VERSION "BO_HSCAN"

NS_ :

BS_:

BU_: BCM_Gp CCF_Server DDM DRDM DSM FTCM FTCMB GWM LPDM PDM PRDM PSM RFA RGTM RGTMB RLSM RPDM RRSM TBM TSTR VIM Virtual_Node WDCM Vector_XXX

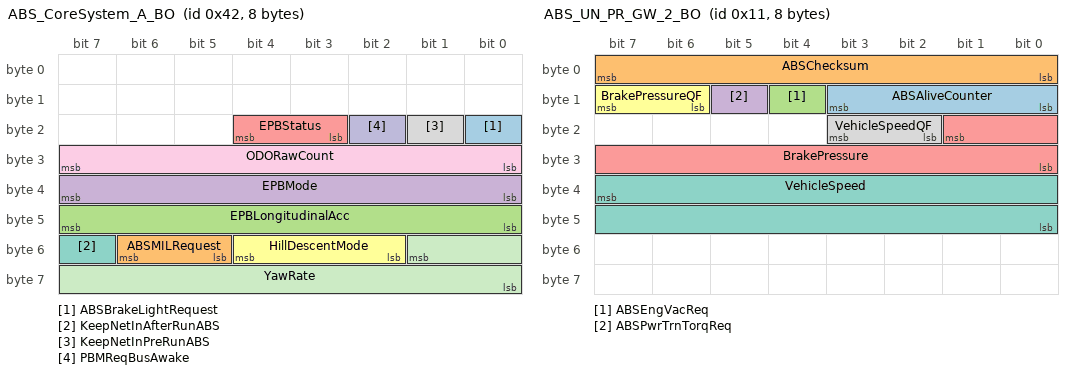
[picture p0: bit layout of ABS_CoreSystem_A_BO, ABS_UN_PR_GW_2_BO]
BO_ 66 ABS_CoreSystem_A_BO: 8 GWM
 SG_ ABSBrakeLightRequest : 16|1@0+ (1,0) [0|1] ""  BCM_Gp
 SG_ ABSMILRequest : 54|2@0+ (1,0) [0|3] ""  Vector_XXX
 SG_ EPBLongitudinalAcc : 47|8@0+ (0.1,-11) [-11|11] "m/s/s"  Vector_XXX
 SG_ EPBMode : 39|8@0+ (1,0) [0|255] ""  Vector_XXX
 SG_ EPBStatus : 20|2@0+ (1,0) [0|3] ""  BCM_Gp,DSM,LPDM,PSM,RLSM,RPDM,RRSM,TBM
 SG_ HillDescentMode : 52|3@0+ (1,0) [0|7] ""  Vector_XXX
 SG_ KeepNetInAfterRunABS : 55|1@0+ (1,0) [0|1] ""  BCM_Gp
 SG_ KeepNetInPreRunABS : 17|1@0+ (1,0) [0|1] ""  Vector_XXX
 SG_ ODORawCount : 31|8@0+ (1,0) [0|255] "Counter value"  Vector_XXX
 SG_ PBMReqBusAwake : 18|1@0+ (1,0) [0|1] ""  BCM_Gp
 SG_ YawRate : 49|10@0+ (0.2,-100) [-100|100] "Degrees/second"  BCM_Gp

BO_ 17 ABS_UN_PR_GW_2_BO: 8 GWM
 SG_ ABSAliveCounter : 11|4@0+ (1,0) [0|15] "Counter"  BCM_Gp,DSM,PSM,RGTM,VIM
 SG_ ABSChecksum : 7|8@0+ (1,0) [0|255] "CRC8 Checksum"  BCM_Gp,DSM,PSM,RGTM,VIM
 SG_ ABSEngVacReq : 12|1@0+ (1,0) [0|1] ""  BCM_Gp,DSM,PSM,RGTM,VIM
 SG_ ABSPwrTrnTorqReq : 13|1@0+ (1,0) [0|1] ""  BCM_Gp,DSM,FTCM,PSM,RGTM,VIM
 SG_ BrakePressure : 17|10@0+ (0.2,0) [0|204.6] "Bar"  BCM_Gp,DSM,LPDM,PSM,RGTM,RPDM,VIM
 SG_ BrakePressureQF : 15|2@0+ (1,0) [0|3] ""  BCM_Gp,DSM,PSM,RGTM,VIM
 SG_ VehicleSpeed : 39|16@0+ (0.01,0) [0|320] "kph"  BCM_Gp,DDM,DRDM,DSM,FTCM,LPDM,PDM,PRDM,PSM,RFA,RGTM,RGTMB,RLSM,RPDM,RRSM,TBM,VIM
 SG_ VehicleSpeedQF : 19|2@0+ (1,0) [0|3] ""  BCM_Gp,DDM,DRDM,DSM,FTCM,PDM,PRDM,PSM,RFA,RGTM,RGTMB,RLSM,RRSM,VIM

BO_ 1281 BCM_NM501LS: 8 BCM_Gp
 SG_ NMmessageBCMLS : 7|64@0+ (1,0) [0|1.84467440737096E+019] ""  Virtual_Node

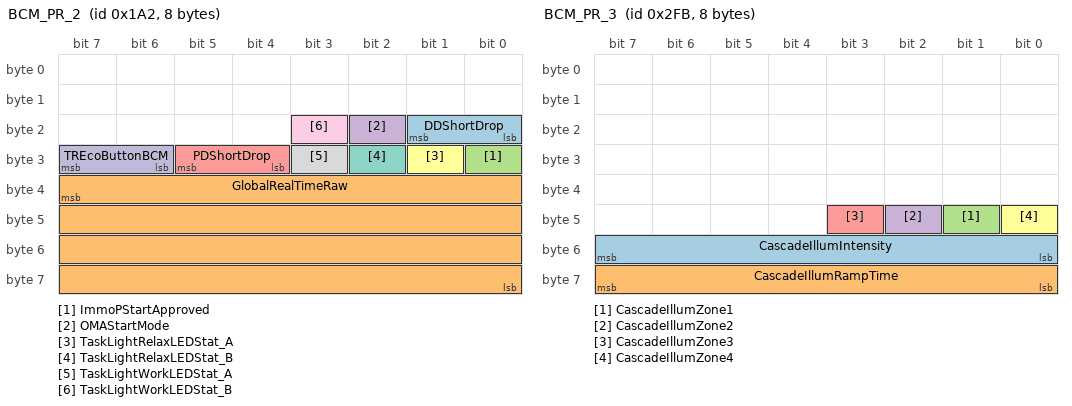
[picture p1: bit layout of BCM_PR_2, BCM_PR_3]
BO_ 418 BCM_PR_2: 8 BCM_Gp
 SG_ DDShortDrop : 17|2@0+ (1,0) [0|3] ""  DDM
 SG_ GlobalRealTimeRaw : 39|32@0+ (1,0) [0|4294967295] ""  GWM
 SG_ ImmoPStartApproved : 24|1@0+ (1,0) [0|1] ""  RFA
 SG_ OMAStartMode : 18|1@0+ (1,0) [0|1] ""  RFA
 SG_ PDShortDrop : 29|2@0+ (1,0) [0|3] ""  PDM
 SG_ TaskLightRelaxLEDStat_A : 25|1@0+ (1,0) [0|1] ""  DRDM,PRDM
 SG_ TaskLightRelaxLEDStat_B : 26|1@0+ (1,0) [0|1] ""  DRDM,PRDM
 SG_ TaskLightWorkLEDStat_A : 27|1@0+ (1,0) [0|1] ""  DRDM,PRDM
 SG_ TaskLightWorkLEDStat_B : 19|1@0+ (1,0) [0|1] ""  DRDM,PRDM
 SG_ TREcoButtonBCM : 31|2@0+ (1,0) [0|3] ""  GWM

BO_ 763 BCM_PR_3: 8 BCM_Gp
 SG_ CascadeIllumIntensity : 55|8@0+ (0.3937,0) [0|99.9998] "Backlight Intensity %"  Virtual_Node
 SG_ CascadeIllumRampTime : 63|8@0+ (10,0) [0|2540] "mSec"  Virtual_Node
 SG_ CascadeIllumZone1 : 41|1@0+ (1,0) [0|1] ""  Virtual_Node
 SG_ CascadeIllumZone2 : 42|1@0+ (1,0) [0|1] ""  Virtual_Node
 SG_ CascadeIllumZone3 : 43|1@0+ (1,0) [0|1] ""  Virtual_Node
 SG_ CascadeIllumZone4 : 40|1@0+ (1,0) [0|1] ""  Virtual_Node

BO_ 255 BCM_PR_GW_1: 8 BCM_Gp
 SG_ CarMode : 27|4@0+ (1,0) [0|15] ""  DDM,DRDM,DSM,GWM,PDM,PRDM,PSM,RFA,RGTM,RGTMB,RLSM,RRSM
 SG_ CentralLockLastCmdOrig : 55|4@0+ (1,0) [0|15] ""  DDM,DRDM,GWM,PDM,PRDM,RFA
 SG_ DIFunctionStatus : 44|5@0+ (1,0) [0|31] ""  GWM
 SG_ DirectionIndicationSwitch : 47|3@0+ (1,0) [0|7] ""  GWM
 SG_ ExtLgtAutoTellTaleRq : 33|2@0+ (1,0) [0|3] ""  GWM
 SG_ HeadlampSequenceReq : 50|3@0+ (1,0) [0|7] ""  GWM
 SG_ MainBeamIndication : 51|1@0+ (1,0) [0|1] ""  GWM
 SG_ MHSwitchStatusBCM : 59|2@0+ (1,0) [0|3] ""  GWM
 SG_ PowerMode : 20|5@0+ (1,0) [0|31] ""  DDM,DRDM,DSM,FTCM,FTCMB,GWM,LPDM,PDM,PRDM,PSM,RFA,RGTM,RGTMB,RLSM,RPDM,RRSM,TBM,VIM,WDCM
 SG_ PowerModeAliveCounter : 11|4@0+ (1,0) [0|15] "Counter"  GWM
 SG_ PowerModeChecksum : 7|8@0+ (1,0) [0|255] "Counter"  GWM
 SG_ PowerModeQF : 22|2@0+ (1,0) [0|3] ""  DDM,DRDM,GWM,PDM,PRDM
 SG_ RemoteEngStartDrivPres : 31|1@0+ (1,0) [0|1] ""  GWM
 SG_ RemoteFunctionStatus : 15|4@0+ (1,0) [3|14] "Reserved"  GWM
 SG_ RemoteStartStatusMS : 23|1@0+ (1,0) [0|1] ""  DDM,GWM,PDM
 SG_ ReversedGear : 60|1@0+ (1,0) [0|1] ""  DDM,DRDM,GWM,PDM,PRDM
 SG_ RunningStandby : 56|1@0+ (1,0) [0|1] ""  DSM,FTCM,FTCMB,GWM,PSM,RGTM,RGTMB,RRSM
 SG_ StartModeReq : 63|3@0+ (1,0) [0|7] ""  GWM
 SG_ StartSwitchPressed : 57|1@0+ (1,0) [0|1] ""  GWM
 SG_ TransitState : 28|1@0+ (1,0) [0|1] ""  DDM,DRDM,FTCM,FTCMB,GWM,PDM,PRDM,RGTM,RGTMB

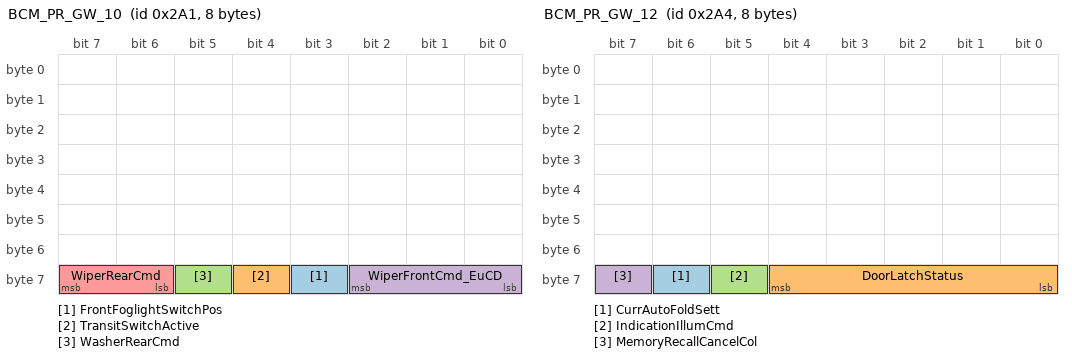
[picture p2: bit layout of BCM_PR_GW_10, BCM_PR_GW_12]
BO_ 673 BCM_PR_GW_10: 8 BCM_Gp
 SG_ FrontFoglightSwitchPos : 59|1@0+ (1,0) [0|1] ""  GWM
 SG_ TransitSwitchActive : 60|1@0+ (1,0) [0|1] ""  RRSM
 SG_ WasherRearCmd : 61|1@0+ (1,0) [0|1] ""  GWM
 SG_ WiperFrontCmd_EuCD : 58|3@0+ (1,0) [0|7] ""  GWM
 SG_ WiperRearCmd : 63|2@0+ (1,0) [0|3] ""  GWM

BO_ 675 BCM_PR_GW_11: 8 BCM_Gp
 SG_ AFSWarningLamp : 37|2@0+ (1,0) [0|3] ""  GWM
 SG_ EngineStartSeqMsgReq : 35|3@0+ (1,0) [0|7] ""  GWM
 SG_ EngineStartWarningReq : 38|1@0+ (1,0) [0|1] ""  GWM
 SG_ EngineStopReqWarning : 39|1@0+ (1,0) [0|1] ""  GWM
 SG_ EngineStopWarningMsg : 41|2@0+ (1,0) [0|3] ""  GWM
 SG_ GestureBlindStatus : 42|1@0+ (1,0) [0|1] ""  GWM
 SG_ HeadLampStatus : 43|1@0+ (1,0) [0|1] ""  GWM
 SG_ IgnitionOnWarning : 44|1@0+ (1,0) [0|1] ""  GWM
 SG_ PKeyDockedWarning : 32|1@0+ (1,0) [0|1] ""  GWM
 SG_ RearFoglightIndication : 18|2@0+ (1,0) [0|3] ""  GWM
 SG_ RheostatPositionCmd : 23|4@0+ (1,0) [0|15] "Illumination level"  DDM,GWM
 SG_ SelectParkWarning : 19|1@0+ (1,0) [0|1] ""  GWM
 SG_ SensorOverrideStatus : 24|1@0+ (1,0) [0|1] ""  GWM
 SG_ SmartKeyDeactivatedReq : 25|1@0+ (1,0) [0|1] ""  GWM
 SG_ StartAndBrakeWarning : 12|1@0+ (1,0) [0|1] ""  GWM
 SG_ StartAndClutchWarning : 13|1@0+ (1,0) [0|1] ""  GWM
 SG_ StartStop1Warning : 14|1@0+ (1,0) [0|1] ""  GWM
 SG_ StartStop2Warning : 15|1@0+ (1,0) [0|1] ""  GWM
 SG_ TgateOrGlassStatus : 26|1@0+ (1,0) [0|1] ""  GWM
 SG_ TripButtonStatus : 31|4@0+ (1,0) [0|15] ""  GWM
 SG_ ValetModeChimeAndMsgReq : 27|1@0+ (1,0) [0|1] ""  GWM
 SG_ WasherFluidLevelWarning : 16|1@0+ (1,0) [0|1] ""  GWM

BO_ 676 BCM_PR_GW_12: 8 BCM_Gp
 SG_ CurrAutoFoldSett : 62|1@0+ (1,0) [0|1] ""  DDM
 SG_ DoorLatchStatus : 60|5@0+ (1,0) [0|31] "See description"  DDM,DRDM,GWM,PDM,PRDM,RFA,RGTM,RGTMB
 SG_ IndicationIllumCmd : 61|1@0+ (1,0) [0|1] ""  DDM,PDM
 SG_ MemoryRecallCancelCol : 63|1@0+ (1,0) [0|1] ""  DDM,DSM,PDM

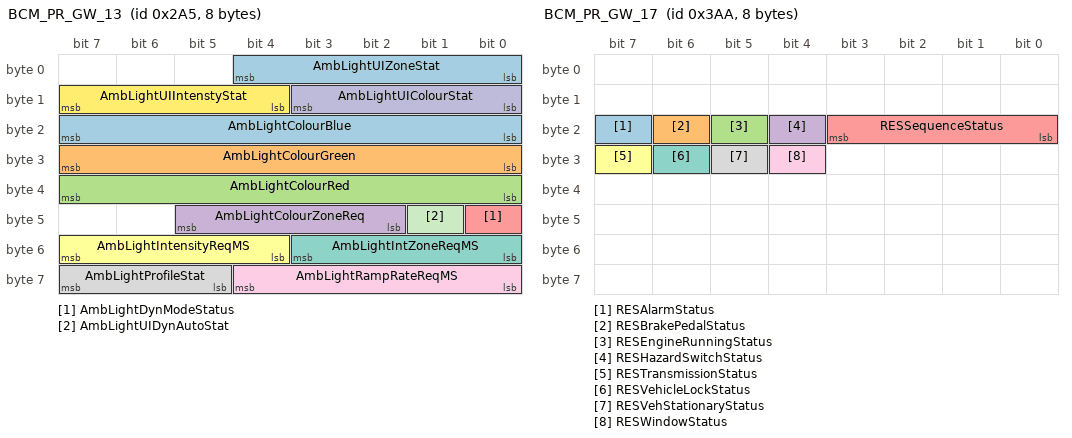
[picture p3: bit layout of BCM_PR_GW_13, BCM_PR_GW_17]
BO_ 677 BCM_PR_GW_13: 8 BCM_Gp
 SG_ AmbLightColourBlue : 23|8@0+ (1,0) [0|255] "Colour intensity"  DDM,DRDM,GWM,PDM,PRDM
 SG_ AmbLightColourGreen : 31|8@0+ (1,0) [0|255] "Colour intensity"  DDM,DRDM,GWM,PDM,PRDM
 SG_ AmbLightColourRed : 39|8@0+ (1,0) [0|255] "Colour intensity"  DDM,DRDM,GWM,PDM,PRDM
 SG_ AmbLightColourZoneReq : 45|4@0+ (1,0) [0|15] ""  DDM,DRDM,GWM,PDM,PRDM
 SG_ AmbLightDynModeStatus : 40|1@0+ (1,0) [0|1] ""  GWM
 SG_ AmbLightIntensityReqMS : 55|4@0+ (1,0) [0|15] "Light intensity"  DDM,DRDM,GWM,PDM,PRDM
 SG_ AmbLightIntZoneReqMS : 51|4@0+ (1,0) [0|15] ""  DDM,DRDM,GWM,PDM,PRDM
 SG_ AmbLightProfileStat : 63|3@0+ (1,0) [0|7] ""  DDM,DRDM,GWM,PDM,PRDM
 SG_ AmbLightRampRateReqMS : 60|5@0+ (0.2,0) [0|6.2] "Seconds"  DDM,DRDM,GWM,PDM,PRDM
 SG_ AmbLightUIColourStat : 11|4@0+ (1,0) [0|15] ""  GWM
 SG_ AmbLightUIDynAutoStat : 41|1@0+ (1,0) [0|1] ""  GWM
 SG_ AmbLightUIIntenstyStat : 15|4@0+ (1,0) [0|15] "Brightness level"  GWM
 SG_ AmbLightUIZoneStat : 4|5@0+ (1,0) [0|31] ""  GWM

BO_ 678 BCM_PR_GW_14: 8 BCM_Gp
 SG_ ComfortRlyOffImminent : 33|1@0+ (1,0) [0|1] ""  DSM,LPDM,PSM,RLSM,RPDM,RRSM
 SG_ DipBeamStatus : 34|1@0+ (1,0) [0|1] ""  GWM
 SG_ DipMirrSetngApp : 35|1@0+ (1,0) [0|1] ""  Virtual_Node
 SG_ ExtLightSetngAppl : 44|1@0+ (1,0) [0|1] ""  Virtual_Node
 SG_ GotoEntryExitPos : 37|2@0+ (1,0) [0|3] ""  DSM
 SG_ HFSStatus : 39|2@0+ (1,0) [0|3] ""  GWM
 SG_ HRWStatus : 47|2@0+ (1,0) [0|3] ""  GWM
 SG_ IgnoreLatchOnUnlock : 45|1@0+ (1,0) [0|1] ""  RFA
 SG_ IntLightSetngAppl : 43|1@0+ (1,0) [0|1] ""  Virtual_Node
 SG_ POTailgateLatchStatus : 12|1@0+ (1,0) [0|1] ""  RFA,RGTM,RGTMB
 SG_ POTLatchStatLwrLHS : 13|1@0+ (1,0) [0|1] ""  RGTM,RGTMB
 SG_ POTLatchStatLwrRHS : 14|1@0+ (1,0) [0|1] ""  RGTM,RGTMB
 SG_ PrivateLockStatus : 15|1@0+ (1,0) [0|1] ""  RFA,RGTM,RGTMB
 SG_ PwrTGOpenCloseReq : 19|4@0+ (1,0) [0|15] ""  RGTM,RGTMB
 SG_ PwrTGOpenCloseReqLwr : 23|4@0+ (1,0) [0|15] ""  RGTM,RGTMB
 SG_ PwrTGUpperAndLwrReq : 27|4@0+ (1,0) [0|15] ""  RGTM,RGTMB
 SG_ TrailerFogLights : 28|1@0+ (1,0) [0|1] ""  TBM
 SG_ TrailerReverseLights : 29|1@0+ (1,0) [0|1] ""  TBM
 SG_ TrailerTailLightsL : 30|1@0+ (1,0) [0|1] ""  TBM
 SG_ TrailerTailLightsR : 31|1@0+ (1,0) [0|1] ""  TBM
 SG_ UserStartReq : 32|1@0+ (1,0) [0|1] ""  GWM

BO_ 679 BCM_PR_GW_15: 8 BCM_Gp
 SG_ MinuteCounter : 39|32@0+ (1,0) [0|4294967295] ""  GWM

BO_ 681 BCM_PR_GW_16: 8 BCM_Gp
 SG_ UserSetTimeDate : 23|48@0+ (1,0) [0|281474976710655] ""  GWM

BO_ 938 BCM_PR_GW_17: 8 BCM_Gp
 SG_ RESAlarmStatus : 23|1@0+ (1,0) [0|1] ""  GWM
 SG_ RESBrakePedalStatus : 22|1@0+ (1,0) [0|1] ""  GWM
 SG_ RESEngineRunningStatus : 21|1@0+ (1,0) [0|1] ""  GWM
 SG_ RESHazardSwitchStatus : 20|1@0+ (1,0) [0|1] ""  GWM
 SG_ RESSequenceStatus : 19|4@0+ (1,0) [1|14] "reserved"  GWM
 SG_ RESTransmissionStatus : 31|1@0+ (1,0) [0|1] ""  GWM
 SG_ RESVehicleLockStatus : 30|1@0+ (1,0) [0|1] ""  GWM
 SG_ RESVehStationaryStatus : 29|1@0+ (1,0) [0|1] ""  GWM
 SG_ RESWindowStatus : 28|1@0+ (1,0) [0|1] ""  GWM

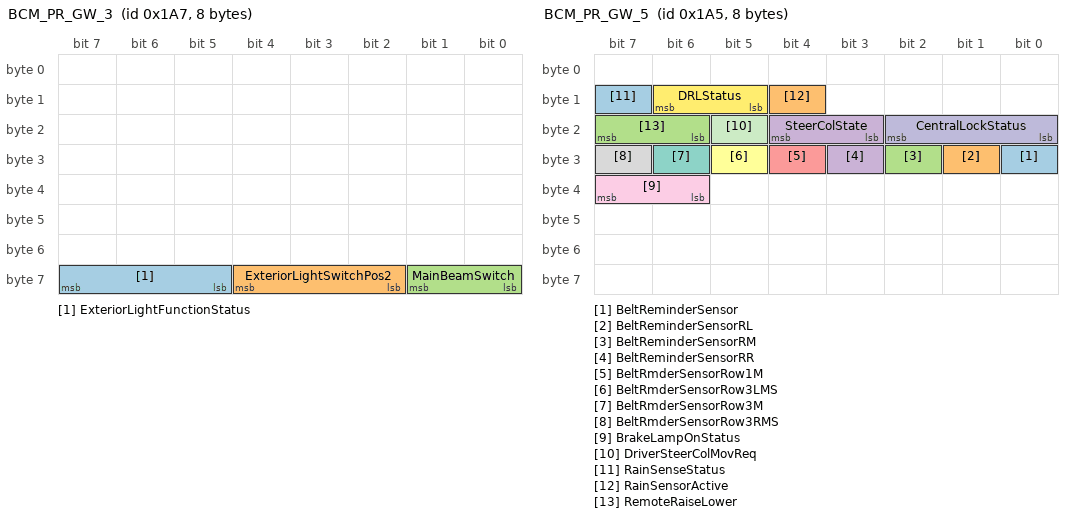
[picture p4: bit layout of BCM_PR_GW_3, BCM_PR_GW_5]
BO_ 423 BCM_PR_GW_3: 8 BCM_Gp
 SG_ ExteriorLightFunctionStatus : 63|3@0+ (1,0) [0|7] ""  GWM
 SG_ ExteriorLightSwitchPos2 : 60|3@0+ (1,0) [5|7] "Unsed"  GWM
 SG_ MainBeamSwitch : 57|2@0+ (1,0) [0|3] ""  GWM

BO_ 420 BCM_PR_GW_4: 8 BCM_Gp
 SG_ DiagHeadLightFault : 29|1@0+ (1,0) [0|1] ""  GWM
 SG_ DirectionIndSwitchPos : 33|2@0+ (1,0) [0|3] ""  GWM
 SG_ FLDirectionIndicatorBulbFail : 1|2@0+ (1,0) [0|3] ""  GWM
 SG_ FRDirectionIndicatorBulbFail : 3|2@0+ (1,0) [0|3] ""  GWM
 SG_ LeftStopLampBulbFailure : 5|2@0+ (1,0) [0|3] ""  GWM
 SG_ LowBeamFailureLH : 16|1@0+ (1,0) [0|1] ""  GWM
 SG_ LowBeamFailureRH : 17|1@0+ (1,0) [0|1] ""  GWM
 SG_ LSMAlsDippedBeamReqB : 18|1@0+ (1,0) [0|1] ""  GWM
 SG_ MainBeamStatus : 20|2@0+ (1,0) [0|3] ""  GWM
 SG_ NaturalLight : 21|1@0+ (1,0) [0|1] ""  GWM
 SG_ RightStopLampBulbFailure : 7|2@0+ (1,0) [0|3] ""  GWM
 SG_ RLDirectionIndicatorBulbFail : 9|2@0+ (1,0) [0|3] ""  GWM
 SG_ RLPositionLampBulbFailure : 11|2@0+ (1,0) [0|3] ""  GWM
 SG_ RRDirectionIndicatorBulbFail : 13|2@0+ (1,0) [0|3] ""  GWM
 SG_ RRPositionLampBulbFailure : 15|2@0+ (1,0) [0|3] ""  GWM
 SG_ SCLWarningReq : 23|2@0+ (1,0) [0|3] ""  GWM
 SG_ SidelightStatus : 25|2@0+ (1,0) [0|3] ""  GWM
 SG_ SupMainBeamRoutineReq : 31|2@0+ (1,0) [0|3] ""  GWM
 SG_ WipeSpeedRainSensor : 28|3@0+ (1,0) [0|7] ""  GWM

BO_ 421 BCM_PR_GW_5: 8 BCM_Gp
 SG_ BeltReminderSensor : 24|1@0+ (1,0) [0|1] ""  GWM,LPDM,PSM,RPDM
 SG_ BeltReminderSensorRL : 25|1@0+ (1,0) [0|1] ""  DSM,GWM,LPDM,PSM,RLSM,RPDM
 SG_ BeltReminderSensorRM : 26|1@0+ (1,0) [0|1] ""  DSM,GWM,LPDM,PSM,RLSM,RPDM,RRSM
 SG_ BeltReminderSensorRR : 27|1@0+ (1,0) [0|1] ""  DSM,GWM,LPDM,PSM,RPDM,RRSM
 SG_ BeltRmderSensorRow1M : 28|1@0+ (1,0) [0|1] ""  GWM
 SG_ BeltRmderSensorRow3LMS : 29|1@0+ (1,0) [0|1] ""  DSM,GWM,PSM
 SG_ BeltRmderSensorRow3M : 30|1@0+ (1,0) [0|1] ""  GWM
 SG_ BeltRmderSensorRow3RMS : 31|1@0+ (1,0) [0|1] ""  DSM,GWM,PSM
 SG_ BrakeLampOnStatus : 39|2@0+ (1,0) [0|3] ""  GWM
 SG_ CentralLockStatus : 18|3@0+ (1,0) [5|7] "Unused (Undefined)"  GWM,RFA,RGTM,RGTMB
 SG_ DriverSteerColMovReq : 21|1@0+ (1,0) [0|1] ""  GWM
 SG_ DRLStatus : 14|2@0+ (1,0) [0|3] ""  GWM
 SG_ RainSenseStatus : 15|1@0+ (1,0) [0|1] ""  GWM
 SG_ RainSensorActive : 12|1@0+ (1,0) [0|1] ""  GWM
 SG_ RemoteRaiseLower : 23|2@0+ (1,0) [0|3] ""  GWM
 SG_ SteerColState : 20|2@0+ (1,0) [0|3] ""  GWM

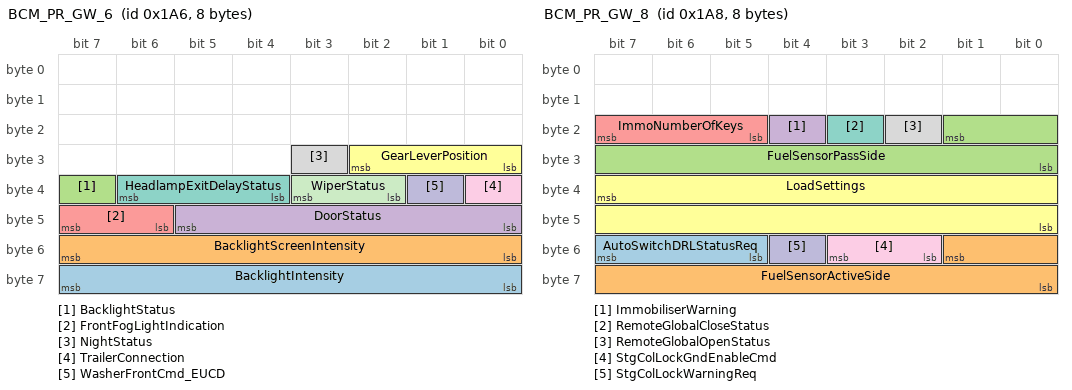
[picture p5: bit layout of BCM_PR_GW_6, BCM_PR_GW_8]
BO_ 422 BCM_PR_GW_6: 8 BCM_Gp
 SG_ BacklightIntensity : 63|8@0+ (0.3937,0) [0|99.9998] "Backlight Intensity %"  DDM,DRDM,DSM,GWM,PDM,PRDM,PSM,RLSM,RRSM
 SG_ BacklightScreenIntensity : 55|8@0+ (0.3937,0) [0|99.9998] "Backlight Intensity %"  GWM
 SG_ BacklightStatus : 39|1@0+ (1,0) [0|1] ""  DDM,DRDM,DSM,GWM,PDM,PRDM,PSM,RLSM,RRSM
 SG_ DoorStatus : 45|6@0+ (1,0) [0|63] "See Description"  DDM,DRDM,DSM,FTCM,GWM,LPDM,PDM,PRDM,PSM,RFA,RGTM,RGTMB,RLSM,RPDM,RRSM,TBM,WDCM
 SG_ FrontFogLightIndication : 47|2@0+ (1,0) [0|3] ""  GWM
 SG_ GearLeverPosition : 26|3@0+ (1,0) [0|7] ""  DDM,DRDM,GWM,PDM,PRDM
 SG_ HeadlampExitDelayStatus : 38|3@0+ (1,0) [6|7] "Unused (Undefined)"  GWM
 SG_ NightStatus : 27|1@0+ (1,0) [0|1] ""  GWM
 SG_ TrailerConnection : 32|1@0+ (1,0) [0|1] ""  GWM,TBM
 SG_ WasherFrontCmd_EUCD : 33|1@0+ (1,0) [0|1] ""  GWM
 SG_ WiperStatus : 35|2@0+ (1,0) [0|3] ""  GWM

BO_ 935 BCM_PR_GW_7: 8 BCM_Gp
 SG_ AmbientLightValueRLS : 39|8@0+ (1,0) [0|253] "Counts"  GWM
 SG_ AutoBlindEnableStatus : 7|1@0+ (1,0) [0|1] ""  GWM
 SG_ BatteryStateText : 31|3@0+ (1,0) [0|7] ""  GWM
 SG_ BCM_EPBWarningLamp : 12|1@0+ (1,0) [0|1] ""  GWM
 SG_ BrakeFluidLevelWarning : 13|1@0+ (1,0) [0|1] ""  GWM
 SG_ BrakePadWearLampReq : 14|1@0+ (1,0) [0|1] ""  GWM
 SG_ CarModeText : 18|3@0+ (1,0) [0|7] ""  GWM
 SG_ CoolantLevel : 15|1@0+ (1,0) [0|1] ""  GWM
 SG_ HomeSafeLightInd : 19|1@0+ (1,0) [0|1] ""  GWM
 SG_ OdometerBackUp_BCM : 47|24@0+ (1,0) [0|16777215] ""  GWM
 SG_ ParkClimateReq : 20|1@0+ (1,0) [0|1] ""  GWM
 SG_ PosLightInd : 21|1@0+ (1,0) [0|1] ""  GWM
 SG_ SunroofOpen : 28|1@0+ (1,0) [0|1] ""  GWM
 SG_ TrailerLightTestActive : 22|1@0+ (1,0) [0|1] ""  GWM
 SG_ TRStatus : 27|2@0+ (1,0) [0|3] ""  DSM,GWM,PSM,RLSM
 SG_ ValetStatus : 23|1@0+ (1,0) [0|1] ""  GWM
 SG_ WasherFluidLevelLow : 24|1@0+ (1,0) [0|1] ""  GWM
 SG_ WashingCycleActive_s : 25|1@0+ (1,0) [0|1] ""  GWM

BO_ 424 BCM_PR_GW_8: 8 BCM_Gp
 SG_ AutoSwitchDRLStatusReq : 55|3@0+ (1,0) [0|7] ""  GWM
 SG_ FuelSensorActiveSide : 49|10@0+ (1,0) [0|1023] "Raw ADC reading"  GWM
 SG_ FuelSensorPassSide : 17|10@0+ (1,0) [0|1023] "Raw ADC reading"  GWM
 SG_ ImmobiliserWarning : 20|1@0+ (1,0) [0|1] ""  GWM
 SG_ ImmoNumberOfKeys : 23|3@0+ (1,0) [0|7] ""  GWM
 SG_ LoadSettings : 39|16@0+ (1,0) [0|65535] ""  DDM,DRDM,GWM,PDM,PRDM,RRSM
 SG_ RemoteGlobalCloseStatus : 19|1@0+ (1,0) [0|1] ""  GWM
 SG_ RemoteGlobalOpenStatus : 18|1@0+ (1,0) [0|1] ""  GWM
 SG_ StgColLockGndEnableCmd : 51|2@0+ (1,0) [0|3] ""  GWM
 SG_ StgColLockWarningReq : 52|1@0+ (1,0) [0|1] ""  GWM

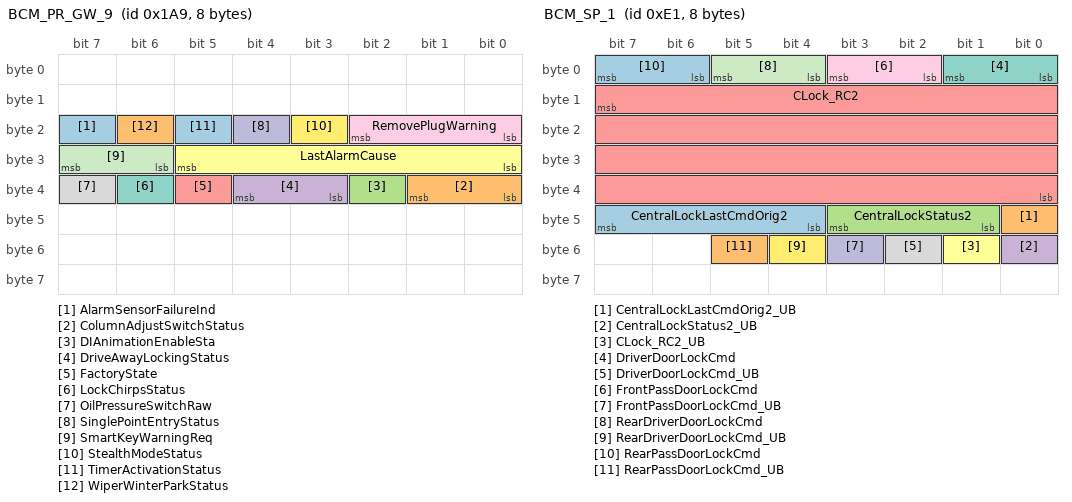
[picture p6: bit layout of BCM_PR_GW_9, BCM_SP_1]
BO_ 425 BCM_PR_GW_9: 8 BCM_Gp
 SG_ AlarmSensorFailureInd : 23|1@0+ (1,0) [0|1] ""  GWM
 SG_ ColumnAdjustSwitchStatus : 33|2@0+ (1,0) [0|3] ""  GWM
 SG_ DIAnimationEnableSta : 34|1@0+ (1,0) [0|1] ""  GWM
 SG_ DriveAwayLockingStatus : 36|2@0+ (1,0) [0|3] ""  GWM
 SG_ FactoryState : 37|1@0+ (1,0) [0|1] ""  GWM
 SG_ LastAlarmCause : 29|6@0+ (1,0) [23|63] "Unused"  GWM
 SG_ LockChirpsStatus : 38|1@0+ (1,0) [0|1] ""  GWM
 SG_ OilPressureSwitchRaw : 39|1@0+ (1,0) [0|1] ""  GWM
 SG_ RemovePlugWarning : 18|3@0+ (1,0) [0|7] ""  GWM
 SG_ SinglePointEntryStatus : 20|1@0+ (1,0) [0|1] ""  GWM
 SG_ SmartKeyWarningReq : 31|2@0+ (1,0) [0|3] ""  GWM
 SG_ StealthModeStatus : 19|1@0+ (1,0) [0|1] ""  GWM
 SG_ TimerActivationStatus : 21|1@0+ (1,0) [0|1] ""  GWM
 SG_ WiperWinterParkStatus : 22|1@0+ (1,0) [0|1] ""  GWM

BO_ 225 BCM_SP_1: 8 BCM_Gp
 SG_ CentralLockLastCmdOrig2 : 47|4@0+ (1,0) [0|15] ""  DDM,DRDM,PDM,PRDM,RGTM,RGTMB
 SG_ CentralLockLastCmdOrig2_UB : 40|1@0+ (1,0) [0|1] ""  DDM,DRDM,PDM,PRDM,RGTM,RGTMB
 SG_ CentralLockStatus2 : 43|3@0+ (1,0) [5|7] "Unused (Undefined)"  DDM,DRDM,PDM,PRDM,RGTM,RGTMB
 SG_ CentralLockStatus2_UB : 48|1@0+ (1,0) [0|1] ""  DDM,DRDM,PDM,PRDM,RGTM,RGTMB
 SG_ CLock_RC2 : 15|32@0+ (1,0) [0|4294967295] ""  DDM,DRDM,PDM,PRDM,RGTM,RGTMB
 SG_ CLock_RC2_UB : 49|1@0+ (1,0) [0|1] ""  DDM,DRDM,PDM,PRDM,RGTM,RGTMB
 SG_ DriverDoorLockCmd : 1|2@0+ (1,0) [0|3] ""  DDM,DRDM,PDM,PRDM,RGTM,RGTMB
 SG_ DriverDoorLockCmd_UB : 50|1@0+ (1,0) [0|1] ""  DDM,DRDM,PDM,PRDM,RGTM,RGTMB
 SG_ FrontPassDoorLockCmd : 3|2@0+ (1,0) [0|3] ""  DDM,DRDM,PDM,PRDM,RGTM,RGTMB
 SG_ FrontPassDoorLockCmd_UB : 51|1@0+ (1,0) [0|1] ""  DDM,DRDM,PDM,PRDM,RGTM,RGTMB
 SG_ RearDriverDoorLockCmd : 5|2@0+ (1,0) [0|3] ""  DDM,DRDM,PDM,PRDM,RGTM,RGTMB
 SG_ RearDriverDoorLockCmd_UB : 52|1@0+ (1,0) [0|1] ""  DDM,DRDM,PDM,PRDM,RGTM,RGTMB
 SG_ RearPassDoorLockCmd : 7|2@0+ (1,0) [0|3] ""  DDM,DRDM,PDM,PRDM,RGTM,RGTMB
 SG_ RearPassDoorLockCmd_UB : 53|1@0+ (1,0) [0|1] ""  DDM,DRDM,PDM,PRDM,RGTM,RGTMB

BO_ 226 BCM_SP_2: 8 BCM_Gp
 SG_ ImmoAuthPKeyMainReq : 7|48@0+ (1,0) [0|281474976710655] ""  RFA
 SG_ ImmoAuthPKeyMainReq_UB : 48|1@0+ (1,0) [0|1] ""  RFA

BO_ 227 BCM_SP_3: 8 BCM_Gp
 SG_ CLockCmd_2 : 39|8@0+ (1,0) [0|255] "See Description for encoding"  DDM,DRDM,PDM,PRDM
 SG_ CLockCmd_2_UB : 25|1@0+ (1,0) [0|1] ""  DDM,DRDM,PDM,PRDM
 SG_ ePEPSLockResult : 1|2@0+ (1,0) [0|3] ""  Vector_XXX
 SG_ ePEPSLockResult_UB : 26|1@0+ (1,0) [0|1] ""  Vector_XXX
 SG_ GlobalWindowReq : 3|2@0+ (1,0) [0|3] ""  DDM,DRDM,PDM,PRDM
 SG_ GlobalWindowReq_UB : 4|1@0+ (1,0) [0|1] ""  DDM,DRDM,PDM,PRDM
 SG_ LocationOfKeysRequest : 30|1@0+ (1,0) [0|1] ""  Virtual_Node
 SG_ LocationOfKeysRequest_UB : 31|1@0+ (1,0) [0|1] ""  Virtual_Node
 SG_ PKExteriorScanReq : 9|2@0+ (1,0) [0|3] ""  RFA
 SG_ PKExteriorScanReq_UB : 28|1@0+ (1,0) [0|1] ""  RFA
 SG_ PKInteriorScanReq : 10|1@0+ (1,0) [0|1] ""  RFA
 SG_ PKInteriorScanReq_UB : 29|1@0+ (1,0) [0|1] ""  RFA
 SG_ POTUpperAndLowerReq : 13|3@0+ (1,0) [0|7] ""  RGTM,RGTMB
 SG_ POTUpperAndLowerReq_UB : 45|1@0+ (1,0) [0|1] ""  RGTM,RGTMB
 SG_ PowerTailgateReq : 7|3@0+ (1,0) [0|7] ""  RGTM,RGTMB
 SG_ PowerTailgateReq_UB : 46|1@0+ (1,0) [0|1] ""  RGTM,RGTMB
 SG_ PowerTailgateReqLwr : 22|3@0+ (1,0) [0|7] ""  RGTM,RGTMB
 SG_ PowerTailgateReqLwr_UB : 47|1@0+ (1,0) [0|1] ""  RGTM,RGTMB
 SG_ PuddleLightActivation : 23|1@0+ (1,0) [0|1] ""  DDM,DRDM,PDM,PRDM
 SG_ PuddleLightActivation_UB : 24|1@0+ (1,0) [0|1] ""  DDM,DRDM,PDM,PRDM
 SG_ RFARequestAck : 19|4@0+ (1,0) [0|15] ""  Virtual_Node
 SG_ RFARequestAck_UB : 27|1@0+ (1,0) [0|1] ""  Virtual_Node
 SG_ RKELockResult : 15|2@0+ (1,0) [0|3] ""  Virtual_Node
 SG_ RKELockResult_UB : 44|1@0+ (1,0) [0|1] ""  Virtual_Node

BO_ 502 BCM_SP_5: 8 BCM_Gp
 SG_ CLock_RC : 39|32@0+ (1,0) [0|4294967295] ""  DDM,DRDM,PDM,PRDM
 SG_ CLock_RC_UB : 24|1@0+ (1,0) [0|1] ""  DDM,DRDM,PDM,PRDM

BO_ 230 BCM_SP_GW_2: 8 BCM_Gp
 SG_ AlarmModeMS : 44|2@0+ (1,0) [0|3] ""  DDM,DRDM,FTCM,FTCMB,GWM,PDM,PRDM,RFA,RGTM,RGTMB
 SG_ AlarmModeMS_UB : 42|1@0+ (1,0) [0|1] ""  DDM,DRDM,FTCM,FTCMB,GWM,PDM,PRDM,RFA,RGTM,RGTMB
 SG_ DirectionIndication : 60|2@0+ (1,0) [0|3] ""  DDM,GWM,PDM
 SG_ DirectionIndication_UB : 48|1@0+ (1,0) [0|1] ""  DDM,GWM,PDM
 SG_ DirectionIndicationINST : 63|2@0+ (1,0) [0|3] ""  GWM
 SG_ DirectionIndicationINST_UB : 49|1@0+ (1,0) [0|1] ""  GWM
 SG_ ImmoFailureInd : 38|3@0+ (1,0) [0|7] ""  GWM
 SG_ ImmoFailureInd_UB : 39|1@0+ (1,0) [0|1] ""  GWM
 SG_ InteriorLightMode : 51|1@0+ (1,0) [0|1] ""  GWM
 SG_ InteriorLightMode_UB : 46|1@0+ (1,0) [0|1] ""  GWM
 SG_ KeyWarningInd : 55|2@0+ (1,0) [0|3] ""  GWM
 SG_ KeyWarningInd_UB : 45|1@0+ (1,0) [0|1] ""  GWM
 SG_ LDWSwitchReq : 34|1@0+ (1,0) [0|1] ""  GWM
 SG_ LDWSwitchReq_UB : 35|1@0+ (1,0) [0|1] ""  GWM
 SG_ LowBeamIndication : 53|1@0+ (1,0) [0|1] ""  GWM
 SG_ LowBeamIndication_UB : 52|1@0+ (1,0) [0|1] ""  GWM
 SG_ TrailerDILeft : 58|1@0+ (1,0) [0|1] ""  GWM,TBM
 SG_ TrailerDILeft_UB : 47|1@0+ (1,0) [0|1] ""  GWM,TBM
 SG_ TrailerDirectionInd : 61|1@0+ (1,0) [0|1] ""  GWM
 SG_ TrailerDirectionInd_UB : 50|1@0+ (1,0) [0|1] ""  GWM
 SG_ TrailerDIRight : 57|1@0+ (1,0) [0|1] ""  GWM,TBM
 SG_ TrailerDIRight_UB : 32|1@0+ (1,0) [0|1] ""  GWM,TBM
 SG_ TrailerStopLamp : 56|1@0+ (1,0) [0|1] ""  GWM,TBM
 SG_ TrailerStopLamp_UB : 33|1@0+ (1,0) [0|1] ""  GWM,TBM
 SG_ WakeShutDownEnableSta : 40|1@0+ (1,0) [0|1] ""  GWM
 SG_ WakeShutDownEnableSta_UB : 41|1@0+ (1,0) [0|1] ""  GWM

BO_ 794 BMS_PR_GW_1_BO: 8 GWM
 SG_ BSBattSOC : 54|7@0+ (1,0) [0|100] "%"  BCM_Gp
 SG_ BSBattVoltage : 63|8@0+ (0.0625,0) [0|15.9375] "V"  BCM_Gp

BO_ 1412 BO_CAN_NodeDDM_NM: 8 DDM

BO_ 1414 BO_CAN_NodeDRDM_NM: 8 DRDM

BO_ 1438 BO_CAN_NodeGWM_NM: 8 GWM

BO_ 1310 BO_CAN_NodeGWM_OSEK_NM: 8 GWM

BO_ 1413 BO_CAN_NodePDM_NM: 8 PDM

BO_ 1407 BO_CAN_NodeVirtual_OSEK_NM: 8 Virtual_Node

BO_ 1415 BO_CAN_PRDM_NM: 8 PRDM

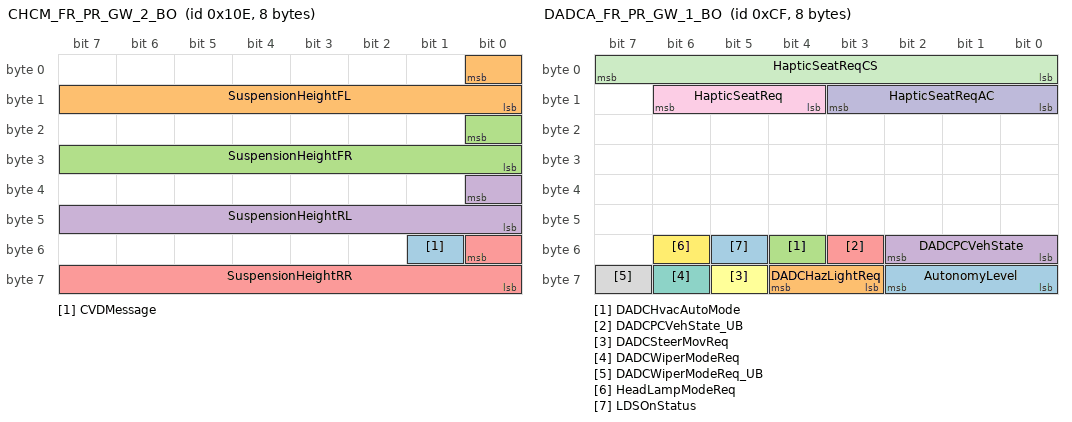
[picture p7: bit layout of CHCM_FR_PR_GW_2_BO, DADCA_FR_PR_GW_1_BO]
BO_ 270 CHCM_FR_PR_GW_2_BO: 8 GWM
 SG_ CVDMessage : 49|1@0+ (1,0) [0|1] ""  Vector_XXX
 SG_ SuspensionHeightFL : 0|9@0+ (1,-200) [-200|300] "mm"  BCM_Gp
 SG_ SuspensionHeightFR : 16|9@0+ (1,-200) [-200|300] "mm"  BCM_Gp
 SG_ SuspensionHeightRL : 32|9@0+ (1,-200) [-200|300] "mm"  BCM_Gp
 SG_ SuspensionHeightRR : 48|9@0+ (1,-200) [-200|300] "mm"  BCM_Gp

BO_ 207 DADCA_FR_PR_GW_1_BO: 8 GWM
 SG_ AutonomyLevel : 58|3@0+ (1,0) [0|7] ""  Vector_XXX
 SG_ DADCHazLightReq : 60|2@0+ (1,0) [0|3] ""  BCM_Gp
 SG_ DADCHvacAutoMode : 52|1@0+ (1,0) [0|1] ""  Vector_XXX
 SG_ DADCPCVehState : 50|3@0+ (1,0) [0|7] ""  BCM_Gp,DDM,DRDM,DSM,PDM,PRDM,RLSM,RRSM
 SG_ DADCPCVehState_UB : 51|1@0+ (1,0) [0|1] ""  BCM_Gp,DDM,DRDM,DSM,PDM,PRDM,RLSM,RRSM
 SG_ DADCSteerMovReq : 61|1@0+ (1,0) [0|1] ""  BCM_Gp
 SG_ DADCWiperModeReq : 62|1@0+ (1,0) [0|1] ""  BCM_Gp
 SG_ DADCWiperModeReq_UB : 63|1@0+ (1,0) [0|1] ""  BCM_Gp
 SG_ HapticSeatReq : 14|3@0+ (1,0) [0|7] ""  DSM
 SG_ HapticSeatReqAC : 11|4@0+ (1,0) [0|15] "Counter value"  DSM
 SG_ HapticSeatReqCS : 7|8@0+ (1,0) [0|255] "checksum"  DSM
 SG_ HeadLampModeReq : 54|1@0+ (1,0) [0|1] ""  BCM_Gp
 SG_ LDSOnStatus : 53|1@0+ (1,0) [0|1] ""  Vector_XXX

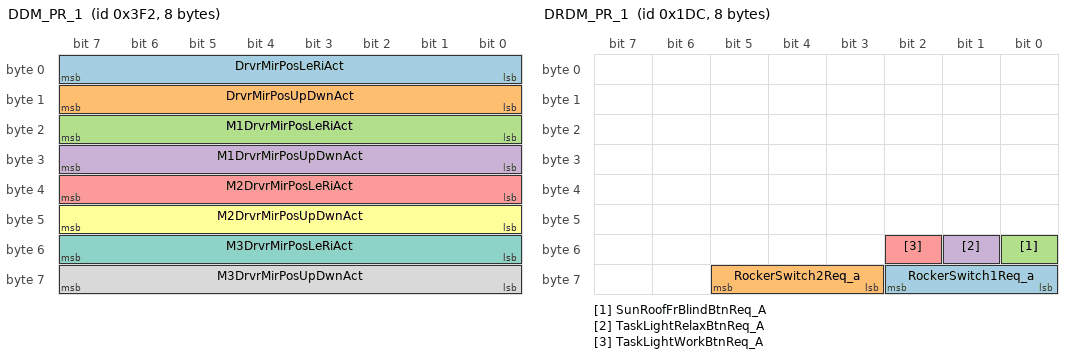
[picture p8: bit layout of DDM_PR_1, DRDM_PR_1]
BO_ 1010 DDM_PR_1: 8 DDM
 SG_ DrvrMirPosLeRiAct : 7|8@0+ (1,0) [0|255] "Mirror Position"  Virtual_Node
 SG_ DrvrMirPosUpDwnAct : 15|8@0+ (1,0) [0|255] "Mirror Position"  Virtual_Node
 SG_ M1DrvrMirPosLeRiAct : 23|8@0+ (1,0) [0|255] "Mirror Position"  Virtual_Node
 SG_ M1DrvrMirPosUpDwnAct : 31|8@0+ (1,0) [0|255] "Mirror Position"  Virtual_Node
 SG_ M2DrvrMirPosLeRiAct : 39|8@0+ (1,0) [0|255] "Mirror Position"  Virtual_Node
 SG_ M2DrvrMirPosUpDwnAct : 47|8@0+ (1,0) [0|255] "Mirror Position"  Virtual_Node
 SG_ M3DrvrMirPosLeRiAct : 55|8@0+ (1,0) [0|255] "Mirror Position"  Virtual_Node
 SG_ M3DrvrMirPosUpDwnAct : 63|8@0+ (1,0) [0|255] "Mirror Position"  Virtual_Node

BO_ 498 DDM_PR_GW_1: 8 DDM
 SG_ AccessMode : 38|1@0+ (1,0) [0|1] ""  GWM
 SG_ ChildLockCmd : 43|1@0+ (1,0) [0|1] ""  DRDM,PRDM
 SG_ DDClawSwitchStatus : 44|1@0+ (1,0) [0|1] ""  PDM
 SG_ DDMReqBusAwake : 45|1@0+ (1,0) [0|1] ""  GWM
 SG_ DDMSetngAppl : 46|1@0+ (1,0) [0|1] ""  Virtual_Node
 SG_ DDoorLatchStatus : 57|2@0+ (1,0) [0|3] "See Description"  BCM_Gp,LPDM,RPDM,TBM
 SG_ DDPawlSwitchStatus : 47|1@0+ (1,0) [0|1] ""  PDM
 SG_ DriverDoorSCAStatus : 55|2@0+ (1,0) [0|3] ""  PDM
 SG_ DrvMirrorStatus : 60|3@0+ (1,0) [0|7] ""  GWM
 SG_ DZMDrivLeftHmiOp : 63|3@0+ (1,0) [5|7] "Not Used"  GWM
 SG_ DZMDrivRightHmiOp : 50|3@0+ (1,0) [5|7] "Not Used"  GWM
 SG_ MemRecallCancelMirror : 32|1@0+ (1,0) [0|1] ""  BCM_Gp,DSM,PDM
 SG_ MirrorFoldStatus : 53|3@0+ (1,0) [0|7] ""  GWM
 SG_ PCLMessageReq : 42|3@0+ (1,0) [0|7] ""  GWM
 SG_ SeatMem1ButtonStatD : 33|1@0+ (1,0) [0|1] ""  DSM
 SG_ SeatMem2ButtonStatD : 34|1@0+ (1,0) [0|1] ""  DSM
 SG_ SeatMem3ButtonStatD : 35|1@0+ (1,0) [0|1] ""  DSM
 SG_ SeatMemLEDStatD : 36|1@0+ (1,0) [0|1] ""  DSM
 SG_ SeatMemSetBtnStatD : 37|1@0+ (1,0) [0|1] ""  DSM

BO_ 242 DDM_SP_GW_1: 8 DDM
 SG_ DDHandleStatus : 5|3@0+ (1,0) [0|7] ""  GWM,RFA
 SG_ DDHandleStatus_UB : 63|1@0+ (1,0) [0|1] ""  GWM,RFA
 SG_ DDLockSwitchPress : 6|1@0+ (1,0) [0|1] ""  BCM_Gp,GWM
 SG_ DDLockSwitchPress_UB : 57|1@0+ (1,0) [0|1] ""  BCM_Gp,GWM
 SG_ DDUnLockSwitchPress : 7|1@0+ (1,0) [0|1] ""  BCM_Gp,GWM
 SG_ DDUnLockSwitchPress_UB : 58|1@0+ (1,0) [0|1] ""  BCM_Gp,GWM
 SG_ DipMirrorPosPassenger : 11|1@0+ (1,0) [0|1] ""  GWM,PDM
 SG_ DipMirrorPosPassenger_UB : 59|1@0+ (1,0) [0|1] ""  GWM,PDM
 SG_ DriverWindowPosition : 14|3@0+ (1,0) [6|7] "Undefined (Unused)"  BCM_Gp,FTCM,GWM,LPDM,RPDM
 SG_ DriverWindowPosition_UB : 60|1@0+ (1,0) [0|1] ""  BCM_Gp,FTCM,GWM,LPDM,RPDM
 SG_ PassMirrorCmd : 18|3@0+ (1,0) [0|7] ""  GWM,PDM
 SG_ PassMirrorCmd_UB : 61|1@0+ (1,0) [0|1] ""  GWM,PDM
 SG_ PassWindowCmd : 21|3@0+ (1,0) [5|7] "Undefined (Unused)"  GWM,PDM
 SG_ PassWindowCmd_UB : 56|1@0+ (1,0) [0|1] ""  GWM,PDM
 SG_ RearDriverWindowCmd : 2|3@0+ (1,0) [5|7] "Undefined (Unused)"  DRDM,GWM
 SG_ RearDriverWindowCmd_UB : 62|1@0+ (1,0) [0|1] ""  DRDM,GWM
 SG_ RearPassWindowCmd : 10|3@0+ (1,0) [5|7] "Undefined (Unused)"  GWM,PRDM
 SG_ RearPassWindowCmd_UB : 48|1@0+ (1,0) [0|1] ""  GWM,PRDM
 SG_ RearWindowDisableCmd : 15|1@0+ (1,0) [0|1] ""  BCM_Gp,DRDM,DSM,GWM,PDM,PRDM,PSM,RLSM,RRSM
 SG_ RearWindowDisableCmd_UB : 49|1@0+ (1,0) [0|1] ""  BCM_Gp,DRDM,DSM,GWM,PDM,PRDM,PSM,RLSM,RRSM

BO_ 1615 DevelopID_RGTM_Rx1_BOCAN: 8 GWM
 SG_ DevID_RGTM_Rx1 : 7|64@0+ (1,0) [0|1.84467440737096E+019] ""  RGTM

BO_ 1614 DevelopID_RGTM_Tx1_BOCAN: 8 RGTM
 SG_ DevID_RGTM_Tx1 : 7|64@0+ (1,0) [0|1.84467440737096E+019] ""  GWM

BO_ 1643 DevelopID_RGTMB_Rx1_BOCAN: 8 GWM
 SG_ DevID_RGTMB_Rx1 : 7|64@0+ (1,0) [0|1.84467440737096E+019] ""  RGTMB

BO_ 1642 DevelopID_RGTMB_Tx1_BOCAN: 8 RGTMB
 SG_ DevID_RGTMB_Tx1 : 7|64@0+ (1,0) [0|1.84467440737096E+019] ""  GWM

BO_ 476 DRDM_PR_1: 8 DRDM
 SG_ RockerSwitch1Req_a : 58|3@0+ (1,0) [5|7] "Not used"  PRDM
 SG_ RockerSwitch2Req_a : 61|3@0+ (1,0) [5|7] "Not used"  PRDM
 SG_ SunRoofFrBlindBtnReq_A : 48|1@0+ (1,0) [0|1] ""  BCM_Gp
 SG_ TaskLightRelaxBtnReq_A : 49|1@0+ (1,0) [0|1] ""  BCM_Gp
 SG_ TaskLightWorkBtnReq_A : 50|1@0+ (1,0) [0|1] ""  BCM_Gp

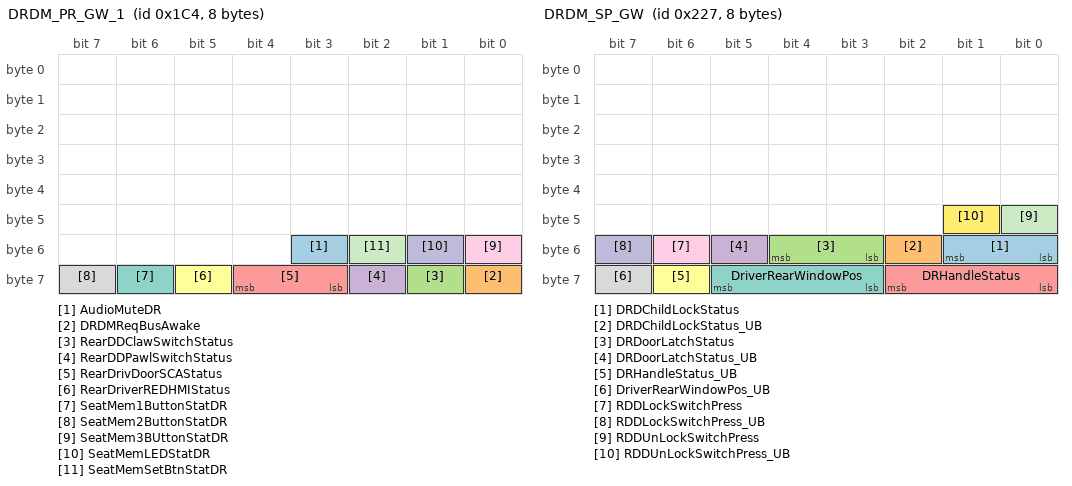
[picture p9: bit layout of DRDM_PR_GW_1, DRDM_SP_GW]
BO_ 452 DRDM_PR_GW_1: 8 DRDM
 SG_ AudioMuteDR : 51|1@0+ (1,0) [0|1] ""  GWM
 SG_ DRDMReqBusAwake : 56|1@0+ (1,0) [0|1] ""  GWM
 SG_ RearDDClawSwitchStatus : 57|1@0+ (1,0) [0|1] ""  PRDM
 SG_ RearDDPawlSwitchStatus : 58|1@0+ (1,0) [0|1] ""  PRDM
 SG_ RearDrivDoorSCAStatus : 60|2@0+ (1,0) [0|3] ""  PRDM
 SG_ RearDriverREDHMIStatus : 61|1@0+ (1,0) [0|1] ""  GWM
 SG_ SeatMem1ButtonStatDR : 62|1@0+ (1,0) [0|1] ""  DSM
 SG_ SeatMem2ButtonStatDR : 63|1@0+ (1,0) [0|1] ""  DSM
 SG_ SeatMem3BUttonStatDR : 48|1@0+ (1,0) [0|1] ""  DSM
 SG_ SeatMemLEDStatDR : 49|1@0+ (1,0) [0|1] ""  DSM
 SG_ SeatMemSetBtnStatDR : 50|1@0+ (1,0) [0|1] ""  DSM

BO_ 551 DRDM_SP_GW: 8 DRDM
 SG_ DRDChildLockStatus : 49|2@0+ (1,0) [0|3] ""  DDM,GWM
 SG_ DRDChildLockStatus_UB : 50|1@0+ (1,0) [0|1] ""  DDM,GWM
 SG_ DRDoorLatchStatus : 52|2@0+ (1,0) [0|3] "See Description"  BCM_Gp,GWM
 SG_ DRDoorLatchStatus_UB : 53|1@0+ (1,0) [0|1] ""  BCM_Gp,GWM
 SG_ DRHandleStatus : 58|3@0+ (1,0) [0|7] ""  GWM,RFA
 SG_ DRHandleStatus_UB : 62|1@0+ (1,0) [0|1] ""  GWM,RFA
 SG_ DriverRearWindowPos : 61|3@0+ (1,0) [6|7] "Undefined (Unused)"  BCM_Gp,FTCM,GWM
 SG_ DriverRearWindowPos_UB : 63|1@0+ (1,0) [0|1] ""  BCM_Gp,FTCM,GWM
 SG_ RDDLockSwitchPress : 54|1@0+ (1,0) [0|1] ""  BCM_Gp,GWM
 SG_ RDDLockSwitchPress_UB : 55|1@0+ (1,0) [0|1] ""  BCM_Gp,GWM
 SG_ RDDUnLockSwitchPress : 40|1@0+ (1,0) [0|1] ""  BCM_Gp,GWM
 SG_ RDDUnLockSwitchPress_UB : 41|1@0+ (1,0) [0|1] ""  BCM_Gp,GWM

BO_ 1291 DSM_NM50B: 8 DSM
 SG_ NMmessageDSM : 7|64@0+ (1,0) [0|1.84467440737096E+019] ""  Virtual_Node

BO_ 400 DSM_PR_1: 8 DSM
 SG_ DriverCancelSeat : 40|1@0+ (1,0) [0|1] ""  RLSM,RRSM
 SG_ DriverSeatMovementStat : 55|4@0+ (1,0) [5|14] "Reserved"  RLSM,RRSM
 SG_ DrvSeatOccupantStatus : 46|1@0+ (1,0) [0|1] ""  RLSM,RRSM
 SG_ FoldAllSeatsReqDSM : 41|1@0+ (1,0) [0|1] ""  PSM
 SG_ MemRecallCancelSeat : 42|1@0+ (1,0) [0|1] ""  BCM_Gp,DDM,PDM
 SG_ R2ISCM60SeatCancelDSM : 43|1@0+ (1,0) [0|1] ""  PSM
 SG_ R2ISCM60SeatInSP1DSM : 44|1@0+ (1,0) [0|1] ""  PSM
 SG_ R3RightSeatISCMCancDSM : 45|1@0+ (1,0) [0|1] ""  PSM
 SG_ R3RightSeatISCMReqDSM : 51|3@0+ (1,0) [0|7] ""  PSM
 SG_ RLSeatMsgAvailFrInt : 48|1@0+ (1,0) [0|1] ""  PSM
 SG_ RLSeatMsgModStatFrInt : 61|3@0+ (1,0) [5|7] "Unused"  PSM
 SG_ RLSeatMsgModStatInt : 58|3@0+ (1,0) [5|7] "Unused"  PSM
 SG_ RLSeatMsgStatFrInt : 62|1@0+ (1,0) [0|1] ""  PSM
 SG_ RockerSwitch1ReqDSM_a : 34|3@0+ (1,0) [5|7] "Not used"  PSM
 SG_ RockerSwitch1ReqDSM_b : 37|3@0+ (1,0) [5|7] "Not used"  PSM
 SG_ RockerSwitch2ReqDSM_a : 26|3@0+ (1,0) [5|7] "Not used"  PSM
 SG_ RockerSwitch2ReqDSM_b : 29|3@0+ (1,0) [5|7] "Not used"  PSM
 SG_ UnFoldAllSeatsReqDSM : 63|1@0+ (1,0) [0|1] ""  PSM

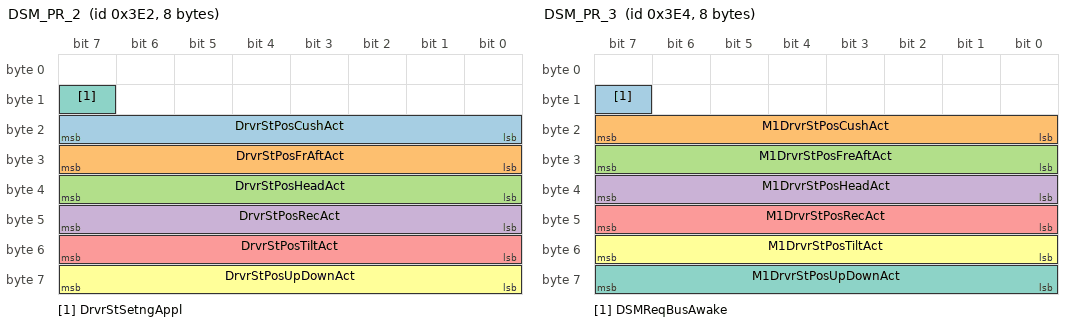
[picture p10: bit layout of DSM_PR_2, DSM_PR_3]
BO_ 994 DSM_PR_2: 8 DSM
 SG_ DrvrStPosCushAct : 23|8@0+ (0.5,0) [0|100] "%"  Virtual_Node
 SG_ DrvrStPosFrAftAct : 31|8@0+ (0.5,0) [0|100] "%"  Virtual_Node
 SG_ DrvrStPosHeadAct : 39|8@0+ (0.5,0) [0|100] "%"  Virtual_Node
 SG_ DrvrStPosRecAct : 47|8@0+ (0.5,0) [0|100] "%"  Virtual_Node
 SG_ DrvrStPosTiltAct : 55|8@0+ (0.5,0) [0|100] "%"  Virtual_Node
 SG_ DrvrStPosUpDownAct : 63|8@0+ (0.5,0) [0|100] "%"  Virtual_Node
 SG_ DrvrStSetngAppl : 15|1@0+ (1,0) [0|1] ""  Virtual_Node

BO_ 996 DSM_PR_3: 8 DSM
 SG_ DSMReqBusAwake : 15|1@0+ (1,0) [0|1] ""  GWM
 SG_ M1DrvrStPosCushAct : 23|8@0+ (0.5,0) [0|100] "%"  Virtual_Node
 SG_ M1DrvrStPosFreAftAct : 31|8@0+ (0.5,0) [0|100] "%"  Virtual_Node
 SG_ M1DrvrStPosHeadAct : 39|8@0+ (0.5,0) [0|100] "%"  Virtual_Node
 SG_ M1DrvrStPosRecAct : 47|8@0+ (0.5,0) [0|100] "%"  Virtual_Node
 SG_ M1DrvrStPosTiltAct : 55|8@0+ (0.5,0) [0|100] "%"  Virtual_Node
 SG_ M1DrvrStPosUpDownAct : 63|8@0+ (0.5,0) [0|100] "%"  Virtual_Node

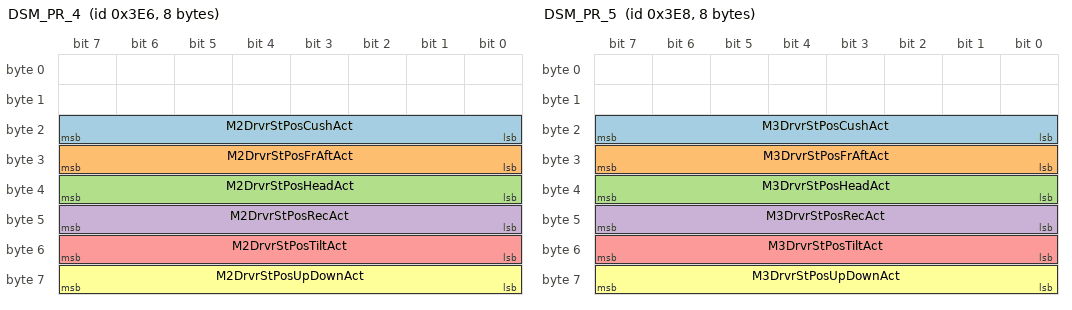
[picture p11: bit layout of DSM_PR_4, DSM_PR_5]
BO_ 998 DSM_PR_4: 8 DSM
 SG_ M2DrvrStPosCushAct : 23|8@0+ (0.5,0) [0|100] "%"  Virtual_Node
 SG_ M2DrvrStPosFrAftAct : 31|8@0+ (0.5,0) [0|100] "%"  Virtual_Node
 SG_ M2DrvrStPosHeadAct : 39|8@0+ (0.5,0) [0|100] "%"  Virtual_Node
 SG_ M2DrvrStPosRecAct : 47|8@0+ (0.5,0) [0|100] "%"  Virtual_Node
 SG_ M2DrvrStPosTiltAct : 55|8@0+ (0.5,0) [0|100] "%"  Virtual_Node
 SG_ M2DrvrStPosUpDownAct : 63|8@0+ (0.5,0) [0|100] "%"  Virtual_Node

BO_ 1000 DSM_PR_5: 8 DSM
 SG_ M3DrvrStPosCushAct : 23|8@0+ (0.5,0) [0|100] "%"  Virtual_Node
 SG_ M3DrvrStPosFrAftAct : 31|8@0+ (0.5,0) [0|100] "%"  Virtual_Node
 SG_ M3DrvrStPosHeadAct : 39|8@0+ (0.5,0) [0|100] "%"  Virtual_Node
 SG_ M3DrvrStPosRecAct : 47|8@0+ (0.5,0) [0|100] "%"  Virtual_Node
 SG_ M3DrvrStPosTiltAct : 55|8@0+ (0.5,0) [0|100] "%"  Virtual_Node
 SG_ M3DrvrStPosUpDownAct : 63|8@0+ (0.5,0) [0|100] "%"  Virtual_Node

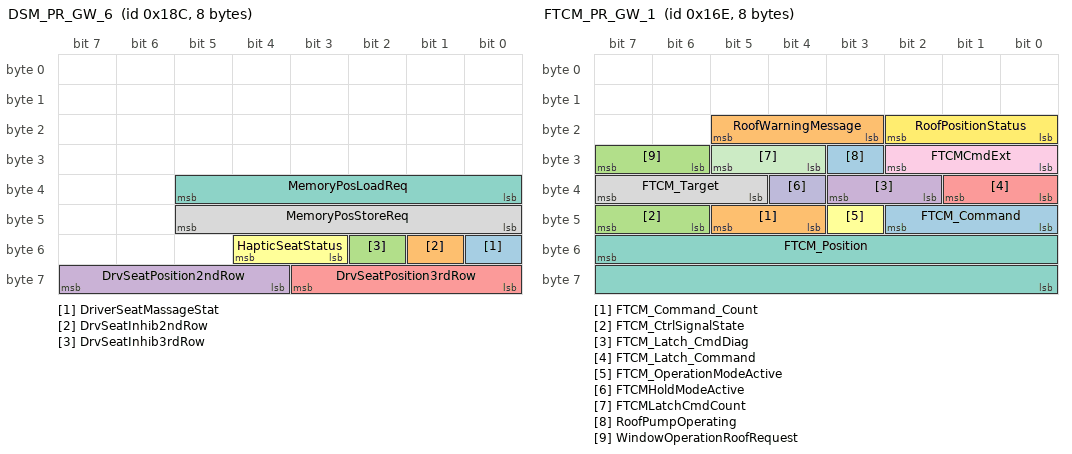
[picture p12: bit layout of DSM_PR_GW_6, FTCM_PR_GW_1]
BO_ 396 DSM_PR_GW_6: 8 DSM
 SG_ DriverSeatMassageStat : 48|1@0+ (1,0) [0|1] ""  GWM
 SG_ DrvSeatInhib2ndRow : 49|1@0+ (1,0) [0|1] ""  GWM
 SG_ DrvSeatInhib3rdRow : 50|1@0+ (1,0) [0|1] ""  GWM
 SG_ DrvSeatPosition2ndRow : 63|4@0+ (1,0) [5|15] "Reserved"  GWM
 SG_ DrvSeatPosition3rdRow : 59|4@0+ (1,0) [5|15] "Reserved"  GWM
 SG_ HapticSeatStatus : 52|2@0+ (1,0) [0|3] ""  GWM
 SG_ MemoryPosLoadReq : 37|6@0+ (1,0) [0|63] "See description"  BCM_Gp,DDM,GWM,PDM
 SG_ MemoryPosStoreReq : 45|6@0+ (1,0) [0|63] "See description for encoding"  BCM_Gp,DDM,GWM,PDM

BO_ 394 DSM_PR_GW_7: 8 DSM
 SG_ DriverSeatMovement : 57|1@0+ (1,0) [0|1] ""  GWM,RLSM,RRSM
 SG_ DriverSeatMsgAvail : 56|1@0+ (1,0) [0|1] ""  GWM
 SG_ DrvSeatMasgIntStat : 63|3@0+ (1,0) [0|7] ""  GWM
 SG_ DrvSeatMasgLocStat : 60|3@0+ (1,0) [0|7] ""  GWM
 SG_ DrvSeatMasgProgStat : 43|3@0+ (1,0) [0|7] ""  GWM
 SG_ DrvSeatMassageModeStat : 39|3@0+ (1,0) [0|7] ""  GWM
 SG_ DrvSeatMovement2ndRow : 36|2@0+ (1,0) [0|3] ""  GWM
 SG_ DrvSeatMovement3rdRow : 34|2@0+ (1,0) [0|3] ""  GWM
 SG_ DrvSeatMovmnt2ndRow : 27|4@0+ (1,0) [5|15] "Reserved"  GWM,PSM
 SG_ DrvSeatMovmnt3rdRow : 51|4@0+ (1,0) [5|15] "Reserved"  GWM,PSM
 SG_ EasyEntryEnDisStatRear : 45|2@0+ (1,0) [0|3] ""  GWM
 SG_ ISCMFrontSeatMovntStat : 40|1@0+ (1,0) [0|1] ""  GWM,PSM,RLSM,RRSM
 SG_ RDSeatMovement : 32|1@0+ (1,0) [0|1] ""  GWM
 SG_ Row1DriverMovementINH : 52|1@0+ (1,0) [0|1] ""  GWM
 SG_ Row2DriverMovementINH : 47|1@0+ (1,0) [0|1] ""  GWM
 SG_ Row3DriverMovementINH : 46|1@0+ (1,0) [0|1] ""  GWM
 SG_ SeatMoveSelectFrStat : 55|3@0+ (1,0) [0|7] ""  GWM

BO_ 1539 EOL_DCU_xRx1_BOCAN: 8 GWM
 SG_ EOL_DCU_Rx1 : 7|64@0+ (1,0) [0|1.84467440737096E+019] ""  DDM

BO_ 1541 EOL_DCU_xRx2_BOCAN: 8 GWM
 SG_ EOL_DCU_Rx2 : 7|64@0+ (1,0) [0|1.84467440737096E+019] ""  DDM

BO_ 1543 EOL_DCU_xRx3_BOCAN: 8 GWM
 SG_ EOL_DCU_Rx3 : 7|64@0+ (1,0) [0|1.84467440737096E+019] ""  PDM

BO_ 1545 EOL_DCU_xRx4_BOCAN: 8 GWM
 SG_ EOL_DCU_Rx4 : 7|64@0+ (1,0) [0|1.84467440737096E+019] ""  PDM

BO_ 1572 EOL_DCU_xRx5_BOCAN: 8 GWM
 SG_ EOL_DCU_Rx5 : 7|64@0+ (1,0) [0|1.84467440737096E+019] ""  DRDM

BO_ 1574 EOL_DCU_xRx6_BOCAN: 8 GWM
 SG_ EOL_DCU_Rx6 : 7|64@0+ (1,0) [0|1.84467440737096E+019] ""  DRDM

BO_ 1601 EOL_DCU_xRx7_BOCAN: 8 GWM
 SG_ EOL_DCU_Rx7 : 7|64@0+ (1,0) [0|1.84467440737096E+019] ""  PRDM

BO_ 1603 EOL_DCU_xRx8_BOCAN: 8 GWM
 SG_ EOL_DCU_Rx8 : 7|64@0+ (1,0) [0|1.84467440737096E+019] ""  PRDM

BO_ 1538 EOL_DCU_xTx1_BOCAN: 8 DDM
 SG_ EOL_DCU_Tx1 : 7|64@0+ (1,0) [0|1.84467440737096E+019] ""  GWM

BO_ 1540 EOL_DCU_xTx2_BOCAN: 8 DDM
 SG_ EOL_DCU_Tx2 : 7|64@0+ (1,0) [0|1.84467440737096E+019] ""  GWM

BO_ 1542 EOL_DCU_xTx3_BOCAN: 8 PDM
 SG_ EOL_DCU_Tx3 : 7|64@0+ (1,0) [0|1.84467440737096E+019] ""  GWM

BO_ 1544 EOL_DCU_xTx4_BOCAN: 8 PDM
 SG_ EOL_DCU_Tx4 : 7|64@0+ (1,0) [0|1.84467440737096E+019] ""  GWM

BO_ 1571 EOL_DCU_xTx5_BOCAN: 8 DRDM
 SG_ EOL_DCU_Tx5 : 7|64@0+ (1,0) [0|1.84467440737096E+019] ""  GWM

BO_ 1573 EOL_DCU_xTx6_BOCAN: 8 DRDM
 SG_ EOL_DCU_Tx6 : 7|64@0+ (1,0) [0|1.84467440737096E+019] ""  GWM

BO_ 1600 EOL_DCU_xTx7_BOCAN: 8 PRDM
 SG_ EOL_DCU_Tx7 : 7|64@0+ (1,0) [0|1.84467440737096E+019] ""  GWM

BO_ 1602 EOL_DCU_xTx8_BOCAN: 8 PRDM
 SG_ EOL_DCU_Tx8 : 7|64@0+ (1,0) [0|1.84467440737096E+019] ""  GWM

BO_ 128 ESCLDataControl_BO: 8 BCM_Gp
 SG_ ESCLDataControl : 7|64@0+ (1,0) [0|1.84467440737096E+019] ""  VIM

BO_ 130 ESCLDataTarget_BO: 8 VIM
 SG_ ESCLDataTargetV2 : 7|64@0+ (1,0) [0|1.84467440737096E+019] ""  BCM_Gp

BO_ 1360 FTCM_NM550BO: 8 FTCM
 SG_ NMmessageFTCM : 7|64@0+ (1,0) [0|1.84467440737096E+019] ""  Virtual_Node

BO_ 366 FTCM_PR_GW_1: 8 FTCM
 SG_ FTCM_Command : 42|3@0+ (1,0) [0|7] ""  FTCMB
 SG_ FTCM_Command_Count : 45|2@0+ (1,0) [0|3] "counter (inc counter- Trigger ac"  FTCMB
 SG_ FTCM_CtrlSignalState : 47|2@0+ (1,0) [0|3] ""  FTCMB
 SG_ FTCM_Latch_CmdDiag : 35|2@0+ (1,0) [0|3] ""  FTCMB
 SG_ FTCM_Latch_Command : 33|2@0+ (1,0) [0|3] ""  FTCMB
 SG_ FTCM_OperationModeActive : 43|1@0+ (1,0) [0|1] ""  FTCMB
 SG_ FTCM_Position : 55|16@0+ (1,0) [1|65535] "Actual Position of FTCM"  FTCMB
 SG_ FTCM_Target : 39|3@0+ (1,0) [0|7] ""  FTCMB
 SG_ FTCMCmdExt : 26|3@0+ (1,0) [0|7] ""  FTCMB
 SG_ FTCMHoldModeActive : 36|1@0+ (1,0) [0|1] ""  FTCMB
 SG_ FTCMLatchCmdCount : 29|2@0+ (1,0) [0|3] "counter (inc counter- Trigger ac"  FTCMB
 SG_ RoofPositionStatus : 18|3@0+ (1,0) [5|7] "Undefined (Unused)"  BCM_Gp,GWM
 SG_ RoofPumpOperating : 27|1@0+ (1,0) [0|1] ""  GWM
 SG_ RoofWarningMessage : 21|3@0+ (1,0) [0|7] ""  GWM
 SG_ WindowOperationRoofRequest : 31|2@0+ (1,0) [0|3] ""  BCM_Gp

BO_ 1363 FTCMB_NM553HS: 8 FTCMB
 SG_ NMmessageFTCMB : 7|64@0+ (1,0) [0|1.84467440737096E+019] ""  Virtual_Node

BO_ 367 FTCMB_PR_2: 8 FTCMB
 SG_ FTCMB_ClosedRange_Active : 39|1@0+ (1,0) [0|1] ""  FTCM
 SG_ FTCMB_CtrlSignal_State : 12|2@0+ (1,0) [0|3] ""  FTCM
 SG_ FTCMB_Error_Flags : 32|9@0+ (1,0) [0|511] ""  FTCM
 SG_ FTCMB_Finished : 10|3@0+ (1,0) [0|7] ""  FTCM
 SG_ FTCMB_Finished_Counter : 21|2@0+ (1,0) [0|3] "counter (inc counter- Trigger ac"  FTCM
 SG_ FTCMB_Latch_Error_Flags : 38|3@0+ (1,0) [0|7] ""  FTCM
 SG_ FTCMB_Latch_State : 35|3@0+ (1,0) [0|7] ""  FTCM
 SG_ FTCMB_Latch_State_Count : 14|2@0+ (1,0) [0|3] "counter (inc counter- Trigger ac"  FTCM
 SG_ FTCMB_OpenRange_Active : 15|1@0+ (1,0) [0|1] ""  FTCM
 SG_ FTCMB_Position : 55|16@0+ (1,0) [1|65535] "Actual Position of FTCM"  FTCM
 SG_ FTCMB_SD_DL_C_State : 31|2@0+ (1,0) [0|3] ""  FTCM
 SG_ FTCMB_SD_DL_O_State : 23|2@0+ (1,0) [0|3] ""  FTCM
 SG_ FTCMB_SL_DL_E_State : 3|2@0+ (1,0) [0|3] ""  FTCM
 SG_ FTCMB_SlaveState : 1|2@0+ (1,0) [0|3] ""  FTCM
 SG_ FTCMB_SP_FT_C_State : 5|2@0+ (1,0) [0|3] ""  FTCM
 SG_ FTCMB_State : 19|4@0+ (1,0) [0|15] ""  FTCM
 SG_ FTCMB_State_Flags : 29|6@0+ (1,0) [0|63] ""  FTCM

BO_ 583 FuelPumpEnableDataControl_BO: 8 GWM
 SG_ FuelPumpEnableDataControl : 7|64@0+ (1,0) [0|1.84467440737096E+019] ""  BCM_Gp

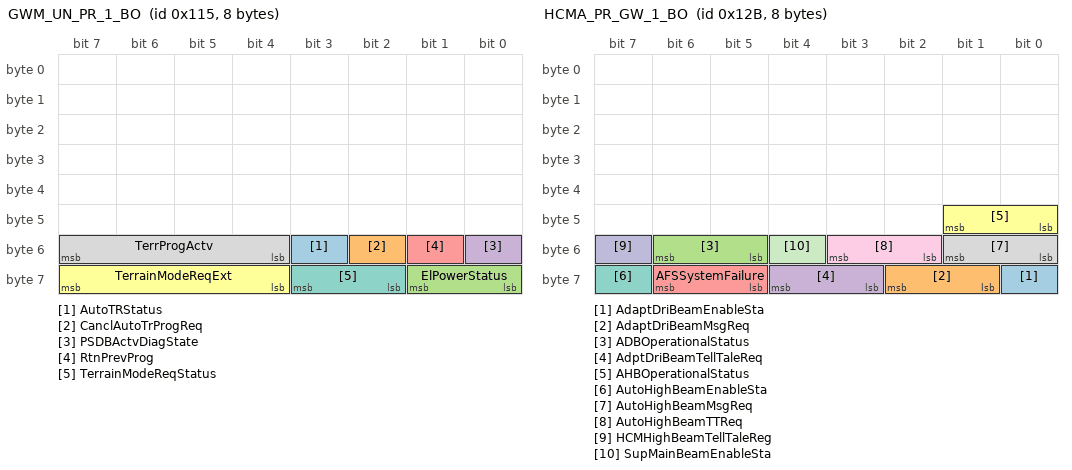
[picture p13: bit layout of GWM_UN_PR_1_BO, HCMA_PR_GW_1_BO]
BO_ 277 GWM_UN_PR_1_BO: 8 GWM
 SG_ AutoTRStatus : 51|1@0+ (1,0) [0|1] ""  TBM
 SG_ CanclAutoTrProgReq : 50|1@0+ (1,0) [0|1] ""  Vector_XXX
 SG_ ElPowerStatus : 57|2@0+ (1,0) [0|3] ""  BCM_Gp,DDM,DRDM,FTCM,FTCMB,LPDM,PDM,PRDM,RGTM,RGTMB,RPDM,TBM
 SG_ PSDBActvDiagState : 48|1@0+ (1,0) [0|1] ""  BCM_Gp
 SG_ RtnPrevProg : 49|1@0+ (1,0) [0|1] ""  Vector_XXX
 SG_ TerrainModeReqExt : 63|4@0+ (1,0) [0|15] ""  BCM_Gp,TBM,WDCM
 SG_ TerrainModeReqStatus : 59|2@0+ (1,0) [0|3] ""  BCM_Gp
 SG_ TerrProgActv : 55|4@0+ (1,0) [0|15] ""  Vector_XXX

BO_ 299 HCMA_PR_GW_1_BO: 8 GWM
 SG_ AdaptDriBeamEnableSta : 56|1@0+ (1,0) [0|1] ""  BCM_Gp
 SG_ AdaptDriBeamMsgReq : 58|2@0+ (1,0) [0|3] ""  Vector_XXX
 SG_ ADBOperationalStatus : 54|2@0+ (1,0) [0|3] ""  BCM_Gp
 SG_ AdptDriBeamTellTaleReq : 60|2@0+ (1,0) [0|3] ""  Vector_XXX
 SG_ AFSSystemFailure : 62|2@0+ (1,0) [0|3] ""  Vector_XXX
 SG_ AHBOperationalStatus : 41|2@0+ (1,0) [0|3] ""  BCM_Gp
 SG_ AutoHighBeamEnableSta : 63|1@0+ (1,0) [0|1] ""  BCM_Gp
 SG_ AutoHighBeamMsgReq : 49|2@0+ (1,0) [0|3] ""  Vector_XXX
 SG_ AutoHighBeamTTReq : 51|2@0+ (1,0) [0|3] ""  Vector_XXX
 SG_ HCMHighBeamTellTaleReg : 55|1@0+ (1,0) [0|1] ""  Vector_XXX
 SG_ SupMainBeamEnableSta : 52|1@0+ (1,0) [0|1] ""  Vector_XXX

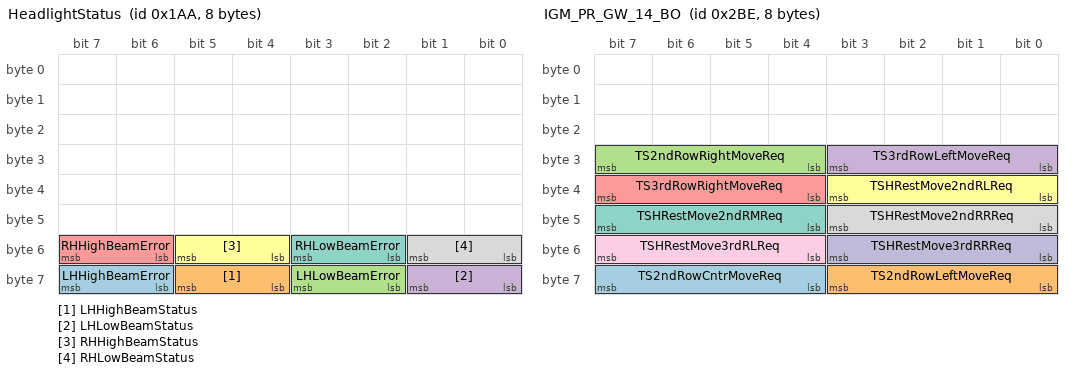
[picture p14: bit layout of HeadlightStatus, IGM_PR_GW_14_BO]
BO_ 426 HeadlightStatus: 8 BCM_Gp
 SG_ LHHighBeamError : 63|2@0+ (1,0) [0|3] ""  GWM
 SG_ LHHighBeamStatus : 61|2@0+ (1,0) [0|3] ""  GWM
 SG_ LHLowBeamError : 59|2@0+ (1,0) [0|3] ""  GWM
 SG_ LHLowBeamStatus : 57|2@0+ (1,0) [0|3] ""  GWM
 SG_ RHHighBeamError : 55|2@0+ (1,0) [0|3] ""  GWM
 SG_ RHHighBeamStatus : 53|2@0+ (1,0) [0|3] ""  GWM
 SG_ RHLowBeamError : 51|2@0+ (1,0) [0|3] ""  GWM
 SG_ RHLowBeamStatus : 49|2@0+ (1,0) [0|3] ""  GWM

BO_ 701 IGM_PR_GW_13_BO: 8 GWM
 SG_ AmbientLightValueHLDF : 31|8@0+ (1,0) [0|254] "Counts"  BCM_Gp
 SG_ DriveAwayLockingSw : 63|2@0+ (1,0) [0|3] ""  BCM_Gp
 SG_ EasyEntryEnDisReqRear : 34|2@0+ (1,0) [0|3] ""  DSM,PSM,RLSM,RRSM
 SG_ HeadlampExitDelayReq : 61|3@0+ (1,0) [5|7] "Reserved (Not Used)"  BCM_Gp
 SG_ ISCMFrontSeatMovement : 32|1@0+ (1,0) [0|1] ""  DSM,PSM,RLSM,RRSM
 SG_ LockChirpsReq : 45|1@0+ (1,0) [0|1] ""  BCM_Gp
 SG_ RainSenseReq : 46|1@0+ (1,0) [0|1] ""  BCM_Gp
 SG_ SeatMoveSelectFrReq : 44|3@0+ (1,0) [0|7] ""  DSM,PSM,RLSM,RRSM
 SG_ SensorOverrideSwitch : 35|1@0+ (1,0) [0|1] ""  BCM_Gp
 SG_ SkiHatchReq : 58|1@0+ (1,0) [0|1] ""  RRSM
 SG_ TSPassSeatMemLoadReq : 41|2@0+ (1,0) [0|3] ""  PSM
 SG_ TSPassSeatMemStorReq : 55|2@0+ (1,0) [0|3] ""  PSM
 SG_ TSPassSeatMoveReq : 39|4@0+ (1,0) [8|15] "Reserved"  PSM
 SG_ TSRLSeatMemLoadReq : 53|2@0+ (1,0) [0|3] ""  RLSM
 SG_ TSRLSeatMemStorReq : 51|2@0+ (1,0) [0|3] ""  RLSM
 SG_ TSRRSeatMemLoadReq : 49|2@0+ (1,0) [0|3] ""  RRSM
 SG_ TSRRSeatMemStorReq : 57|2@0+ (1,0) [0|3] ""  RRSM

BO_ 702 IGM_PR_GW_14_BO: 8 GWM
 SG_ TS2ndRowCntrMoveReq : 63|4@0+ (1,0) [7|15] "Reserved"  RLSM
 SG_ TS2ndRowLeftMoveReq : 59|4@0+ (1,0) [8|15] "Reserved"  DSM,PSM,RLSM
 SG_ TS2ndRowRightMoveReq : 31|4@0+ (1,0) [8|15] "Reserved"  DSM,PSM,RRSM
 SG_ TS3rdRowLeftMoveReq : 27|4@0+ (1,0) [4|15] "Reserved"  DSM,PSM
 SG_ TS3rdRowRightMoveReq : 39|4@0+ (1,0) [4|15] "Reserved"  DSM,PSM
 SG_ TSHRestMove2ndRLReq : 35|4@0+ (1,0) [4|15] "Reserved"  DSM,PSM,RLSM
 SG_ TSHRestMove2ndRMReq : 47|4@0+ (1,0) [4|15] "Reserved"  DSM,PSM,RLSM
 SG_ TSHRestMove2ndRRReq : 43|4@0+ (1,0) [4|15] "Reserved"  DSM,PSM,RRSM
 SG_ TSHRestMove3rdRLReq : 55|4@0+ (1,0) [4|15] "Reserved"  DSM,PSM
 SG_ TSHRestMove3rdRRReq : 51|4@0+ (1,0) [4|15] "Reserved"  DSM,PSM

BO_ 693 IGM_PR_Massage_BO: 8 GWM
 SG_ DriverSeatMassageReq : 55|1@0+ (1,0) [0|1] ""  Vector_XXX
 SG_ DrvSeatMasgIntReq : 58|3@0+ (1,0) [0|7] ""  DSM
 SG_ DrvSeatMasgLocReq : 61|3@0+ (1,0) [0|7] ""  DSM
 SG_ DrvSeatMasgProgReq : 50|3@0+ (1,0) [0|7] ""  DSM
 SG_ DrvSeatMassageModeReq : 53|3@0+ (1,0) [0|7] ""  DSM
 SG_ PassSeatMasgIntReq : 42|3@0+ (1,0) [0|7] ""  PSM
 SG_ PassSeatMasgLocReq : 45|3@0+ (1,0) [0|7] ""  PSM
 SG_ PassSeatMasgProgReq : 34|3@0+ (1,0) [0|7] ""  PSM
 SG_ PassSeatMassageModeReq : 37|3@0+ (1,0) [0|7] ""  PSM
 SG_ PassSeatMassageReq : 54|1@0+ (1,0) [0|1] ""  PSM
 SG_ RLSeatMasgIntReqFr : 26|3@0+ (1,0) [0|7] ""  RLSM
 SG_ RLSeatMasgLocReqFr : 29|3@0+ (1,0) [0|7] ""  RLSM
 SG_ RLSeatMasgModeReqFr : 18|3@0+ (1,0) [5|7] "Unused"  RLSM
 SG_ RLSeatMasgProgReqFr : 21|3@0+ (1,0) [0|7] ""  RLSM
 SG_ RLSeatMasgReqFr : 63|1@0+ (1,0) [0|1] ""  PSM,RLSM
 SG_ RRSeatMasgIntReqFr : 10|3@0+ (1,0) [0|7] ""  RRSM
 SG_ RRSeatMasgLocReqFr : 13|3@0+ (1,0) [0|7] ""  RRSM
 SG_ RRSeatMasgModeReqFr : 2|3@0+ (1,0) [5|7] "Unused"  RRSM
 SG_ RRSeatMasgProgReqFr : 5|3@0+ (1,0) [0|7] ""  RRSM
 SG_ RRSeatMasgReqFr : 62|1@0+ (1,0) [0|1] ""  DSM,RRSM

CM_ BU_ BCM_Gp "Body Control Module, Lear BCM Without TPMS and with HCM, Atlas 3R2

Node type - Type 3, OSEK, Local / Network wake-up 

This variant has 12 LIN bues";
CM_ BU_ DDM "Driver Door Zone Module Gen 2 - DDM_DZM2
";
CM_ BU_ DRDM "Driver Rear Door Zone Module Gen 2, DRDM_DZM2";
CM_ BU_ DSM "Generation 2 Driver Seat Module - DSM_Gen2 World Class Interior
";
CM_ BU_ FTCM "Folding Top Control Module    (FTCM)";
CM_ BU_ FTCMB "Folding Top Control Module B    (FTCMB)";
CM_ BU_ GWM "XCL Gateway Module for EVA2, NCR17Q4 / Feature Bundle 3 onwards
";
CM_ BU_ LPDM "Left Power Door Module.

Only on SVO programmes.";
CM_ BU_ PDM "Passenger Door Zone Module Gen 2- PDM_DZM2
";
CM_ BU_ PRDM "Passenger Rear Door Zone Module Gen 2 - PRDM_DZM2";
CM_ BU_ PSM "Generation 2 Passenger Seat Module - PSM_Gen2 World Class Interior
";
CM_ BU_ RFA "Remote Function Actuator";
CM_ BU_ RGTM "Rear Gate/Trunk Module";
CM_ BU_ RGTMB "Rear Gate/Trunk Module B";
CM_ BU_ RLSM "Generation 2 Rear Left Seat Module - RLSM_Gen2";
CM_ BU_ RPDM "Right Power Door Module.

Only on SVO programmes.";
CM_ BU_ RRSM "Generation 2 Rear Right Seat Module - RRSM_Gen2 World Class Interior

";
CM_ BU_ TBM "Tow Bar Module";
CM_ BU_ TSTR "Offboard Tester with High Speed Comfort CAN Interface - TSTR_HS";
CM_ BU_ VIM "Vehicle Immobilizer Control Module";
CM_ BU_ WDCM "Wireless Device Charger Module";
CM_ SG_ 66 ABSBrakeLightRequest "To request brake light activation for automatic braking functions in the ABS e.g. HDC, ACC, QA, IEB, AEBA, HDA etc.";
CM_ SG_ 66 ABSMILRequest "This signal is part of the OBDII functions. The ABS requests MIL functionality via the EMS. The EMS has the authority to over-ride ABS MIL requests.";
CM_ SG_ 66 EPBLongitudinalAcc "This is the measured Longitudinal Acceleration from the EPB.  When the vehicle is parked up-hill (noseup), the reading would be positive, when parked downhill (nosedown) then reading would be negative. On flat surface the reading would be '0' (zero).

Will permanently be set to 255? on Jaguar Dura PBM.";
CM_ SG_ 66 EPBMode "Current state of Electric Park Brake (EPB). State encoded.
All states are used by the Jaguar system.
States 0, 1, 3 shall be used by the Land Rover system.";
CM_ SG_ 66 EPBStatus "Summary of the mode that the Electric Park Brake is in.


";
CM_ SG_ 66 HillDescentMode "To inform ECM; TCM about actual HDC function status.";
CM_ SG_ 66 KeepNetInAfterRunABS "CAN signal stating if the network is required for After-Run.

Description of bit field detailing each application function to be stored in the DID (After-Run Function 1- 16):
b0: Vehicle Speed
b1: HEV Braking Function (Hybrid only)
b2 - b15: not used
";
CM_ SG_ 66 KeepNetInPreRunABS "CAN signal stating if the network is required for Pre-Run.

Description of bit field detailing each application function to be stored in the DID (After-Run Function 1- 16):
b0: HEV braking function
b1 - b15: not used
";
CM_ SG_ 66 ODORawCount "The true scaling factor of this signal is hardware dependant based on the rolling circumference (assumed and actual) and the number of teeth on the wheel speed sensor tooth ring.
ODORawCount does not indicate a default condition in the CAN signal. This may be determined from other signals e.g. WheelSpeedFrRQF and WheelSpeedFrLQF.

Rear Wheel Drive and AWD Vehicles (Jaguar X150/X250/X351/X152):
---------------------------------------------------------------------------------------
Raw Rolling Count (counts through zero) of two front wheel speed signals. Measures distance travelled based on a reference circumference of 2.101m and a tooth ring of 46 teeth (AWD vehicles 48 teeth). Calculated by counting both the rising and falling edges of the raw sensor signals from the two front wheel speed signals. Signal increments on average in steps of 11.42mm (AWD vehicles 10.94mm).

Rear Wheel Drive and AWD Vehicles (Jaguar X760/X260/X761):
-------------------------------------------------------------------------";
CM_ SG_ 66 YawRate "This signal represents the yaw rate of the vehicle. The value of yaw rate is positive in a right (clockwise) turn.";
CM_ SG_ 17 ABSAliveCounter "This counter forms part of a safety-related signal group.
It is incremented by the task which generates the data set used in the CRC calculation, and may be used to determine the health of the data generation task.
Refer to STJLR 18.036 for more detail.";
CM_ SG_ 17 ABSChecksum "This CRC shall be calculated in compliance with STJLR 18.036 Version 5.
The Data Segment Polynomial shall be constructed from the details
in the network configuration file.";
CM_ SG_ 17 ABSEngVacReq "1 bit signal used to indicate that ABS is unable to generate any/ sufficient brake vacuum using the electric vacuum pump, and that the engine will need to generate brake vacuum itself.";
CM_ SG_ 17 ABSPwrTrnTorqReq "This is a renaming action for ABSReqEngRunning to give clarity of the intent of this signal.
It does not mean that the internal combustion engine must be running, rather it means that the powertrain torque must be available to the driver. This may be achieved by the internal combustion engine, or an e-machine, and the transmission";
CM_ SG_ 17 BrakePressure "Non Hybrid: The signal informs about the pressure in the master cylinder.
Hybrid: Indicates the pressure that would be present at the master cylinder for the same total
brake torque delivered by the HEV braking system compared to a conventional braking system.

Note: The signal saturates at 204.6 bar. The actual brake pressure can exceed 204.6 bar.";
CM_ SG_ 17 BrakePressureQF "Quality factor for the signal BrakePressure.
";
CM_ SG_ 17 VehicleSpeed "Use in conjunction with VehicleSpeedQF. A value of 65535d may also be set under error conditions.

Rear Wheel Drive and AWD Vehicles (Jaguar X150/X250/X351/X152/X760/X260/X761):
---------------------------------------------------------------------------------------
VehicleSpeed is calculated as the average speed of the two driven rear wheels. If one wheel speed sensor fails, VehicleSpeed will use the speed information from the other sensor. Based on a rolling circumference of 2.101m on X150/X250/X351/X152. Based on a rolling circumference of 2.050m on X760. Based on a rolling circumference of 2.000m on X260. Based on a rolling circumference of 2.300m on X761.

Four Wheel Drive Vehicles (LandRover L319/L320/L322/L405/L494/L462):
--------------------------------------------------------------------------------------------
VehicleSpeed is calculated as the average speed of all four wheels. In the case of wheel speed sensor failures, VehicleSpeed will use the speed information from the remaining sensors. ";
CM_ SG_ 17 VehicleSpeedQF "Quality factor for the signal VehicleSpeed. EuCD compliant signal.";
CM_ SG_ 1281 NMmessageBCMLS "This is the Network Management Protocol Data Unit (NMPDU) for the BCM on LS_CAN.

Description of station manager bit field detailing each application function (station manager function 1-16)
Bit 0 - Power Mode Management
Bit 1 - Start Warnings
Bit 2 - Courtesy Lights
Bit 3 - Alarm and Security
Bit 4 - Passive key scan requests
Bit 5 - Personalisation
Bit 6 - Doors and Windows
Bit 7 - Start Authorisation and ESCL
Bit 8 - Lighting
Bit 9 - Electric Park Brake
Bit 10 - Steering Column Control
Bit 11 - HeVAC
Bit 12 - Trip Computer Button
Bit 13 - Not Used
Bit 14 - Diagnostics
Bit 15 - Not Used

The MSB of the signal must be written to the COM layer first (with an offset of zero in wr_bytes() ) and therefore transmitted on the bus first.
Similarly, subscribing modules will receive the MSB of the signal when they call rd_bytes(0).

E.g. wr_bytes(0) = published_signal_MSB;

Subscribed_Signal_MSB = rd_bytes(0);

";
CM_ SG_ 418 DDShortDrop "Drivers Door Glass Drop Request";
CM_ SG_ 418 GlobalRealTimeRaw "The raw Global Real Time value calculated in the BCM. 
This value is used by the Vehicle Information Parameters master to populate the Global Real Time value in the  Vehicle Information Parameters signal.
All nodes except the Vehicle Information Parameters master should use the Global Real Time from the Vehicle Information Parameters signal, they must NOT subscribe to this signal.
If there is no value available on Global real time, the value shall be 0xFFFFFFFF.";
CM_ SG_ 418 ImmoPStartApproved "Passive Start Approved Status";
CM_ SG_ 418 OMAStartMode "OMAStartMode";
CM_ SG_ 418 PDShortDrop "Passenger Door Glass Drop Request.";
CM_ SG_ 418 TREcoButtonBCM "Terrain Response ECO Mode Button";
CM_ SG_ 763 CascadeIllumIntensity "BacklightIntensityLevel which the cascade illumination is aiming for";
CM_ SG_ 763 CascadeIllumRampTime "Ramp time for individual backlight illumination zones to ramp from current intensity value to the required value.";
CM_ SG_ 763 CascadeIllumZone1 "There are 4 individual 1 bit signals, 1 signal for the control of each particular zone:
CascadeIllumZone1 - controls the illumination cascade for zone 1
CascadeIllumZone2 - controls the illumination cascade for zone 2
CascadeIllumZone3 - controls the illumination cascade for zone 3
CascadeIllumZone4 - controls the illumination cascade for zone 4
";
CM_ SG_ 763 CascadeIllumZone2 "There are 4 individual 1 bit signals, 1 signal for the control of each particular zone:
CascadeIllumZone1 - controls the illumination cascade for zone 1
CascadeIllumZone2 - controls the illumination cascade for zone 2
CascadeIllumZone3 - controls the illumination cascade for zone 3
CascadeIllumZone4 - controls the illumination cascade for zone 4
";
CM_ SG_ 763 CascadeIllumZone3 "There are 4 individual 1 bit signals, 1 signal for the control of each particular zone:
CascadeIllumZone1 - controls the illumination cascade for zone 1
CascadeIllumZone2 - controls the illumination cascade for zone 2
CascadeIllumZone3 - controls the illumination cascade for zone 3
CascadeIllumZone4 - controls the illumination cascade for zone 4
";
CM_ SG_ 763 CascadeIllumZone4 "There are 4 individual 1 bit signals, 1 signal for the control of each particular zone:
CascadeIllumZone1 - controls the illumination cascade for zone 1
CascadeIllumZone2 - controls the illumination cascade for zone 2
CascadeIllumZone3 - controls the illumination cascade for zone 3
CascadeIllumZone4 - controls the illumination cascade for zone 4
";
CM_ SG_ 255 CarMode "Information about which Carmode the vehicle is in i.e. Normal, factory etc.
";
CM_ SG_ 255 CentralLockLastCmdOrig "Location responsible for the last central lock command";
CM_ SG_ 255 DIFunctionStatus "Signal specifies the scenario causing the DI Function to be enabled 
";
CM_ SG_ 255 DirectionIndicationSwitch "Status of the Direction Indication Switch.";
CM_ SG_ 255 ExtLgtAutoTellTaleRq "Cluster tell tale to indicate when exterior lighting system is in Auto. ";
CM_ SG_ 255 HeadlampSequenceReq "Signal to headlamp control module to perform wake up and shutdown  lighting sequence";
CM_ SG_ 255 MainBeamIndication "This signal identifies the status of the main  beam lamps.";
CM_ SG_ 255 MHSwitchStatusBCM "Driver Button status used to manually disable the Micro Hybrid Stop/Start system.

Signal is published by BCM ";
CM_ SG_ 255 PowerMode "Information of current PowerMode, reflects the current  state of the Power Mode Superviser

For L538:
The signals PowerModeHS, PowerModeHSQF & PowerModeComp are all with the group PowerModeGrpHS. This grouping is to ensure that the signals are packed within the same frame, they are not treated as a group within the BCM. ";
CM_ SG_ 255 PowerModeAliveCounter "This counter forms part of a safety-related signal group.
It is incremented by the task which generates the data set used in the CRC calculation, and may be used to determine the health of the data generation task.
Refer to STJLR 18.036 for more detail.";
CM_ SG_ 255 PowerModeChecksum "This CRC shall be calculated in compliance with STJLR 18.036 Version 5.
The Data Segment Polynomial shall be constructed from the details in the network configuration file";
CM_ SG_ 255 PowerModeQF "Quality Factor of current PowerMode, reflects the quality of the PowerMode signal


For L538:
The signals PowerModeHS, PowerModeHSQF & PowerModeComp are all with the group PowerModeGrpHS. This grouping is to ensure that the signals are packed within the same frame, they are not treated as a group within the BCM. 
";
CM_ SG_ 255 RemoteFunctionStatus "CAN Message required to provide feedback to the TCU. Signal contains engine start Allowed/Blocked status.";
CM_ SG_ 255 RemoteStartStatusMS "Indicates whether Remote Engine starting is currently requested or Not.";
CM_ SG_ 255 ReversedGear "To detect if reversing gear is in use or not for manual cars.

Additon for L538

'The group ReverseGearGrp is required to keep ReversedGear and ReversedgearQF in the same CAN frame for L538.  It is not a requirement for the data to be calculated and written at the same time in the application software.'";
CM_ SG_ 255 RunningStandby "Signal indicates whether the engine is in Eco Stop or not";
CM_ SG_ 255 StartModeReq "StartModeReq is required to offer a handshake between the FSJB and the EMS (D-ECM/P-ECM) wrt Engine starting. This is to overcome several issues regarding the current strategy, continuous improvement.";
CM_ SG_ 255 TransitState "BCM permanently inhibits certain functions/features while in Transport Mode even when engine is running, according to the OMM Standard STJLR.00.5083 'Energy Management Standard'.";
CM_ SG_ 673 FrontFoglightSwitchPos "This signal FrontFogLightSwitch is sent to ExtriorLightControl object when the Driver/User has pushed the FrontFogLightSwitch button  in position On and Off. The FrontFogLightSwitch controls the fog lamps mounted on the front of the car. On the right side and one on the left side.
Prerequisite the FrontFog lamps are automatically in off position when the PowerModes is turned from Ignition(2) to KeyOut(-1) and then to position Ignition(2) again.";
CM_ SG_ 673 TransitSwitchActive "Indicates if the Transit Relay is fitted.";
CM_ SG_ 673 WasherRearCmd "Controls washing of the rear window.
Wiper stalk command for: rear screen washing.
";
CM_ SG_ 673 WiperFrontCmd_EuCD "Controls front wiper.";
CM_ SG_ 673 WiperRearCmd "Wiper stalk command for: rear wiper.
";
CM_ SG_ 675 AFSWarningLamp "Outputs a signal when the AFS ECU is defect and requires a warning lamp in the cluster to be lit.";
CM_ SG_ 675 EngineStartSeqMsgReq "Used to instruct the Instrument Cluster to display various warnings with respect to engine starting sequence.";
CM_ SG_ 675 EngineStartWarningReq "Following 4 repeated start attempts, this warning will alert the user to contact dealer. 

0 = Warning Off
1 = Warning On";
CM_ SG_ 675 EngineStopWarningMsg "Used to alert the user that the Start Stop button has been pressed whilst the vehicle is in motion. Additionally, to inform how to restart the engine whilst vehicle in motion.";
CM_ SG_ 675 GestureBlindStatus "Confirmation from the BCM on whether the Gesture Blind feature is enabled or disabled";
CM_ SG_ 675 HeadLampStatus "Provides an O/P to indicate headlamp status to the AFS model, and takes into account DRL and Exit Delay Headlamps.";
CM_ SG_ 675 PKeyDockedWarning "Signal part of a group - used to display appropriate warning message / graphic when the key is docked - data consists of key identifier, battery status and flag to set warning.
PKDockedWarning = True (1) / False (0)
Default = 0";
CM_ SG_ 675 RearFoglightIndication "Indicates the status of the rear foglight";
CM_ SG_ 675 RheostatPositionCmd "Gives the subscribers information for setting different levels of symbol, comfort and display illumination.";
CM_ SG_ 675 SelectParkWarning "Select Park Warning.";
CM_ SG_ 675 SensorOverrideStatus "Status of the intrusion sensors and tilt sensor.";
CM_ SG_ 675 SmartKeyDeactivatedReq "SmartKeyDeactivatedWarning:
Alerts the user that the Smart Key being used has been deactivated, in lieu of Smart Key Not Found etc. ";
CM_ SG_ 675 StartAndBrakeWarning "Start and Brake Warning.";
CM_ SG_ 675 StartAndClutchWarning "Warning used to advise the customer to depress the clutch when attempting to start a manual transmission vehicle.";
CM_ SG_ 675 StartStop1Warning "Start Stop Switch 1 Warning.";
CM_ SG_ 675 StartStop2Warning "Start Stop Switch 2 Warning.";
CM_ SG_ 675 TgateOrGlassStatus "Declares whether tailgate or glass will be opened when the remote open button is pressed.";
CM_ SG_ 675 TripButtonStatus "Status of trip button (press or not pressed) on left hand column stalk.";
CM_ SG_ 675 ValetModeChimeAndMsgReq "Signal requests valet mode chime from INST and INST to display a message on the INST message display.
 - the chime and message should be triggered only by the new CAN signal - 'ValetModeChimeAndMsgReq' (triggered each time the LS-CAN input signal 'ValetModeChimeAndMsgReq' changes from 0 to 1)";
CM_ SG_ 675 WasherFluidLevelWarning "Request for washer fluid level warning to be displayed.";
CM_ SG_ 676 CurrAutoFoldSett "Autofold Status.

THIS SIGNAL WAS PREVIOUSLY AutofoldStatus. Changed to align with EuCD.";
CM_ SG_ 676 DoorLatchStatus "Door latch status.";
CM_ SG_ 676 IndicationIllumCmd "Indicates the back-light status of the cluster, used for Illumination Control.
";
CM_ SG_ 676 MemoryRecallCancelCol "MemoryRecallCancelCol.

";
CM_ SG_ 677 AmbLightColourBlue "Requested ambient lighting blue intensity";
CM_ SG_ 677 AmbLightColourGreen "Requested ambient lighting green intensity";
CM_ SG_ 677 AmbLightColourRed "Requested ambient lighting red intensity";
CM_ SG_ 677 AmbLightColourZoneReq "Zone identifier for interior ambient lighting colour. Allows smart LED modules to respond to messages addressed to their 'zone' when the colour values are sent.


Bitmapped (1 bit for each zone)
Bit 0 - zone 1
Bit 1 - zone 2
Bit 2 - zone 3
Bit 3 - zone 4

1 = zone addressed
0 = zone NOT addressed
";
CM_ SG_ 677 AmbLightDynModeStatus "BCM to FCDIM signal containing TerrainModeReq (Dynamic) status for the interior ambient lighting";
CM_ SG_ 677 AmbLightIntensityReqMS "Intensity ('brightness') of interior ambient lighting

";
CM_ SG_ 677 AmbLightIntZoneReqMS "Zone identifier for interior ambient lighting intensity. Allows smart LED modules to respond to messages addressed to their 'zone' when the intensity and ramp values are sent.


Bitmapped (1 bit for each zone)
Bit 0 - zone 1
Bit 1 - zone 2
Bit 2 - zone 3
Bit 3 - zone 4

1 = zone addressed
0 = zone NOT addressed
";
CM_ SG_ 677 AmbLightProfileStat "Status signal to IMC to indicate current active profile";
CM_ SG_ 677 AmbLightRampRateReqMS "Rate at which the interior ambient lighting shall fade to the demanded intensity.

";
CM_ SG_ 677 AmbLightUIColourStat "Signal containing colour acknowledgement for the interior ambient lighting

No encoding, just a list of numbered colour schemes.";
CM_ SG_ 677 AmbLightUIDynAutoStat "signal containing auto-dynamic acknowledgement for the interior ambient lighting

";
CM_ SG_ 677 AmbLightUIIntenstyStat "Signal containing intensity acknowledgement for the interior ambient lighting

";
CM_ SG_ 677 AmbLightUIZoneStat "signal containing zone acknowledgement for the interior ambient lighting

Bitmapped (1 bit for each zone)
Bit 0 - zone 1
Bit 1 - zone 2
Bit 2 - zone 3
Bit 3 - zone 4
Bit 4 - zone 5

1 = zone addressed
0 = zone NOT addressed";
CM_ SG_ 678 ComfortRlyOffImminent "Signal from BCM to inform of imminent de-energisation of Comfort relay. This is primarily required for seat modules powered by Comfort relay to disable seat movement just prior to losing logic feed to prevent loss of seat calibration.

Logical Value 0 - Comfort Relay ON
Logical Value 1 - Comfort Relay OFF or about to be turned OFF";
CM_ SG_ 678 DipBeamStatus "Status of dipped headlamp beam.";
CM_ SG_ 678 DipMirrSetngApp "Reverse Dip Mirror settings will successfully be applied";
CM_ SG_ 678 ExtLightSetngAppl "Exterior light settings will successfully be applied";
CM_ SG_ 678 GotoEntryExitPos "Easy Entry Exit Command Status";
CM_ SG_ 678 HFSStatus "Heated Front Screen Status";
CM_ SG_ 678 HRWStatus "Heated Rear Window Status";
CM_ SG_ 678 IgnoreLatchOnUnlock "Enables/disables PE scan on door handle pull when unlocked.

Encoding added to description as field insufficient for full encoding description.

1 = Always scan for keys on a door handle pull and send unlock request over CAN
0 = Do not scan for keys if door reporting unlocked";
CM_ SG_ 678 IntLightSetngAppl "Interior light settings successfully be applied";
CM_ SG_ 678 POTailgateLatchStatus "Message from BCM telling RGTM the (Raw) Tailgate Latch Status";
CM_ SG_ 678 POTLatchStatLwrLHS "Signal reporting the (RAW) Lower LHS Tailgate Latch Status(Primary)";
CM_ SG_ 678 POTLatchStatLwrRHS "Signal reporting the (RAW) Lower RHS Tailgate Latch Status(primary)";
CM_ SG_ 678 PrivateLockStatus "Status signal confirming vehicle locking from the cabin.

";
CM_ SG_ 678 PwrTGOpenCloseReq "Request to RGTM from BCM to Power Open/Close from a specific source";
CM_ SG_ 678 PwrTGUpperAndLwrReq "Signal from BCM to RGTM and RGTMB to power open/close both Upper and Lower tailgates from a specific source.";
CM_ SG_ 678 TrailerFogLights "Trailer Fog light Request ";
CM_ SG_ 678 TrailerReverseLights "Trailer Reverse light Request";
CM_ SG_ 678 TrailerTailLightsL "Trailer Left tail light Request";
CM_ SG_ 678 TrailerTailLightsR "Trailer Right tail light Request";
CM_ SG_ 678 UserStartReq "New signal to inform the GWM of intended start, to allow enough time to switch contactors (dual battery). ";
CM_ SG_ 679 MinuteCounter "This is a counter of time elapsed from the time that permanent battery power was applied to the instrument pack. 
This signal is incremented every 100 ms, and has a scaling of 100 ms per bit with zero offset. 
If power is removed, the previously-stored value will be retained. 
At maximum value (FFFFFFFE), the counter will roll over to zero. FFFFFFFF is defined as 'Correct value not available' by the Generic Global Diagnostic Specification. 
(This signal has to be read/written as bytes, because Volcano 5 does not support 32-bit unsigned values.) 
Note, no encoding information is permitted for this signal because it is a 'bytes' type signal and cannot be directly interpreted as an integer.

This signal shall be set as a Constant = 0xFFFFFFFF, whenever MinuteCounter is not available as a Network Signal.

The MSB of the signal must be written to the COM layer first (with an offset of zero in wr_bytes() ) and therefore transmitted on the bus first.
Similarly, subscribing modules will receive the MSB of ";
CM_ SG_ 681 UserSetTimeDate "Part:  No of bits     LSB      MSB             Value range        Scaling     Offset
                             offset    offset             Min     ->	Max

Year        8               40         47             2000         2254          1          2000
Month      8              32         39                0              12            1             0
Day         8              24          31                0              31            1             0
Hour        8              16          23                0              23            1             0	
Minute     8               8           15                0              59            1             0	
Second   8               0             7                0              59            1             0	

LSB/MSB offsets are in Motorola Backwards format, and are offsets within the signal. 
Offsets within the frame may be different.
 
Year shall be treated as the most significant byte of the string, and read/written first in rd/wr_bytes().
";
CM_ SG_ 938 RESAlarmStatus "Indicates whether the remote start precondition of alarm not active was met. The value must not be relied upon outside the context of a remote engine start operation.";
CM_ SG_ 938 RESBrakePedalStatus "Indicates whether the remote start precondition of brake pedal not pressed was met. The value must not be relied upon outside the context of a remote engine start operation.";
CM_ SG_ 938 RESEngineRunningStatus "Indicates whether the remote start precondition of engine not running was met. The value must not be relied upon outside the context of a remote engine start operation.";
CM_ SG_ 938 RESHazardSwitchStatus "Indicates whether the remote start precondition of hazard switch not pressed was met. The value must not be relied upon outside the context of a remote engine start operation.";
CM_ SG_ 938 RESSequenceStatus "Indicates whether the remote start operation completed successfully. The value must not be relied upon outside the context of a remote engine start operation.";
CM_ SG_ 938 RESTransmissionStatus "Indicates whether the remote start precondition of transmission in Park was met. The value must not be relied upon outside the context of a remote engine start operation.";
CM_ SG_ 938 RESVehicleLockStatus "Indicates whether the remote start precondition of vehicle locked was met. The value must not be relied upon outside the context of a remote engine start operation.";
CM_ SG_ 938 RESVehStationaryStatus "Indicates whether the remote start precondition of vehicle stationary was met. The value must not be relied upon outside the context of a remote engine start operation.";
CM_ SG_ 938 RESWindowStatus "0 = at least one open or unknown
1 = all closed";
CM_ SG_ 423 ExteriorLightFunctionStatus "New Exterior Lighting LIN signal required from BCM to HCMA/B.
The existing signal ExteriorLightSwitchPos2 is publishing the value into the BCM Model but does not represent the truth status of the Exterior lights. 
The new signal is requested in order to publish the current status of the lights, from the BCM Model to the HCMA and HCMB.
ExteriorLightSwitchPos2Status - new signal is required for L560 18MY";
CM_ SG_ 423 ExteriorLightSwitchPos2 "New exterior light switch position LIN signal required from SWM to BCM LIN_1

Additional value required for new 5 position switch (current switch has 4 positions and uses a 2 bit signal)";
CM_ SG_ 423 MainBeamSwitch "This signal MainBeamSwitch is sending to ExtriorLightControl object when the Driver/User have manoeuvred the MainBeamSwitch control in position Neutral, Flash and Toggle.";
CM_ SG_ 420 DiagHeadLightFault "Headlight Switch Fault";
CM_ SG_ 420 DirectionIndSwitchPos "This signal DirectionIndcationSwitch is sending to ExtriorLightControl object when the Driver/User have manoevred the DirectionIndicationSwitch control  in position Neutral, Left and Right position";
CM_ SG_ 420 FLDirectionIndicatorBulbFail "Indicates that the Front Left Direction Indicator bulb has failed.

(Reduced length signal name to avoid CANalyzer error.)";
CM_ SG_ 420 FRDirectionIndicatorBulbFail "Indicates that the Front Right Direction Indicator bulb has failed.

(Reduced length signal name to avoid CANalyzer error.)";
CM_ SG_ 420 LeftStopLampBulbFailure "Indicates if the Left Stop Lamp Bulb has failed.";
CM_ SG_ 420 LowBeamFailureLH "Signal to raise warning symbol/message in the IPC when a left hand LED low beam has failed.";
CM_ SG_ 420 LowBeamFailureRH "Signal to raise warning symbol/message in the IPC when a right hand LED low beam has failed.";
CM_ SG_ 420 LSMAlsDippedBeamReqB "this signal is used to control speed profile of LSM features according to external ambient lighting condition as determined by Dipped Beam recommendation status";
CM_ SG_ 420 MainBeamStatus "Indicates the status of the Headlamp Main Beam.";
CM_ SG_ 420 NaturalLight "Provides an indication of the outside light status.";
CM_ SG_ 420 RightStopLampBulbFailure "Indicates if the Left Stop Lamp Bulb has failed.";
CM_ SG_ 420 RLDirectionIndicatorBulbFail "Indicates if the Rear Left Indicator Bulb is operable or has failed.

(Reduced length signal name to avoid CANalyzer error.)";
CM_ SG_ 420 RLPositionLampBulbFailure "Indicates when the Left Rear side lamp bulb has failed.";
CM_ SG_ 420 RRDirectionIndicatorBulbFail "Indicates if the Rear Right Indicator Bulb is operable or has failed.

(Reduced length signal name to avoid CANalyzer error.)";
CM_ SG_ 420 RRPositionLampBulbFailure "Indicates when the Right Rear side lamp bulb has failed.";
CM_ SG_ 420 SCLWarningReq "Steering Column Lock Warning - used to alert the user of potential issue regarding the Steering Column Lock system";
CM_ SG_ 420 SidelightStatus "Status of the Sidelights.";
CM_ SG_ 420 SupMainBeamRoutineReq "Signal from BCM to HCMA/B to activate supplementary main beam via routine. ";
CM_ SG_ 420 WipeSpeedRainSensor "Wipe speed value sent to WMM (FSJB) from RLS.  When selected CarCode is X250 without multi-speed wipers (without WMM), i.e. 2 speed wipers are fitted, RLS shall use logical values of 0 for wipers OFF, 1 for wipers required in intermittent or slow mode and 7 for wipers required in fast mode.";
CM_ SG_ 421 BeltReminderSensor "This is the status of the front passenger seat occupancy switch.";
CM_ SG_ 421 BeltReminderSensorRL "This is the status of the rear left passenger seat occupancy switch.";
CM_ SG_ 421 BeltReminderSensorRM "This is the status of the rear middle passenger seat occupancy switch.";
CM_ SG_ 421 BeltReminderSensorRR "This is the status of the rear right passenger seat occupancy switch.";
CM_ SG_ 421 BeltRmderSensorRow1M "Status of the front middle seat belt buckle switch";
CM_ SG_ 421 BeltRmderSensorRow3LMS "The signal indicates belt buckle status of the ROW-3 left hand side seat belt buckle.";
CM_ SG_ 421 BeltRmderSensorRow3M "The signal indicates belt buckle status of the ROW-3 middle seat belt buckle";
CM_ SG_ 421 BeltRmderSensorRow3RMS "The signal indicates belt buckle status of the ROW-3 right hand side seat belt buckle.";
CM_ SG_ 421 BrakeLampOnStatus "This signal indicates the state of illumination of the brake lamps under driver braking and autonomous braking (i.e. by the DSC system). The signal reports whether at least one brake lamp is correctly responding to demands for illumination. It also reports a non-latching fault value if no lamps are responding correctly.

Signal encoding: Added in here as encoding description field not sufficient for text.

00 = One or more brake lamps successfully turned off in response to driver braking AND DSC braking requests to turn brake lamps off.

01 = One or more brake lamps successfully turned on in response to driver braking OR DSC braking requests to turn brake lamps on.

11 = None of the three brake lamps can be illuminated in response to driver braking OR DSC braking requests. This fault state does not latch - it is only reported while the fault state is present.";
CM_ SG_ 421 CentralLockStatus "Provides status information for the central locking.";
CM_ SG_ 421 DriverSteerColMovReq "Indicates when the Driver is moving the Steering column or not
";
CM_ SG_ 421 DRLStatus "Status of the DRL lamps";
CM_ SG_ 421 RainSenseStatus "Description of signal -This signal provides the IPK status of the current RainSenseStatus. If set, RainSenseStatus = 1 (Rain sensor control), the front wiper shall operate in the auto mode if selected via the column wiper stalk. If RainSenseStatus = 0, (intermittent mode), the front wiper shall operate in the intermittent mode if selected via the column wiper stalk.  Status bit sent reference current intermittent/auto wipe mode

0 = intermittent mode 1 = auto mode.";
CM_ SG_ 421 RainSensorActive "Used for activation or deactivation of rain sensor system.";
CM_ SG_ 421 RemoteRaiseLower "Decoded signal from PLIP to indicate when driver has requested remote control of the vehicle's air-suspension to assist in boot loading or trailer connection/disconnection.";
CM_ SG_ 421 SteerColState "Indicates the position of the Steering column between Driver Position and Automation Position";
CM_ SG_ 422 BacklightIntensity "The backlight intensity level is transmitted by the IPC on X150 and X250.
The backlight intensity level is transmitted by the BCM on L322, T5 and X351.

";
CM_ SG_ 422 BacklightScreenIntensity "Type Value Scale Offset Interpretation 
Physical Range 0-254 0.3937 0 Backlight Screen Intensity % 
Logical Value 255 Fault condition Present ";
CM_ SG_ 422 BacklightStatus "Signal to turn search illumination of switches on as required";
CM_ SG_ 422 DoorStatus "Indicates the status of the doors.

L538 Only
'The group DoorStatusGrp is required to keep DoorStatus and DriverDoorStatusQF in the same CAN frame for L538.  It is not a requirement for the data to be calculated and written at the same time in the application software of the transmiting node.'

Bit 0 = DDStatus, 0 = open, 1 = closed
Bit 1 = PDStatus, 0 = open, 1 = closed
Bit 2 = LRDStatus, 0 = open, 1 = closed
Bit 3 = RRDStatus, 0 = open, 1 = closed
Bit 4 = TailgateStatus, 0 = open, 1 = closed
Bit 5 = EngineHoodStatus, 0 = open, 1 = closed";
CM_ SG_ 422 GearLeverPosition "Gear lever position.
";
CM_ SG_ 422 HeadlampExitDelayStatus "Status of the Headlamp Delay mode in the lighting S/W to the infotainment.
As per DCST Strategy, function now in IPC.";
CM_ SG_ 422 NightStatus "This signal tells a day and night condition based on the cluster and HLDF ambient light sensor.";
CM_ SG_ 422 TrailerConnection "Signal indicating if trailer is connected or not.";
CM_ SG_ 422 WasherFrontCmd_EUCD "Controls washing of the windscreen.
Wiper stalk command for: windscreen washing.
";
CM_ SG_ 422 WiperStatus "Specifies the current operating status of the front wiper system.";
CM_ SG_ 935 AmbientLightValueRLS "LIN signal from RAIN sensor to provide the light values in the LUX or cd/m2";
CM_ SG_ 935 AutoBlindEnableStatus "Confirmation from the BCM on whether the AutoBlind feature is enabled or disabled.";
CM_ SG_ 935 BatteryStateText "New state encoded signal to report battery condition in Transport Mode only. These messages will not be seen by the end customer.
";
CM_ SG_ 935 BCM_EPBWarningLamp "This signal is a request from the BCM for the instrument pack to control its EPB warning lamp.  This is due to a hard-wired input from the EPB being activated.
";
CM_ SG_ 935 BrakeFluidLevelWarning "To give information about low brake fluid level.";
CM_ SG_ 935 BrakePadWearLampReq "This signal controls a brake pad wear indication.";
CM_ SG_ 935 OdometerBackUp_BCM "This is the BCM's copy of the total distance travelled by the vehicle.


0 to 16777214 = *1 km

16777215 = 'Invalid value'";
CM_ SG_ 935 ParkClimateReq "This signal permits the park climate function to be requested.";
CM_ SG_ 935 TrailerLightTestActive "Indicates if trailer light test mode is active";
CM_ SG_ 935 TRStatus "Transit Relay status";
CM_ SG_ 935 ValetStatus "Indicates the current status of Valet.";
CM_ SG_ 935 WasherFluidLevelLow "Request for washer fluid level warning to be displayed.";
CM_ SG_ 935 WashingCycleActive_s "This signal indicates whether the front wipers are in a wash/wipe-cycle.
This signal is sent from the BCM and simulates the signal from WMM in cars without WMM.";
CM_ SG_ 424 AutoSwitchDRLStatusReq "New signal from BCM to IPC to request DRL status message and graphic. ";
CM_ SG_ 424 FuelSensorActiveSide "Level of fuel in tank as measured by SENDER1 at ADC output. This value is the 'raw' output of the ADC; is completely undamped and so sensitive to 'slosh'.
";
CM_ SG_ 424 FuelSensorPassSide "Level of fuel in tank as measured by SENDER2 at ADC output. This value is the 'raw' output of the ADC; is completely undamped and so sensitive to 'slosh'.

";
CM_ SG_ 424 ImmobiliserWarning "ImmobiliserWarning - Informs the user that the engine has not started due to Immobilisation not clearing. Feature of Start Auth to switch the ignition off if Immo Fails, with this in mind a warning will be present to inform user of failed reason.";
CM_ SG_ 424 ImmoNumberOfKeys "This signal shall be used to provide a number of keys display (service menu) and a warning to alert the user that additional keys have been added outside of JLR process, applies to additional keys only.";
CM_ SG_ 424 LoadSettings "To inform which Driver Id is currently active (bits 0-2).  
To inform if Remote Memory Recall is enabled (bit 7), if Reverse Mirror Dip is enabled (bit 8),if Easy Entry Exit is enabled (bit 9).


b0-b2:Not Personalized Driver and DriverId 1, 2, 3, 4, 5, 6;
   000 DriverId 0 (Not Personlized Driver)
   001 DriverId 1 
   010 DriverId 2
   011 DriverId 3
   100 DriverId 4 (FoE/LR only)
   101 DriverId 5 (LR Only)
   110 DriverId 6 (LR Only)
   111 Not used
b3-b15 , 1=Enable, 0=Disable
b3: Not Used
b4: EntSettings (Audio);
b5: NavSettings;
b6: ClimateSettings;
b7: PhysicalSettings (SeatAndMirrorForward);
b8: MirrorRearward;  (FoE, LR only); 
b9: EasyEntryEasyExit  (FoE, LR only); 
b10: HLA (FoE only); 
b11: ACCFCWSettings; 
b12: AutoTransmission (FoE only); 
b13: CCDSettings; (FoE only); 
b14: VehicleSettings (VCC), Steering Setup (FoE); 
b15: MenuBlocked (VCC), AutoFold (JLR);";
CM_ SG_ 424 RemoteGlobalCloseStatus "Status of the On/Off remote global close toggle in the locking S/W to the infotainment.";
CM_ SG_ 424 RemoteGlobalOpenStatus "Status of the On/Off remote global open toggle in the locking S/W to the infotainment.";
CM_ SG_ 424 StgColLockGndEnableCmd "Steering Column Lock Ground Enable Command.

Encoding:
Bit 0 = Unlock / Lock (1 = Unlock)
Bit 1 = On / Off (1 = On)";
CM_ SG_ 424 StgColLockWarningReq "SteeringColumnLockWarning - used to alert the user of potential issue regarding the Steering Column Lock system.";
CM_ SG_ 425 AlarmSensorFailureInd "Signal requests INST pack to display a message if an Alarm Sensor has failed.";
CM_ SG_ 425 ColumnAdjustSwitchStatus "Signal to communicate column adjust switch status to IPK to trigger message center alerts.";
CM_ SG_ 425 DIAnimationEnableSta "New signal from BCM to IPC to confirm status of directional indicator animation.";
CM_ SG_ 425 DriveAwayLockingStatus "Status of the On/Off drive away locking toggle in the locking S/W to the infotainment.";
CM_ SG_ 425 FactoryState "Signal to confirm and latch Factory Mode";
CM_ SG_ 425 LastAlarmCause "Last Alarm Cause - allow up to 63 possible alarm triggers.";
CM_ SG_ 425 LockChirpsStatus "Status of the On/Off Lock Chirps toggle in the locking S/W to the IPC/DIM.";
CM_ SG_ 425 OilPressureSwitchRaw "Raw status of Oil Pressure Switch. No filtering applied.";
CM_ SG_ 425 RemovePlugWarning "Alert presented to the Driver if an attempt to initialise the vehicle is performed with an external charging device attached.";
CM_ SG_ 425 SinglePointEntryStatus "Status of the Single Point Entry (SPE)";
CM_ SG_ 425 SmartKeyWarningReq "SmartKeyWarning - used to display appropriate warning message in the Cluster. 
";
CM_ SG_ 425 StealthModeStatus "Signal carrys feedback information about whether the stealth mode feature is currently enabled and whether the feature is currently active.

Functionality of stealth mode described in IPK eTracker   9750160
[Stealth_IPC_001]
Stealthmode in the IPC shall be 'enabled'/'disabled' by the 'StealthmodeStatus' MS_CAN message.

[Stealth_IPC_002]
Stealthmode in the IPC shall be deemed 'enabled' when the 'StealthmodeStatus' MS_CAN message conveys the value '1'.

[Stealth_IPC_003]
Stealthmode in the IPC shall be deemed 'disabled' when the 'StealthmodeStatus' MS_CAN message conveys the value '0'.

'Stealthmode' - 'Torchlight Effect' Interaction
-----------------------------------------------
{Reference: KFC 563 v6}

[Stealth_IPC_004]
The IPC shall turn ON the torchlight effect over-riding the (user's selection)/(torchlight effect feature manager's choice) when Stealthmode is deemed 'enabled'.

[Stealth_IPC_005]
The IPC shall restore control of the torchlight effect to the (user's selection)/(torchlig";
CM_ SG_ 425 TimerActivationStatus "Status of timer activation.";
CM_ SG_ 425 WiperWinterParkStatus "This signal provides the IPK status of the front wiper park position.";
CM_ SG_ 225 CentralLockLastCmdOrig2 "Location responsible for the last central lock command";
CM_ SG_ 225 CentralLockStatus2 "Provides status information for the central locking.";
CM_ SG_ 225 CLock_RC2 "Central Lock Command Encryption/Rolling Code";
CM_ SG_ 225 DriverDoorLockCmd "Driver's door locking/unlocking command

00 (0) = Undefined
01 (1) = Single Lock (ext handles inhibit)
10 (2) = Unlock (Un-Single Lock & Un-Double Lock) - 'Provisionally Unlocked'
11 (3) = Double Lock (int handles inhibit)";
CM_ SG_ 225 FrontPassDoorLockCmd "Front passenger door locking/unlocking command";
CM_ SG_ 225 RearDriverDoorLockCmd "Driver's door locking/unlocking command

00 (0) = Undefined
01 (1) = Single Lock (ext handles inhibit)
10 (2) = Unlock (Un-Single Lock & Un-Double Lock) - 'Provisionally Unlocked'
11 (3) = Double Lock (int handles inhibit)";
CM_ SG_ 225 RearPassDoorLockCmd "Rear passenger's side door locking/unlocking command";
CM_ SG_ 226 ImmoAuthPKeyMainReq "Passive Control Challenge

The MSB of the signal must be written to the COM layer first (with an offset of zero in wr_bytes() ) and therefore transmitted on the bus first.
Similarly, subscribing modules will receive the MSB of the signal when they call rd_bytes(0).

E.g. wr_bytes(0) = published_signal_MSB;

Subscribed_Signal_MSB = rd_bytes(0);
";
CM_ SG_ 227 CLockCmd_2 "Central Locking command to control the latch actuators.

Bitcoded:
CentralLock                   0000 0001
CentralUnlock                0000 0010
CentralDL                       0000 0011
CentralUnlockDL           0000 0100
TrunkLock                     0000 0101
TrunkUnlock                  0000 0110
DDUnlock                      xxx1 1111
PDUnlock                      xx1x 1111
LRUnlock                      x1xx 1111
RRUnlock                      1xxx 1111
DDLock                         xxx1 0000
PDLock                         xx1x 0000
LRLock                         x1xx 0000
RRLock                         1xxx 0000
CrashUnlock                  0000 1000 ";
CM_ SG_ 227 ePEPSLockResult "BCM to RFA to Smart Key - ePEPS 'Walk Away' Lock confirmation signal. ";
CM_ SG_ 227 GlobalWindowReq "Global windows open/close CAN message (includes hood close too!)";
CM_ SG_ 227 LocationOfKeysRequest "BCM Scan request for Location of ALL Local (in vicinity of vehicle) Smart Keys.
Useage of this signal to be for limited UseCases only to limit battery useage.  All potential users to confirm with BCM & ePEPS (RFA) before using.";
CM_ SG_ 227 PKExteriorScanReq "Body system requests a scan of a particular exterior location";
CM_ SG_ 227 PKInteriorScanReq "Body System Interior Scan Request for Memory System Functionality

(1 BIT UNSIGNED TYPE)";
CM_ SG_ 227 POTUpperAndLowerReq "Signal from BCM to RGTM and RGTMB to power open/close both Upper and Lower tailgates.";
CM_ SG_ 227 PowerTailgateReq "Message telling RGTM and/or RGTMB to stop/open/close.

Signal also used on X351, however state 6 is not used. ";
CM_ SG_ 227 PowerTailgateReqLwr "Signal requesting the lower tailgate operation";
CM_ SG_ 227 PuddleLightActivation "The PJB sends a signal to PDM and DDM  to activate the PuddleLightActivation.

On X150/X250 this sporadic signal is packed into a periodic frame.";
CM_ SG_ 227 RFARequestAck "BCM to RFA to Smart Key acknowlege of Request receipt - 'Waiting for Response LED flash on Smart Key'.";
CM_ SG_ 227 RKELockResult "BCM to RFA to Smart Key - Remote Lock confirmation signal.";
CM_ SG_ 502 CLock_RC "Central Lock Command Encryption/Rolling Code";
CM_ SG_ 230 AlarmModeMS "Vehicle Alarm Mode";
CM_ SG_ 230 DirectionIndication "Description for X150 and X250
========================

Provides an output to the cluster (light indication) to show the direction indication mode selected by the user.
This sporadic signal is packed into a periodic frame.

Description for L322, L538 and T5
======================

This signal DirectionIndication signal is sent to DriverInformationMgr and rear view mirror on right and left side, when the DirectionIndication is activated. The DriverInformationMgr will inform the Driver/User by an indicator who will illuminate on the DriverIformationMgr. Observation (the indicator will illuminate when DirectionIndication are activated in mode Left, Right and Hazard).
";
CM_ SG_ 230 DirectionIndicationINST "When a direction indicator bulb is open circuit,
allows side repeaters (controlled by door modules) to flash at a
different rate to direction indication telltales in Instrument Pack.

";
CM_ SG_ 230 ImmoFailureInd "Immobilisation failure indication";
CM_ SG_ 230 InteriorLightMode "Signal used by the instrument pack to display the status of the interior light mode.  (As current T5 and L322) Signal functionality in Ipack Requirements etracker 4804791.

This signal will only be written when the user requests a change in mode.

It will be packed in a periodic frame, with an update bit which tells the cluster when a message display is required.";
CM_ SG_ 230 LDWSwitchReq "Position of the LDW hardwired switch.";
CM_ SG_ 230 LowBeamIndication "This signal identifies the status of the low  beam lamps.";
CM_ SG_ 230 TrailerDILeft "Trailer Left DI Request";
CM_ SG_ 230 TrailerDirectionInd "This signal TrailorDirectionIndication signal is sent to DriverInformationMgr object when the TrailorDirectionIndication is activated. The DriverInformationMgr will inform the Driver/User by an indicator which will illuminate on the DriverInformationMgr. Observation (the indicator will illuminate when TrailorDirectionIndication is activated in mode On).";
CM_ SG_ 230 TrailerDIRight "Trailer Right DI Request";
CM_ SG_ 230 TrailerStopLamp "Trailer Stop Lights Request";
CM_ SG_ 230 WakeShutDownEnableSta "This signal feedback status of Wakeup Shutdown Sequence  to IMC";
CM_ SG_ 794 BSBattSOC "Battery State of charge  (referenced to estimated Capacity not including sulphation losses) at normalised temperature";
CM_ SG_ 794 BSBattVoltage "Battery voltage measured with battery sensor";
CM_ SG_ 270 SuspensionHeightFL "Filtered signal from front left air suspension height sensor";
CM_ SG_ 270 SuspensionHeightFR "Filtered signal from front right air suspension height sensor";
CM_ SG_ 270 SuspensionHeightRL "Filtered signal from rear left air suspension height sensor";
CM_ SG_ 270 SuspensionHeightRR "Filtered signal from rear right air suspension height sensor";
CM_ SG_ 207 AutonomyLevel "Provides the autonomy level that the vehicle is operating within.";
CM_ SG_ 207 DADCHazLightReq "A request to operate the hazard lights from an automated driving feature.";
CM_ SG_ 207 DADCHvacAutoMode "Indicates to the HVAC, the mode of operation requested by ADAS
";
CM_ SG_ 207 DADCPCVehState "A signal that is used to determine whether the vehicle is in a pre crash state. ";
CM_ SG_ 207 DADCSteerMovReq "This is a HMI request from the Level 3 ADAS systems to move the steering column to a predetermined position to allow the driver more space during piloted driving.
";
CM_ SG_ 207 DADCWiperModeReq "A request to turn the windscreen wipers to the auto mode to support clear vision for the forward looking camera when an automated driving feature is activate.";
CM_ SG_ 207 HapticSeatReq "Signal to request a haptic actuation on the Driver seat";
CM_ SG_ 207 HapticSeatReqAC "This counter forms part of a safety-related signal group.
It is incremented by the task which generates the data set used in the CRC calculation, and may be used to determine the health of the data generation task.
Refer to STJLR 18.036 for more detail.";
CM_ SG_ 207 HapticSeatReqCS "This CRC shall be calculated in compliance with STJLR 18.036 Version 5.
The Data Segment Polynomial shall be constructed from the details in the network configuration file.";
CM_ SG_ 207 HeadLampModeReq "Request to Change the headLamp mode when in an automated driving feature";
CM_ SG_ 207 LDSOnStatus "Provides information in regards to the ON/OFF status of the lane assist features: LDW; LKA ; TJA/ICA.
If one of the lane assist features is switched ON, then the signal in published with value '1 = ON'. This signal state indicates that the button shall be lit.
In none of the lane assist features is switched ON, the signals is publised with value '0 = OFF'. This signal state indicates that the button shall not be lit.";
CM_ SG_ 1010 DrvrMirPosLeRiAct "Mirror position left/right";
CM_ SG_ 1010 DrvrMirPosUpDwnAct "Mirror position up/down";
CM_ SG_ 1010 M1DrvrMirPosLeRiAct "Memory 1 Mirror position left/right";
CM_ SG_ 1010 M1DrvrMirPosUpDwnAct "Memory 1 Mirror position up/down";
CM_ SG_ 1010 M2DrvrMirPosLeRiAct "Memory 2 Mirror position left/right";
CM_ SG_ 1010 M2DrvrMirPosUpDwnAct "Memory 2 Mirror position up/down";
CM_ SG_ 1010 M3DrvrMirPosLeRiAct "Memory 3 Mirror position left/right";
CM_ SG_ 1010 M3DrvrMirPosUpDwnAct "Memory 3 Mirror position up/down";
CM_ SG_ 498 AccessMode "Access Mode switch status";
CM_ SG_ 498 ChildLockCmd "Central Locking command to control the Child Lock actuators.";
CM_ SG_ 498 DDClawSwitchStatus "Drivers Side Door Latch Claw Switch Status";
CM_ SG_ 498 DDMReqBusAwake "Single bit message to report DDM requesting CAN keepawake.";
CM_ SG_ 498 DDMSetngAppl "Indicates If a request to change settings would be sucsesfull.";
CM_ SG_ 498 DDoorLatchStatus "Drivers Door Latch Status";
CM_ SG_ 498 DDPawlSwitchStatus "Drivers Side Door Latch Pawl Switch Status";
CM_ SG_ 498 DriverDoorSCAStatus "A signal reporting the status of the Drivers Side Door Soft Close Actuator - SCA.";
CM_ SG_ 498 DrvMirrorStatus "Provide folding status of driver wing mirror";
CM_ SG_ 498 DZMDrivLeftHmiOp "Used to convey BSM door mirror HMI state back to the BSM modules. Message Inactive indicates that the DZM has determined that its physical location is such that the status information is contained in the other signal (i.e. If driver left DZM then passenger left signal will contain 'message inactive')";
CM_ SG_ 498 DZMDrivRightHmiOp "Used to convey BSM door mirror HMI state back to the BSM modules. Message Inactive indicates that the DZM has determined that its physical location is such that the status information is contained in the other signal (i.e. If driver left DZM then passenger left signal will contain 'message inactive')";
CM_ SG_ 498 MemRecallCancelMirror "MemoryRecallCancelMirror.

";
CM_ SG_ 498 MirrorFoldStatus "Provides feedback of the current combined folding status of the driver and passenger wing mirrors. ";
CM_ SG_ 498 PCLMessageReq "Signal to request Power Child Lock message display";
CM_ SG_ 498 SeatMem1ButtonStatD "Signal from driver door zone module to driver seat module to detail memory 1 button status.

Logical value 0-Inactive/off
Logical value 1-Active/on";
CM_ SG_ 498 SeatMem2ButtonStatD "Signal from driver door zone module to driver seat module to detail memory 2 button status.

Logical value 0-Inactive/off
Logical value 1-Active/on";
CM_ SG_ 498 SeatMem3ButtonStatD "Signal from driver door zone module to driver seat module to detail memory 3 button status.

Logical value 0-Inactive/off
Logical value 1-Active/on";
CM_ SG_ 498 SeatMemLEDStatD "Signal from driver door zone module to driver seat module to detail memory LED status.

Logical value 0-Inactive/off
Logical value 1-Active/on";
CM_ SG_ 498 SeatMemSetBtnStatD "Signal from driver door zone module to driver seat module to detail memory set button status.

Logical value 0-Inactive/off
Logical value 1-Active/on";
CM_ SG_ 242 DDHandleStatus "'HandleStatus' is a signal to be broadcast from DDM, PDM, DRDM and PRDM. The RFA will subscribe to this sporadic CAN signal to ignore the PELock microswitch press as the handle is being deployed (SW containment for mechanical issue)on old passive entry trchnilogy and will be used as a diagnostic CAN signal on ePEPS technology.";
CM_ SG_ 242 DDLockSwitchPress "A Signal (from DDZM to BCM) to inform that the Drivers Door Central Lock Switch has been pressed.";
CM_ SG_ 242 DDUnLockSwitchPress "A Signal (from DDZM to BCM) to inform that the Drivers Door Central Unlock Switch has been pressed.";
CM_ SG_ 242 DriverWindowPosition "Information about the position of driver window";
CM_ SG_ 242 PassMirrorCmd "DDM to PDM mirror commands.
";
CM_ SG_ 242 PassWindowCmd "Passenger window command.

";
CM_ SG_ 242 RearDriverWindowCmd "Event + periodic";
CM_ SG_ 242 RearPassWindowCmd "Event + periodic";
CM_ SG_ 242 RearWindowDisableCmd "Event + periodic";
CM_ SG_ 1615 DevID_RGTM_Rx1 "Development signal , only on MS-CAN

This signal is received by the RGTM function.

This signal may never be written to in a vehicle running in normal operation! 
It is forbidden to activate the frame carrying this signal in a production vehicle running in normal operation! 
The supplier of the node publishing this signal is held liable for any problems or errors in the vehicle which are caused by this signal and the frame it is contained in!
";
CM_ SG_ 1614 DevID_RGTM_Tx1 "Development signal , only on MS-CAN

This signal is transmitted by the RGTM function.

This signal may never be written to in a vehicle running in normal operation! 
It is forbidden to activate the frame carrying this signal in a production vehicle running in normal operation! 
The supplier of the node publishing this signal is held liable for any problems or errors in the vehicle which are caused by this signal and the frame it is contained in!
";
CM_ SG_ 1643 DevID_RGTMB_Rx1 "Development signal , only on MS-CAN

This signal is received by the RGTMB function.

This signal may never be written to in a vehicle running in normal operation! 
It is forbidden to activate the frame carrying this signal in a production vehicle running in normal operation! 
The supplier of the node publishing this signal is held liable for any problems or errors in the vehicle which are caused by this signal and the frame it is contained in!
";
CM_ SG_ 1642 DevID_RGTMB_Tx1 "Development signal , only on MS-CAN

This signal is transmitted by the RGTMB function.

This signal may never be written to in a vehicle running in normal operation! 
It is forbidden to activate the frame carrying this signal in a production vehicle running in normal operation! 
The supplier of the node publishing this signal is held liable for any problems or errors in the vehicle which are caused by this signal and the frame it is contained in!
";
CM_ SG_ 476 RockerSwitch1Req_a "Generic rocker switch pack - switch 1 request";
CM_ SG_ 476 RockerSwitch2Req_a "Generic rocker switch pack - switch 2 request";
CM_ SG_ 476 SunRoofFrBlindBtnReq_A "SunRoof Blind Button Press indication";
CM_ SG_ 476 TaskLightRelaxBtnReq_A "Signal to indicate Task Lighting
Intensity Button press";
CM_ SG_ 476 TaskLightWorkBtnReq_A "Signal to indicate Task Lighting Intensity Button Press";
CM_ SG_ 452 AudioMuteDR "Audio Mute Driver Rear";
CM_ SG_ 452 DRDMReqBusAwake "Single bit message to report DRDM requesting CAN keepawake.";
CM_ SG_ 452 RearDDClawSwitchStatus "REAR Drivers Side Door Latch Claw Switch Status";
CM_ SG_ 452 RearDDPawlSwitchStatus "REAR Drivers Side Door Latch Pawl Switch Status";
CM_ SG_ 452 RearDrivDoorSCAStatus "A signal reporting the status of the REAR Passengers Side Door Soft Close Actuator - SCA.";
CM_ SG_ 452 RearDriverREDHMIStatus "Rear exit detection HMI fault status for rear driver's door";
CM_ SG_ 452 SeatMem1ButtonStatDR "Signal from door zone module to seat module to detail memory button status.
";
CM_ SG_ 452 SeatMem2ButtonStatDR "Signal from door zone module to seat module to detail memory button status.
";
CM_ SG_ 452 SeatMem3BUttonStatDR "Signal from door zone module to seat module to detail memory button status.
";
CM_ SG_ 452 SeatMemLEDStatDR "Signal from door zone module to seat module to detail memory button status.
";
CM_ SG_ 452 SeatMemSetBtnStatDR "Signal from door zone module to seat module to detail memory button status.
";
CM_ SG_ 551 DRDoorLatchStatus "Drivers Rear Door Latch Status";
CM_ SG_ 551 DRHandleStatus "'HandleStatus' is a signal to be broadcast from DDM, PDM, DRDM and PRDM. The RFA will subscribe to this sporadic CAN signal to ignore the PELock microswitch press as the handle is being deployed (SW containment for mechanical issue)on old passive entry trchnilogy and will be used as a diagnostic CAN signal on ePEPS technology.";
CM_ SG_ 551 DriverRearWindowPos "Information on position of Drivers side rear window";
CM_ SG_ 551 RDDLockSwitchPress "A Signal (from RDDZM to BCM) to inform that the Rear Drivers Door Central Lock Switch has been pressed.";
CM_ SG_ 551 RDDUnLockSwitchPress "A Signal (from RDDZM to BCM) to inform that the Rear Drivers Door Central Unlock Switch has been pressed.";
CM_ SG_ 1291 NMmessageDSM "Network Management Signal. This signal contains Network Management Data. This data includes the DA (Destination Address), CF (Control Field) and up to 6 data bytes of user defined data (currently not used by Jaguar). 

Description of station manager bit field detailing each application function (station manager function 1-16)
Bit 0 - Driver Seat Movement
Bit 1 - Memory Recall
Bit 2 - Memory Save
Bit 3 - Cancel Memory Recall
Bit 4 to Bit 15 - Unused

The MSB of the signal must be written to the COM layer first (with an offset of zero in wr_bytes() ) and therefore transmitted on the bus first.
Similarly, subscribing modules will receive the MSB of the signal when they call rd_bytes(0).

E.g. wr_bytes(0) = published_signal_MSB;

Subscribed_Signal_MSB = rd_bytes(0);

Refer 'Software Requirement Specification for CAN Network Management' (VCC doc no 31812308)

CAN ID:
X150/X250 - 0x50B
GMRDB - 0x50B";
CM_ SG_ 400 DriverCancelSeat "To inform rear seats when the driver seat is manually adjusted so rear seat movement can be cancelled (used for ISCM: Intelligent Seat Cargo Mode)";
CM_ SG_ 400 DriverSeatMovementStat "Signal from DSM to rear seats to inform Driver seat ststus";
CM_ SG_ 400 DrvSeatOccupantStatus "Signal to indicate RLSM, RRSM of Driver Seat Occupancy Status";
CM_ SG_ 400 FoldAllSeatsReqDSM "Signal to inform PSM for a fold all request on 2nd & 3rd Row seats";
CM_ SG_ 400 MemRecallCancelSeat "Cancel memory recall when seat switch activated";
CM_ SG_ 400 R2ISCM60SeatCancelDSM "Signal to inform PSM, RearLeft 60 seat cancelled ISCM movement ";
CM_ SG_ 400 R2ISCM60SeatInSP1DSM "Signal to inform PSM, RearLeft 60 seat reached Safe position in ISCM movement ";
CM_ SG_ 400 R3RightSeatISCMCancDSM "Signal to inform PSM, Row3 Right seat cancelled ISCM movement ";
CM_ SG_ 400 R3RightSeatISCMReqDSM "Signal to inform PSM for RearLeft 60 seat ISCM movement";
CM_ SG_ 400 RLSeatMsgAvailFrInt "Intermediate Massage signals DSM to PSM";
CM_ SG_ 400 RLSeatMsgModStatFrInt "Intermediate Massage signals DSM to PSM";
CM_ SG_ 400 RLSeatMsgModStatInt "Intermediate Massage signals DSM to PSM";
CM_ SG_ 400 RLSeatMsgStatFrInt "Intermediate Massage signals DSM to PSM";
CM_ SG_ 400 RockerSwitch1ReqDSM_a "Generic rocker switch pack - switch 1 request";
CM_ SG_ 400 RockerSwitch1ReqDSM_b "Generic rocker switch pack - switch 1 request";
CM_ SG_ 400 RockerSwitch2ReqDSM_a "Generic rocker switch pack - switch 2 request";
CM_ SG_ 400 RockerSwitch2ReqDSM_b "Generic rocker switch pack - switch 2 request";
CM_ SG_ 400 UnFoldAllSeatsReqDSM "Signal to inform PSM for a unfold all request on 2nd & 3rd Row seats";
CM_ SG_ 994 DrvrStPosCushAct "Driver seat Position cushion";
CM_ SG_ 994 DrvrStPosFrAftAct "Driver seat Position Fore-Aft";
CM_ SG_ 994 DrvrStPosHeadAct "Driver seat Position head rest";
CM_ SG_ 994 DrvrStPosRecAct "Driver seat Position Recline";
CM_ SG_ 994 DrvrStPosTiltAct "Driver seat Position Tilt";
CM_ SG_ 994 DrvrStPosUpDownAct "Driver seat Position up-Down";
CM_ SG_ 994 DrvrStSetngAppl "Driver seat settings sucsesfully applied";
CM_ SG_ 996 DSMReqBusAwake "Single bit message to report whether Lo-line DSM is requesting keepawake on CAN.";
CM_ SG_ 996 M1DrvrStPosCushAct "Driver seat Position cushion";
CM_ SG_ 996 M1DrvrStPosFreAftAct "Driver seat Position Fore-Aft";
CM_ SG_ 996 M1DrvrStPosHeadAct "Driver seat Position head rest";
CM_ SG_ 996 M1DrvrStPosRecAct "Driver seat Position Recline";
CM_ SG_ 996 M1DrvrStPosTiltAct "Driver seat Position Tilt";
CM_ SG_ 996 M1DrvrStPosUpDownAct "Driver seat Position up-Down";
CM_ SG_ 998 M2DrvrStPosCushAct "Driver seat Position cushion";
CM_ SG_ 998 M2DrvrStPosFrAftAct "Driver seat Position Fore-Aft";
CM_ SG_ 998 M2DrvrStPosHeadAct "Driver seat Position head rest";
CM_ SG_ 998 M2DrvrStPosRecAct "Driver seat Position Recline";
CM_ SG_ 998 M2DrvrStPosTiltAct "Driver seat Position Tilt";
CM_ SG_ 998 M2DrvrStPosUpDownAct "Driver seat Position up-Down";
CM_ SG_ 1000 M3DrvrStPosCushAct "Driver seat Position cushion";
CM_ SG_ 1000 M3DrvrStPosFrAftAct "Driver seat Position Fore-Aft Memory";
CM_ SG_ 1000 M3DrvrStPosHeadAct "Driver seat Position head rest";
CM_ SG_ 1000 M3DrvrStPosRecAct "Driver seat Position Recline";
CM_ SG_ 1000 M3DrvrStPosTiltAct "Driver seat Position Tilt";
CM_ SG_ 1000 M3DrvrStPosUpDownAct "Driver seat Position up-Down";
CM_ SG_ 396 DriverSeatMassageStat "The status of the driver's seat massage system.";
CM_ SG_ 396 DrvSeatInhib2ndRow "Inform of ability to use move request for drivers side 2nd row.";
CM_ SG_ 396 DrvSeatInhib3rdRow "Inform of ability to use move request for drivers side 3rd row";
CM_ SG_ 396 DrvSeatPosition2ndRow "Status of Drivers seat 
positon on 2nd row";
CM_ SG_ 396 DrvSeatPosition3rdRow "Status of Drivers seat 
positon on 3rd row";
CM_ SG_ 396 HapticSeatStatus "Indicates the haptic seat feedback state.";
CM_ SG_ 396 MemoryPosLoadReq "Memory recall";
CM_ SG_ 396 MemoryPosStoreReq "Memory save";
CM_ SG_ 394 DriverSeatMovement "Driver Seat Movement.";
CM_ SG_ 394 DriverSeatMsgAvail "States whether the drivers' seat massage system is available";
CM_ SG_ 394 DrvSeatMasgIntStat "Signal transmitted by the massage module to HLDF to confirm the active massage intensity on the front driver seat.";
CM_ SG_ 394 DrvSeatMasgLocStat "Driver Seat: Current Massage Location Status
";
CM_ SG_ 394 DrvSeatMasgProgStat "Driver Seat: Current Massage Programme Status";
CM_ SG_ 394 DrvSeatMassageModeStat "Driver seat massage status indicator";
CM_ SG_ 394 DrvSeatMovement2ndRow "Signal to inform Infortainment of the status of the seat
";
CM_ SG_ 394 DrvSeatMovement3rdRow "Signal to inform Infortainment of the status of the seat
";
CM_ SG_ 394 DrvSeatMovmnt2ndRow "Signal to inform HLDF status of the seat";
CM_ SG_ 394 DrvSeatMovmnt3rdRow "Signal to inform HLDF status of the seat";
CM_ SG_ 394 EasyEntryEnDisStatRear "Signal from RRSM to confirm the enabled/disabled status of rear seat easy entry function";
CM_ SG_ 394 ISCMFrontSeatMovntStat "Status going to ACM / IMC to disable/enable ISCM front seat movement ";
CM_ SG_ 394 RDSeatMovement "Signal from DSM to IMC to inform NGI touchscreen of Rear Right seat movement request during Advanced Chauffeur Function.";
CM_ SG_ 394 Row1DriverMovementINH "Signal to detect occupant / fold flat inhibited
Sent to Fold Flat switchpacks & touchscreen";
CM_ SG_ 394 Row2DriverMovementINH "Signal to detect occupant / fold flat inhibited
Sent to Fold Flat switchpacks & touchscreen";
CM_ SG_ 394 Row3DriverMovementINH "Signal to detect occupant / fold flat inhibited
Sent to Fold Flat switchpacks & touchscreen";
CM_ SG_ 394 SeatMoveSelectFrStat "Status signal from DSM to FCDIM for advanced chauffeur function";
CM_ SG_ 1539 EOL_DCU_Rx1 "Development signal to freeze development frame ID's.

The MSB of the signal must be written to the COM layer first (with an offset of zero in wr_bytes() ) and therefore transmitted on the bus first.
Similarly, subscribing modules will receive the MSB of the signal when they call rd_bytes(0).

E.g. wr_bytes(0) = published_signal_MSB;

Subscribed_Signal_MSB = rd_bytes(0);



";
CM_ SG_ 1541 EOL_DCU_Rx2 "Development signal to freeze development frame ID's.

The MSB of the signal must be written to the COM layer first (with an offset of zero in wr_bytes() ) and therefore transmitted on the bus first.
Similarly, subscribing modules will receive the MSB of the signal when they call rd_bytes(0).

E.g. wr_bytes(0) = published_signal_MSB;

Subscribed_Signal_MSB = rd_bytes(0);

";
CM_ SG_ 1543 EOL_DCU_Rx3 "Development signal to freeze development frame ID's.

The MSB of the signal must be written to the COM layer first (with an offset of zero in wr_bytes() ) and therefore transmitted on the bus first.
Similarly, subscribing modules will receive the MSB of the signal when they call rd_bytes(0).

E.g. wr_bytes(0) = published_signal_MSB;

Subscribed_Signal_MSB = rd_bytes(0);
";
CM_ SG_ 1545 EOL_DCU_Rx4 "Development signal to freeze development frame ID's.

The MSB of the signal must be written to the COM layer first (with an offset of zero in wr_bytes() ) and therefore transmitted on the bus first.
Similarly, subscribing modules will receive the MSB of the signal when they call rd_bytes(0).

E.g. wr_bytes(0) = published_signal_MSB;

Subscribed_Signal_MSB = rd_bytes(0);
";
CM_ SG_ 1572 EOL_DCU_Rx5 "Development signal to freeze development frame ID's.

The MSB of the signal must be written to the COM layer first (with an offset of zero in wr_bytes() ) and therefore transmitted on the bus first.
Similarly, subscribing modules will receive the MSB of the signal when they call rd_bytes(0).

E.g. wr_bytes(0) = published_signal_MSB;

Subscribed_Signal_MSB = rd_bytes(0);

";
CM_ SG_ 1574 EOL_DCU_Rx6 "Development signal to freeze development frame ID's.

The MSB of the signal must be written to the COM layer first (with an offset of zero in wr_bytes() ) and therefore transmitted on the bus first.
Similarly, subscribing modules will receive the MSB of the signal when they call rd_bytes(0).

E.g. wr_bytes(0) = published_signal_MSB;

Subscribed_Signal_MSB = rd_bytes(0);

";
CM_ SG_ 1601 EOL_DCU_Rx7 "Development signal to freeze development frame ID's.

The MSB of the signal must be written to the COM layer first (with an offset of zero in wr_bytes() ) and therefore transmitted on the bus first.
Similarly, subscribing modules will receive the MSB of the signal when they call rd_bytes(0).

E.g. wr_bytes(0) = published_signal_MSB;

Subscribed_Signal_MSB = rd_bytes(0);

";
CM_ SG_ 1603 EOL_DCU_Rx8 "Development signal to freeze development frame ID's.

The MSB of the signal must be written to the COM layer first (with an offset of zero in wr_bytes() ) and therefore transmitted on the bus first.
Similarly, subscribing modules will receive the MSB of the signal when they call rd_bytes(0).

E.g. wr_bytes(0) = published_signal_MSB;

Subscribed_Signal_MSB = rd_bytes(0);

";
CM_ SG_ 1538 EOL_DCU_Tx1 "Development signal to freeze development frameID:s

This signal may never be written to in a vehicle running in normal operation! 
It is forbidden to activate the frame carrying this signal in a production vehicle running in normal operation! 
The supplier of the node publishing this signal is held liable for any problems or errors in the vehicle which are caused by this signal and the frame it is contained in!

The MSB of the signal must be written to the COM layer first (with an offset of zero in wr_bytes() ) and therefore transmitted on the bus first.
Similarly, subscribing modules will receive the MSB of the signal when they call rd_bytes(0).

E.g. wr_bytes(0) = published_signal_MSB;

Subscribed_Signal_MSB = rd_bytes(0);
";
CM_ SG_ 1540 EOL_DCU_Tx2 "Development signal to freeze development frameID:s

This signal may never be written to in a vehicle running in normal operation! 
It is forbidden to activate the frame carrying this signal in a production vehicle running in normal operation! 
The supplier of the node publishing this signal is held liable for any problems or errors in the vehicle which are caused by this signal and the frame it is contained in!

The MSB of the signal must be written to the COM layer first (with an offset of zero in wr_bytes() ) and therefore transmitted on the bus first.
Similarly, subscribing modules will receive the MSB of the signal when they call rd_bytes(0).

E.g. wr_bytes(0) = published_signal_MSB;

Subscribed_Signal_MSB = rd_bytes(0);
";
CM_ SG_ 1542 EOL_DCU_Tx3 "Development signal to freeze development frame ID's.

The MSB of the signal must be written to the COM layer first (with an offset of zero in wr_bytes() ) and therefore transmitted on the bus first.
Similarly, subscribing modules will receive the MSB of the signal when they call rd_bytes(0).

E.g. wr_bytes(0) = published_signal_MSB;

Subscribed_Signal_MSB = rd_bytes(0);
";
CM_ SG_ 1544 EOL_DCU_Tx4 "Development signal to freeze development frame ID's.

The MSB of the signal must be written to the COM layer first (with an offset of zero in wr_bytes() ) and therefore transmitted on the bus first.
Similarly, subscribing modules will receive the MSB of the signal when they call rd_bytes(0).

E.g. wr_bytes(0) = published_signal_MSB;

Subscribed_Signal_MSB = rd_bytes(0);
";
CM_ SG_ 1571 EOL_DCU_Tx5 "Development signal to freeze development frameID:s

This signal may never be written to in a vehicle running in normal operation! 
It is forbidden to activate the frame carrying this signal in a production vehicle running in normal operation! 
The supplier of the node publishing this signal is held liable for any problems or errors in the vehicle which are caused by this signal and the frame it is contained in!

The MSB of the signal must be written to the COM layer first (with an offset of zero in wr_bytes() ) and therefore transmitted on the bus first.
Similarly, subscribing modules will receive the MSB of the signal when they call rd_bytes(0).

E.g. wr_bytes(0) = published_signal_MSB;

Subscribed_Signal_MSB = rd_bytes(0);
";
CM_ SG_ 1573 EOL_DCU_Tx6 "Development signal to freeze development frameID:s

This signal may never be written to in a vehicle running in normal operation! 
It is forbidden to activate the frame carrying this signal in a production vehicle running in normal operation! 
The supplier of the node publishing this signal is held liable for any problems or errors in the vehicle which are caused by this signal and the frame it is contained in!

The MSB of the signal must be written to the COM layer first (with an offset of zero in wr_bytes() ) and therefore transmitted on the bus first.
Similarly, subscribing modules will receive the MSB of the signal when they call rd_bytes(0).

E.g. wr_bytes(0) = published_signal_MSB;

Subscribed_Signal_MSB = rd_bytes(0);
";
CM_ SG_ 1600 EOL_DCU_Tx7 "Development signal to freeze development frameID:s

This signal may never be written to in a vehicle running in normal operation! 
It is forbidden to activate the frame carrying this signal in a production vehicle running in normal operation! 
The supplier of the node publishing this signal is held liable for any problems or errors in the vehicle which are caused by this signal and the frame it is contained in!

The MSB of the signal must be written to the COM layer first (with an offset of zero in wr_bytes() ) and therefore transmitted on the bus first.
Similarly, subscribing modules will receive the MSB of the signal when they call rd_bytes(0).

E.g. wr_bytes(0) = published_signal_MSB;

Subscribed_Signal_MSB = rd_bytes(0);
";
CM_ SG_ 1602 EOL_DCU_Tx8 "Development signal to freeze development frameID:s

This signal may never be written to in a vehicle running in normal operation! 
It is forbidden to activate the frame carrying this signal in a production vehicle running in normal operation! 
The supplier of the node publishing this signal is held liable for any problems or errors in the vehicle which are caused by this signal and the frame it is contained in!

The MSB of the signal must be written to the COM layer first (with an offset of zero in wr_bytes() ) and therefore transmitted on the bus first.
Similarly, subscribing modules will receive the MSB of the signal when they call rd_bytes(0).

E.g. wr_bytes(0) = published_signal_MSB;

Subscribed_Signal_MSB = rd_bytes(0);
";
CM_ SG_ 128 ESCLDataControl "ESCL Communication.

Byte 1 Definition > 01=LockRequest, 03=Response, 04=Request final status

If Byte 1 = 0x01,

Byte 2 Definition > 0x01 = Unlock, 0x02 = Lock
Byte 3-8 > empty

If Byte 1 = 0x03

Bytes 2 - 5 Definition > Challenge Response
Bytes 6 - 8 Definition > empty 


If Byte 1 = 0x04

Byte 2 = 0x01
Bytes 3-8 = Empty
The MSB of the signal must be written to the COM layer first (with an offset of zero in wr_bytes() ) and therefore transmitted on the bus first.
Similarly, subscribing modules will receive the MSB of the signal when they call rd_bytes(0).

E.g. wr_bytes(0) = published_signal_MSB;

Subscribed_Signal_MSB = rd_bytes(0);

";
CM_ SG_ 130 ESCLDataTargetV2 "This is an updated version of the ESCLDataTarget message. The modifications will be indicated on the relevant lines below:

Communication with the BCM. 

Byte 1 Definition > 0x00=SystemStatus, 0x02=Challenge

If Byte 1 = ¿System status¿ (0x00) then:

Byte 2 (ESCL locking Status) Definition:

0x55 = ESCL Unlocked (*/modified from originalESCLDataTarget)
0xAA = ESCL Locked (*/modified from originalESCLDataTarget)
0xFF = ESCL Invalid position (*/modified from originalESCLDataTarget)

Byte 3 (ESCL Unit Status) Definition:

0x55 = Unit Ok (*/modified from originalESCLDataTarget)
0xAA = Unit in fault state (*/modified from originalESCLDataTarget)
0x03 = Initial lock status mismatch
0x04 = Error detected on initialisation
0x05 = RAM error check failed
0x06 = Motor timed out
0x07 = Awating VIP Frame
0x80 = Inhibited ¿ Not in programmed
0x81  = cheallenge response error
0x82 = Unauthorised Lock request
0x83 = Inhibited ¿ Not authorised 
0xC3 = lock/unlock in progress (*/modified from origin";
CM_ SG_ 1360 NMmessageFTCM "Network Management Signal. This signal contains Network Management Data. This data includes the DA (Destination Address), CF (Control Field) and up to 6 data bytes of user defined data (currently not used by Jaguar). The signal name is made up of the following components:

NM represents 'Network Management'
5 represents the 0x5 part of the transporting CANID.	
02 represents the SA part of the transporting CANID.
LS indicates that this Signal is for LS-CAN Network Management.

The MSB of the signal must be written to the COM layer first (with an offset of zero in wr_bytes() ) and therefore transmitted on the bus first.
Similarly, subscribing modules will receive the MSB of the signal when they call rd_bytes(0).

E.g. wr_bytes(0) = published_signal_MSB;

Subscribed_Signal_MSB = rd_bytes(0);

CAN ID:
X150/X250 - 0x502
GMRDB - 0x550

";
CM_ SG_ 366 FTCM_Command "Commands to control internal motor of FTCMB ECU. Used to activate open and close movement, stop movement and activate initialization/deinitialization

Logical Value	0	 	 	Stop
Logical Value	1	 	 	DirectPosition
Logical Value	2	 	 	DirectDriveOpen
Logical Value	3	 	 	DirectDriveClose
Logical Value	4	 	 	SetNormalisation
Logical Value	5	 	 	DiscardNormalisation
Logical Value	6	 	 	ResetErrorFlags
Logical Value	7	 	 	Reserved
";
CM_ SG_ 366 FTCM_Command_Count "Incremented to signalize changed command. Used to trigger action if same command is sent twice

Physical Range	0 - 3	1	0	counter (inc counter- Trigger action if same cmd is sent twice)";
CM_ SG_ 366 FTCM_CtrlSignalState "FTCM_ControlSignalClose_State
Control signal close Roof

Logical Value	0	 	 	Inactive
Logical Value	1	 	 	Active
Logical Value	2	 	 	Error
";
CM_ SG_ 366 FTCM_Latch_CmdDiag "FTCM_Latch_Command_Diagnosis
diagData.dlDiagCommand

Logical Value	0	 	 	Stop
Logical Value	1	 	 	Open
Logical Value	2	 	 	Close
";
CM_ SG_ 366 FTCM_Latch_Command "Command to control FTCMB external latch drive

Logical Value	0	 	 	Stop
Logical Value	1	 	 	Open
Logical Value	2	 	 	Close
";
CM_ SG_ 366 FTCM_OperationModeActive "Identifies that the master has no operation requests for the slave

Logical Value	0	 	 	Inactive
Logical Value	1	 	 	Active
";
CM_ SG_ 366 FTCM_Position "Actual position of FTCM internal drive";
CM_ SG_ 366 FTCM_Target "Commands to define target position

Value	0	 	 	CloseTarget
Value	1	 	 	ClosePosition
Value	2	 	 	OpenPosition
Value	3	 	 	OpenTarget
Value	4 - 7	 	 	Reserved
";
CM_ SG_ 366 FTCMCmdExt "FTCM_Command_Extension
Extended commands to control internal motor of FTCMB ECU. Control of PWM, and pinch forces, activation of teaching and profile adaption

Logical Value	0	 	 	Normal
Logical Value	1	 	 	NoPwmNoAp
Logical Value	2	 	 	Teach
Logical Value	3	 	 	NoAdapt
Logical Value	4	 	 	ForceIncrease1
Logical Value	5	 	 	ForceIncrease2
Logical Value	6	 	 	ForceIncrease3
Logical Value	7	 	 	Reserved
";
CM_ SG_ 366 FTCMHoldModeActive "Command to activate active brake mode for FTCMB internal motor

Logical Value	0	 	 	Inactive
Logical Value	1	 	 	Active";
CM_ SG_ 366 FTCMLatchCmdCount "Incremented to signalize changed command. Used to trigger action if same command is sent twice

Physical Range	0 - 3	1	0	counter (inc counter- Trigger action if same cmd is sent twice)";
CM_ SG_ 366 RoofPositionStatus "Indicates the current hood status.";
CM_ SG_ 366 RoofPumpOperating "CAN message to denote hood hydraulic pump operation";
CM_ SG_ 366 RoofWarningMessage "Roof Warning Message.";
CM_ SG_ 366 WindowOperationRoofRequest "Window Operation Roof Request.";
CM_ SG_ 1363 NMmessageFTCMB "Network Management Signal. This signal contains Network Management Data. This data includes the DA (Destination Address), CF (Control Field) and up to 6 data bytes of user defined data (currently not used by Jaguar). The signal name is made up of the following components:

NM represents 'Network Management'
5 represents the 0x5 part of the transporting CANID.
02 represents the SA part of the transporting CANID.
LS indicates that this Signal is for LS-CAN Network Management.

The MSB of the signal must be written to the COM layer first (with an offset of zero in wr_bytes() ) and therefore transmitted on the bus first.
Similarly, subscribing modules will receive the MSB of the signal when they call rd_bytes(0).

E.g. wr_bytes(0) = published_signal_MSB;

Subscribed_Signal_MSB = rd_bytes(0);

CAN ID:
X150/X250 -
GMRDB - 0x553
";
CM_ SG_ 367 FTCMB_ClosedRange_Active "Set to active if drive is within a specific range near to the closed position (position may be changed by parameter)
";
CM_ SG_ 367 FTCMB_CtrlSignal_State "Status of switch for roof opening operation
";
CM_ SG_ 367 FTCMB_Error_Flags "Error flags of FTCMB internal drive to define important drive error states";
CM_ SG_ 367 FTCMB_Finished "Extended state of FTCMB internal dirve";
CM_ SG_ 367 FTCMB_Finished_Counter "Incremented to signalize changed command. Used to trigger action if same command is sent twice
";
CM_ SG_ 367 FTCMB_Latch_Error_Flags "Error flags of FTCMB external latch dirve
";
CM_ SG_ 367 FTCMB_Latch_State "State of FTCMB external latch dirve";
CM_ SG_ 367 FTCMB_Latch_State_Count "Incremented to signalize changed state. Used to trigger action if same state is sent twice
";
CM_ SG_ 367 FTCMB_OpenRange_Active "Set to active if drive is within a specific range near to the open position (position may be changed by parameter)
";
CM_ SG_ 367 FTCMB_Position "Actual position of FTCMB internal drive
";
CM_ SG_ 367 FTCMB_SD_DL_C_State "Status of sensor: SensorDrive_DownLock_Closed";
CM_ SG_ 367 FTCMB_SD_DL_O_State "Status of sensor: SensorDrive_DownLock_Open";
CM_ SG_ 367 FTCMB_SL_DL_E_State "Status of sensor: SensorLatch_DownLock_Engaged
";
CM_ SG_ 367 FTCMB_SlaveState "Overall state of FTCMB showing if FTCMB is ready for roof operation";
CM_ SG_ 367 FTCMB_SP_FT_C_State "Status of sensor: SensorPosition_FoldableTop_Closed";
CM_ SG_ 367 FTCMB_State "State of FTCMB internal drive";
CM_ SG_ 367 FTCMB_State_Flags "State flags of FTCMB internal drive to define important drive states";
CM_ SG_ 583 FuelPumpEnableDataControl "Fuel Pump Enable
Byte 1:
00 = Idle, 
01 = Key Status, 
03 = Response, 
05 = Terminate

The MSB of the signal must be written to the COM layer first (with an offset of zero in wr_bytes() ) and therefore transmitted on the bus first.
Similarly, subscribing modules will receive the MSB of the signal when they call rd_bytes(0).

E.g. wr_bytes(0) = published_signal_MSB;

Subscribed_Signal_MSB = rd_bytes(0);
";
CM_ SG_ 277 AutoTRStatus "Indicates that the Auto Terrain Response program is on or off.

0 = Auto TR Off
1 = Auto TR On";
CM_ SG_ 277 CanclAutoTrProgReq "Advises Auto Terrain Response that the requested Terrain Program/Mode cannot be provided ";
CM_ SG_ 277 ElPowerStatus "Multi-stage engine-off battery State of Charge related warning mechanism
";
CM_ SG_ 277 PSDBActvDiagState "PSDB active diagnostics state.";
CM_ SG_ 277 RtnPrevProg "Advises Auto Terrain Response that a return to the previous program occurred due to a Program change timeout.";
CM_ SG_ 277 TerrainModeReqExt "The 'Drive mode' or 'Terrain mode' selected by the driver. (Jaguar Drive Control and Land Rover Terrain Response)";
CM_ SG_ 277 TerrainModeReqStatus "signal for the activation of the passive electrical features included in ECO Mode for future car lines.Signal will allow handshake of TR prior to entering mode removing potential entry and exit faults.";
CM_ SG_ 277 TerrProgActv "Currently active Terrain Program/Mode";
CM_ SG_ 299 AdaptDriBeamEnableSta "New signal from HCMA to BCM / IGM to confirm when adaptive driving beam is enabled in cluster menu";
CM_ SG_ 299 AdaptDriBeamMsgReq "New signal from BCM to IPC to request for cluster messages and graphics";
CM_ SG_ 299 ADBOperationalStatus "This signal indicate the operational status for Auto High Beam Feature
";
CM_ SG_ 299 AdptDriBeamTellTaleReq "New signal from HCM/A to IPC to request Auto green tell when Adaptive driving beam is enabled and active. ";
CM_ SG_ 299 AFSSystemFailure "New signal from HCM/A to IPC to request AFS system warning tell tale and text message.";
CM_ SG_ 299 AHBOperationalStatus "This signal indicate the operational status for Auto High Beam Feature
";
CM_ SG_ 299 AutoHighBeamEnableSta "Indicates whether the Auto High Beam Control system is currently enabled or disabled by the user.";
CM_ SG_ 299 AutoHighBeamMsgReq "Status of the Auto High Beam Control system used by the Instrument Pack to display system messages to the user.";
CM_ SG_ 299 AutoHighBeamTTReq "Signal to activate the Auto High Beam Control tell-tale symbol on the Instrument Pack";
CM_ SG_ 299 HCMHighBeamTellTaleReg "New signal from HCM/A to IPC to indicate when Adaptive driving beam is operational.";
CM_ SG_ 299 SupMainBeamEnableSta "New signal from BCM to IPC to confirm status of supplementary main beam.";
CM_ SG_ 426 LHHighBeamError "Outputs error value when the LH High Beam is not illuminating when requested or illuminating when not requested";
CM_ SG_ 426 LHHighBeamStatus "Indicates LH High Beam Status";
CM_ SG_ 426 LHLowBeamError "Outputs error value when the LH Low Beam is not illuminating when requested or illuminating when not requested";
CM_ SG_ 426 LHLowBeamStatus "Indicates LH Low Beam Status";
CM_ SG_ 426 RHHighBeamError "Outputs error value when the RH High Beam is not illuminating when requested or illuminating when not requested";
CM_ SG_ 426 RHHighBeamStatus "Indicates RH High Beam Status";
CM_ SG_ 426 RHLowBeamError "Outputs error value when the RH Low Beam is not illuminating when requested or illuminating when not requested";
CM_ SG_ 426 RHLowBeamStatus "Indicates RH Low Beam Status";
CM_ SG_ 701 AmbientLightValueHLDF "This signal takes a raw ambient light data from the ambient light sensor located at HLDF and publishes it on the CANBus via the MOSTBus.";
CM_ SG_ 701 DriveAwayLockingSw "On/Off toggle on the Instrument Pack to turn drive away locking on and off.";
CM_ SG_ 701 EasyEntryEnDisReqRear "Signal from FCDIM to enable or disable the rear seat easy entry function";
CM_ SG_ 701 HeadlampExitDelayReq "Headlamp mode selected via the infotainment display, to request Headlamp exit delay.";
CM_ SG_ 701 ISCMFrontSeatMovement "Touch Screen Signal to inform DSM & PSM to enable/disable front seat movement during a fold all request of seats.";
CM_ SG_ 701 LockChirpsReq "On/Off toggle on the Instrument Pack to turn Lock Chirps on and off.";
CM_ SG_ 701 RainSenseReq "Description of signal.  This signal refers to the intermittent/auto wiper operation. If set RainSenseReq = 1 will result in the front wiper operating in the auto mode if selected via the column stalk switch. If RainSenseReq = 0 the wipers shall operate in the intermittent mode if selected via the column stalk switch

update bit required (RainSenseReq_UB)";
CM_ SG_ 701 SeatMoveSelectFrReq "Signal from FCDIM to enable drivers seat switchpack/memory buttons to control either front passenger or rear passenger seats depending on seat selected";
CM_ SG_ 701 SensorOverrideSwitch "Turns the intrusion sensors and tilt sensor on/off.";
CM_ SG_ 701 SkiHatchReq "Signal to inform Rear Seat Modules of a Ski Hatch Open request";
CM_ SG_ 701 TSPassSeatMemLoadReq "Touch Screen Signal to inform PSM of a Memory Recall";
CM_ SG_ 701 TSPassSeatMemStorReq "Touch Screen Signal to inform PSM of a Memory Store";
CM_ SG_ 701 TSPassSeatMoveReq "Touch Screen Signal to inform PSM of a passenger seat move request";
CM_ SG_ 701 TSRLSeatMemLoadReq "Touch Screen Signal to inform RLSM of a Memory Recall";
CM_ SG_ 701 TSRLSeatMemStorReq "Touch Screen Signal to inform RLSM of a Memory Store";
CM_ SG_ 701 TSRRSeatMemLoadReq "Touch Screen Signal to inform RRSM of a Memory Recall";
CM_ SG_ 701 TSRRSeatMemStorReq "Touch Screen Signal to inform RRSM of a Memory Store";
CM_ SG_ 702 TS2ndRowCntrMoveReq "Touch Screen Signal to inform RLSM of rear middle 2nd Row Power Arm Rest Movement Request";
CM_ SG_ 702 TS2ndRowLeftMoveReq "Touch Screen Signal to inform DSM & PSM of Rear Left 2nd Row Seat Fold / Unfold Request";
CM_ SG_ 702 TS2ndRowRightMoveReq "Touch Screen Signal to inform DSM & PSM of Rear Right 2nd Row Seat Fold / Unfold Request";
CM_ SG_ 702 TS3rdRowLeftMoveReq "Touch Screen Signal to inform DSM & PSM of Rear Left 3rd Row Seat Fold / Unfold Request";
CM_ SG_ 702 TS3rdRowRightMoveReq "Touch Screen Signal to inform DSM & PSM of Rear Right 3rd Row Seat Fold / Unfold Request
";
CM_ SG_ 702 TSHRestMove2ndRLReq "Touch Screen Signal to inform DSM & PSM for a Rear Left 2nd Row Headrest fold request";
CM_ SG_ 702 TSHRestMove2ndRMReq "Touch Screen Signal to inform DSM & PSM for a Rear Middle 2nd Row Headrest fold request";
CM_ SG_ 702 TSHRestMove2ndRRReq "Touch Screen Signal to inform DSM & PSM for a Rear Right 2nd Row Headrest fold request";
CM_ SG_ 702 TSHRestMove3rdRLReq "Touch Screen Signal to inform DSM & PSM for a Rear Left 3rd Row Headrest fold request
";
CM_ SG_ 702 TSHRestMove3rdRRReq "Touch Screen Signal to inform DSM & PSM for a Rear Right 3rd Row Headrest fold request";
CM_ SG_ 693 DriverSeatMassageReq "This signal requests the driver's seat massage function to be ON or OFF.";
CM_ SG_ 693 DrvSeatMasgIntReq "Signal recieved from HLDF  to command the various massage intensities on the front driver seat.";
CM_ SG_ 693 DrvSeatMasgLocReq "Driver Seat: User Requested Massage Location";
CM_ SG_ 693 DrvSeatMasgProgReq "Driver Seat: User Requested Massage Programme";
CM_ SG_ 693 DrvSeatMassageModeReq "Driver seat massage mode request signal";
CM_ SG_ 693 PassSeatMasgIntReq "Signal recieved from HLDF  to command the various massage intensities on the front passenger seat.";
CM_ SG_ 693 PassSeatMasgLocReq "Passenger Seat: User Requested Massage Location
";
CM_ SG_ 693 PassSeatMasgProgReq "Passenger Seat: User Requested Massage Programme";
CM_ SG_ 693 PassSeatMassageModeReq "Passenger seat massage mode request signal";
CM_ SG_ 693 PassSeatMassageReq "This signal requests the passenger's seat massage function to be ON or OFF.";
CM_ SG_ 693 RLSeatMasgIntReqFr "Rear Left Seat: User Requested Massage Intensity";
CM_ SG_ 693 RLSeatMasgLocReqFr "Rear Left Seat: User Requested Massage Location";
CM_ SG_ 693 RLSeatMasgModeReqFr "Signal transmitted by FCDIM to rear SCMH to select massage mode";
CM_ SG_ 693 RLSeatMasgProgReqFr "Rear Left Seat: User Requested Massage Programme";
CM_ SG_ 693 RLSeatMasgReqFr "Signal transmitted by FCDIM to rear SCMG to select seat massage on or off";
CM_ SG_ 693 RRSeatMasgIntReqFr "Rear Right Seat: User Requested Massage Intensity";
CM_ SG_ 693 RRSeatMasgLocReqFr "Rear Right Seat: User Requested Massage Location";
CM_ SG_ 693 RRSeatMasgModeReqFr "Signal transmitted by FCDIM to rear SCMG to select massage mode";
CM_ SG_ 693 RRSeatMasgProgReqFr "Rear Right Seat: User Requested Massage Programme";
CM_ SG_ 693 RRSeatMasgReqFr "Signal transmitted by FCDIM to rear SCMH to select seat massage on or off";
BA_DEF_  "Baudrate" FLOAT 1000 1000000;
BA_DEF_ BO_  "GenMsgSendType" ENUM  "cyclic","spontaneous","cyclicIfActive","spontaneousWithDelay","cyclicAndSpontaneous","cyclicAndSpontaneousWithDelay";
BA_DEF_ BO_  "GenMsgCycleTime" FLOAT 0 300000;
BA_DEF_ BO_  "GenMsgStartDelayTime" FLOAT 0 300000;
BA_DEF_ BO_  "GenMsgDelayTime" FLOAT 0 300000;
BA_DEF_ SG_  "GenSigSendType" ENUM  "Cyclic","OnWrite","OnWriteWithRepetition","OnChange","OnChangeWithRepetition","IfActive","IfActiveWithRepetition","NoSigSendType";
BA_DEF_ SG_  "GenSigStartValue" FLOAT -1.79769313486232E+308 1.84467440737096E+019;
BA_DEF_ BU_  "NmAsrNodeIdentifier" INT 1 60;
BA_DEF_  "DBName" STRING ;
BA_DEF_  "BusType" STRING ;
BA_DEF_  "ProtocolType" STRING ;
BA_DEF_DEF_  "Baudrate" 1000;
BA_DEF_DEF_  "GenMsgSendType" "";
BA_DEF_DEF_  "GenMsgCycleTime" 0;
BA_DEF_DEF_  "GenMsgStartDelayTime" 0;
BA_DEF_DEF_  "GenMsgDelayTime" 0;
BA_DEF_DEF_  "GenSigSendType" "Cyclic";
BA_DEF_DEF_  "GenSigStartValue" 0;
BA_DEF_DEF_  "NmAsrNodeIdentifier" 1;
BA_DEF_DEF_  "DBName" "";
BA_DEF_DEF_  "BusType" "";
BA_DEF_DEF_  "ProtocolType" "";
BA_ "Baudrate" 500000;
BA_ "ProtocolType" "CAN";
BA_ "BusType" "CAN";
BA_ "DBName" "BO_HSCAN";
BA_ "NmAsrNodeIdentifier" BU_ DDM 132;
BA_ "NmAsrNodeIdentifier" BU_ DRDM 134;
BA_ "NmAsrNodeIdentifier" BU_ GWM 158;
BA_ "NmAsrNodeIdentifier" BU_ PDM 133;
BA_ "NmAsrNodeIdentifier" BU_ PRDM 135;
BA_ "GenMsgDelayTime" BO_ 66 20;
BA_ "GenMsgSendType" BO_ 66 1;
BA_ "GenMsgDelayTime" BO_ 17 20;
BA_ "GenMsgSendType" BO_ 17 1;
BA_ "GenMsgDelayTime" BO_ 1281 95;
BA_ "GenMsgSendType" BO_ 1281 1;
BA_ "GenMsgCycleTime" BO_ 418 80;
BA_ "GenMsgSendType" BO_ 418 0;
BA_ "GenMsgCycleTime" BO_ 763 500;
BA_ "GenMsgSendType" BO_ 763 0;
BA_ "GenMsgCycleTime" BO_ 255 40;
BA_ "GenMsgSendType" BO_ 255 0;
BA_ "GenMsgCycleTime" BO_ 673 160;
BA_ "GenMsgSendType" BO_ 673 0;
BA_ "GenMsgCycleTime" BO_ 675 160;
BA_ "GenMsgSendType" BO_ 675 0;
BA_ "GenMsgCycleTime" BO_ 676 180;
BA_ "GenMsgSendType" BO_ 676 0;
BA_ "GenMsgCycleTime" BO_ 677 160;
BA_ "GenMsgSendType" BO_ 677 0;
BA_ "GenMsgCycleTime" BO_ 678 160;
BA_ "GenMsgSendType" BO_ 678 0;
BA_ "GenMsgCycleTime" BO_ 679 160;
BA_ "GenMsgSendType" BO_ 679 0;
BA_ "GenMsgCycleTime" BO_ 681 160;
BA_ "GenMsgSendType" BO_ 681 0;
BA_ "GenMsgCycleTime" BO_ 938 600;
BA_ "GenMsgSendType" BO_ 938 0;
BA_ "GenMsgCycleTime" BO_ 423 80;
BA_ "GenMsgSendType" BO_ 423 0;
BA_ "GenMsgCycleTime" BO_ 420 80;
BA_ "GenMsgSendType" BO_ 420 0;
BA_ "GenMsgCycleTime" BO_ 421 80;
BA_ "GenMsgSendType" BO_ 421 0;
BA_ "GenMsgCycleTime" BO_ 422 100;
BA_ "GenMsgSendType" BO_ 422 0;
BA_ "GenMsgCycleTime" BO_ 935 600;
BA_ "GenMsgSendType" BO_ 935 0;
BA_ "GenMsgCycleTime" BO_ 424 80;
BA_ "GenMsgSendType" BO_ 424 0;
BA_ "GenMsgCycleTime" BO_ 425 80;
BA_ "GenMsgSendType" BO_ 425 0;
BA_ "GenMsgDelayTime" BO_ 225 5;
BA_ "GenMsgSendType" BO_ 225 1;
BA_ "GenMsgDelayTime" BO_ 226 100;
BA_ "GenMsgSendType" BO_ 226 1;
BA_ "GenMsgDelayTime" BO_ 227 100;
BA_ "GenMsgSendType" BO_ 227 1;
BA_ "GenMsgDelayTime" BO_ 502 80;
BA_ "GenMsgSendType" BO_ 502 1;
BA_ "GenMsgDelayTime" BO_ 230 40;
BA_ "GenMsgSendType" BO_ 230 1;
BA_ "GenMsgCycleTime" BO_ 794 400;
BA_ "GenMsgSendType" BO_ 794 0;
BA_ "GenMsgDelayTime" BO_ 1412 500;
BA_ "GenMsgSendType" BO_ 1412 1;
BA_ "GenMsgDelayTime" BO_ 1414 500;
BA_ "GenMsgSendType" BO_ 1414 1;
BA_ "GenMsgDelayTime" BO_ 1438 500;
BA_ "GenMsgSendType" BO_ 1438 1;
BA_ "GenMsgDelayTime" BO_ 1310 500;
BA_ "GenMsgSendType" BO_ 1310 1;
BA_ "GenMsgDelayTime" BO_ 1413 500;
BA_ "GenMsgSendType" BO_ 1413 1;
BA_ "GenMsgDelayTime" BO_ 1407 500;
BA_ "GenMsgSendType" BO_ 1407 1;
BA_ "GenMsgDelayTime" BO_ 1415 500;
BA_ "GenMsgSendType" BO_ 1415 1;
BA_ "GenMsgDelayTime" BO_ 270 40;
BA_ "GenMsgSendType" BO_ 270 1;
BA_ "GenMsgDelayTime" BO_ 207 100;
BA_ "GenMsgSendType" BO_ 207 1;
BA_ "GenMsgCycleTime" BO_ 1010 1500;
BA_ "GenMsgSendType" BO_ 1010 0;
BA_ "GenMsgCycleTime" BO_ 498 80;
BA_ "GenMsgSendType" BO_ 498 0;
BA_ "GenMsgDelayTime" BO_ 242 60;
BA_ "GenMsgSendType" BO_ 242 1;
BA_ "GenMsgDelayTime" BO_ 1615 100;
BA_ "GenMsgSendType" BO_ 1615 1;
BA_ "GenMsgDelayTime" BO_ 1643 100;
BA_ "GenMsgSendType" BO_ 1643 1;
BA_ "GenMsgCycleTime" BO_ 476 100;
BA_ "GenMsgSendType" BO_ 476 0;
BA_ "GenMsgCycleTime" BO_ 452 60;
BA_ "GenMsgSendType" BO_ 452 0;
BA_ "GenMsgDelayTime" BO_ 551 80;
BA_ "GenMsgSendType" BO_ 551 1;
BA_ "GenMsgDelayTime" BO_ 1291 100;
BA_ "GenMsgSendType" BO_ 1291 1;
BA_ "GenMsgCycleTime" BO_ 400 100;
BA_ "GenMsgSendType" BO_ 400 0;
BA_ "GenMsgCycleTime" BO_ 994 500;
BA_ "GenMsgSendType" BO_ 994 0;
BA_ "GenMsgCycleTime" BO_ 996 500;
BA_ "GenMsgSendType" BO_ 996 0;
BA_ "GenMsgCycleTime" BO_ 998 500;
BA_ "GenMsgSendType" BO_ 998 0;
BA_ "GenMsgCycleTime" BO_ 1000 500;
BA_ "GenMsgSendType" BO_ 1000 0;
BA_ "GenMsgCycleTime" BO_ 396 80;
BA_ "GenMsgSendType" BO_ 396 0;
BA_ "GenMsgCycleTime" BO_ 394 80;
BA_ "GenMsgSendType" BO_ 394 0;
BA_ "GenMsgDelayTime" BO_ 1539 100;
BA_ "GenMsgSendType" BO_ 1539 1;
BA_ "GenMsgDelayTime" BO_ 1541 100;
BA_ "GenMsgSendType" BO_ 1541 1;
BA_ "GenMsgDelayTime" BO_ 1543 100;
BA_ "GenMsgSendType" BO_ 1543 1;
BA_ "GenMsgDelayTime" BO_ 1545 100;
BA_ "GenMsgSendType" BO_ 1545 1;
BA_ "GenMsgDelayTime" BO_ 1572 100;
BA_ "GenMsgSendType" BO_ 1572 1;
BA_ "GenMsgDelayTime" BO_ 1574 100;
BA_ "GenMsgSendType" BO_ 1574 1;
BA_ "GenMsgDelayTime" BO_ 1601 100;
BA_ "GenMsgSendType" BO_ 1601 1;
BA_ "GenMsgDelayTime" BO_ 1603 100;
BA_ "GenMsgSendType" BO_ 1603 1;
BA_ "GenMsgDelayTime" BO_ 128 160;
BA_ "GenMsgSendType" BO_ 128 1;
BA_ "GenMsgDelayTime" BO_ 130 100;
BA_ "GenMsgSendType" BO_ 130 1;
BA_ "GenMsgCycleTime" BO_ 366 100;
BA_ "GenMsgSendType" BO_ 366 0;
BA_ "GenMsgCycleTime" BO_ 367 100;
BA_ "GenMsgSendType" BO_ 367 0;
BA_ "GenMsgDelayTime" BO_ 583 120;
BA_ "GenMsgSendType" BO_ 583 1;
BA_ "GenMsgCycleTime" BO_ 277 100;
BA_ "GenMsgSendType" BO_ 277 0;
BA_ "GenMsgDelayTime" BO_ 299 60;
BA_ "GenMsgSendType" BO_ 299 1;
BA_ "GenMsgCycleTime" BO_ 426 250;
BA_ "GenMsgSendType" BO_ 426 0;
BA_ "GenMsgDelayTime" BO_ 701 250;
BA_ "GenMsgSendType" BO_ 701 1;
BA_ "GenMsgDelayTime" BO_ 702 200;
BA_ "GenMsgSendType" BO_ 702 1;
BA_ "GenMsgDelayTime" BO_ 693 200;
BA_ "GenMsgSendType" BO_ 693 1;
BA_ "GenSigStartValue" SG_ 66 HillDescentMode 1;
BA_ "GenSigStartValue" SG_ 66 YawRate 500;
BA_ "GenSigStartValue" SG_ 17 ABSPwrTrnTorqReq 1;
BA_ "GenSigStartValue" SG_ 17 BrakePressureQF 1;
BA_ "GenSigStartValue" SG_ 17 VehicleSpeedQF 1;
BA_ "GenSigSendType" SG_ 1281 NMmessageBCMLS 1;
BA_ "GenSigStartValue" SG_ 255 DirectionIndicationSwitch 6;
BA_ "GenSigStartValue" SG_ 255 PowerModeQF 1;
BA_ "GenSigStartValue" SG_ 675 RearFoglightIndication 3;
BA_ "GenSigStartValue" SG_ 678 IgnoreLatchOnUnlock 1;
BA_ "GenSigStartValue" SG_ 678 POTailgateLatchStatus 1;
BA_ "GenSigStartValue" SG_ 678 POTLatchStatLwrLHS 1;
BA_ "GenSigStartValue" SG_ 678 POTLatchStatLwrRHS 1;
BA_ "GenSigStartValue" SG_ 420 FLDirectionIndicatorBulbFail 3;
BA_ "GenSigStartValue" SG_ 420 FRDirectionIndicatorBulbFail 3;
BA_ "GenSigStartValue" SG_ 420 LeftStopLampBulbFailure 3;
BA_ "GenSigStartValue" SG_ 420 MainBeamStatus 3;
BA_ "GenSigStartValue" SG_ 420 RightStopLampBulbFailure 3;
BA_ "GenSigStartValue" SG_ 420 RLDirectionIndicatorBulbFail 3;
BA_ "GenSigStartValue" SG_ 420 RLPositionLampBulbFailure 3;
BA_ "GenSigStartValue" SG_ 420 RRDirectionIndicatorBulbFail 3;
BA_ "GenSigStartValue" SG_ 420 RRPositionLampBulbFailure 3;
BA_ "GenSigStartValue" SG_ 420 SidelightStatus 3;
BA_ "GenSigStartValue" SG_ 422 DoorStatus 63;
BA_ "GenSigStartValue" SG_ 422 FrontFogLightIndication 3;
BA_ "GenSigStartValue" SG_ 422 HeadlampExitDelayStatus 5;
BA_ "GenSigStartValue" SG_ 422 NightStatus 1;
BA_ "GenSigStartValue" SG_ 935 BrakeFluidLevelWarning 1;
BA_ "GenSigStartValue" SG_ 424 LoadSettings 4096;
BA_ "GenSigStartValue" SG_ 425 ColumnAdjustSwitchStatus 3;
BA_ "GenSigStartValue" SG_ 425 OilPressureSwitchRaw 1;
BA_ "GenSigSendType" SG_ 225 CentralLockLastCmdOrig2 1;
BA_ "GenSigSendType" SG_ 225 CentralLockStatus2 1;
BA_ "GenSigSendType" SG_ 225 CLock_RC2 1;
BA_ "GenSigSendType" SG_ 225 DriverDoorLockCmd 1;
BA_ "GenSigSendType" SG_ 225 FrontPassDoorLockCmd 1;
BA_ "GenSigSendType" SG_ 225 RearDriverDoorLockCmd 1;
BA_ "GenSigSendType" SG_ 225 RearPassDoorLockCmd 1;
BA_ "GenSigSendType" SG_ 226 ImmoAuthPKeyMainReq 1;
BA_ "GenSigSendType" SG_ 227 CLockCmd_2 1;
BA_ "GenSigSendType" SG_ 227 ePEPSLockResult 1;
BA_ "GenSigSendType" SG_ 227 GlobalWindowReq 1;
BA_ "GenSigSendType" SG_ 227 LocationOfKeysRequest 1;
BA_ "GenSigSendType" SG_ 227 PKExteriorScanReq 1;
BA_ "GenSigSendType" SG_ 227 PKInteriorScanReq 1;
BA_ "GenSigSendType" SG_ 227 POTUpperAndLowerReq 1;
BA_ "GenSigSendType" SG_ 227 PowerTailgateReq 1;
BA_ "GenSigSendType" SG_ 227 PowerTailgateReqLwr 1;
BA_ "GenSigSendType" SG_ 227 PuddleLightActivation 1;
BA_ "GenSigSendType" SG_ 227 RFARequestAck 1;
BA_ "GenSigSendType" SG_ 227 RKELockResult 1;
BA_ "GenSigSendType" SG_ 502 CLock_RC 1;
BA_ "GenSigSendType" SG_ 230 AlarmModeMS 1;
BA_ "GenSigStartValue" SG_ 230 AlarmModeMS 3;
BA_ "GenSigSendType" SG_ 230 DirectionIndication 1;
BA_ "GenSigSendType" SG_ 230 DirectionIndicationINST 1;
BA_ "GenSigSendType" SG_ 230 ImmoFailureInd 1;
BA_ "GenSigSendType" SG_ 230 InteriorLightMode 1;
BA_ "GenSigSendType" SG_ 230 KeyWarningInd 1;
BA_ "GenSigSendType" SG_ 230 LDWSwitchReq 1;
BA_ "GenSigSendType" SG_ 230 LowBeamIndication 1;
BA_ "GenSigSendType" SG_ 230 TrailerDILeft 1;
BA_ "GenSigSendType" SG_ 230 TrailerDirectionInd 1;
BA_ "GenSigSendType" SG_ 230 TrailerDIRight 1;
BA_ "GenSigSendType" SG_ 230 TrailerStopLamp 1;
BA_ "GenSigSendType" SG_ 230 WakeShutDownEnableSta 1;
BA_ "GenSigStartValue" SG_ 794 BSBattSOC 75;
BA_ "GenSigStartValue" SG_ 794 BSBattVoltage 205;
BA_ "GenSigStartValue" SG_ 498 DDoorLatchStatus 2;
BA_ "GenSigStartValue" SG_ 498 DriverDoorSCAStatus 3;
BA_ "GenSigStartValue" SG_ 498 MirrorFoldStatus 7;
BA_ "GenSigSendType" SG_ 242 DDHandleStatus 1;
BA_ "GenSigSendType" SG_ 242 DDLockSwitchPress 1;
BA_ "GenSigSendType" SG_ 242 DDUnLockSwitchPress 1;
BA_ "GenSigSendType" SG_ 242 DipMirrorPosPassenger 1;
BA_ "GenSigSendType" SG_ 242 DriverWindowPosition 1;
BA_ "GenSigSendType" SG_ 242 PassMirrorCmd 1;
BA_ "GenSigSendType" SG_ 242 PassWindowCmd 1;
BA_ "GenSigSendType" SG_ 242 RearDriverWindowCmd 1;
BA_ "GenSigSendType" SG_ 242 RearPassWindowCmd 1;
BA_ "GenSigSendType" SG_ 242 RearWindowDisableCmd 1;
BA_ "GenSigSendType" SG_ 1614 DevID_RGTM_Tx1 1;
BA_ "GenSigSendType" SG_ 1642 DevID_RGTMB_Tx1 1;
BA_ "GenSigStartValue" SG_ 452 RearDrivDoorSCAStatus 3;
BA_ "GenSigSendType" SG_ 551 DRDChildLockStatus 1;
BA_ "GenSigStartValue" SG_ 551 DRDChildLockStatus 3;
BA_ "GenSigSendType" SG_ 551 DRDoorLatchStatus 1;
BA_ "GenSigStartValue" SG_ 551 DRDoorLatchStatus 2;
BA_ "GenSigSendType" SG_ 551 DRHandleStatus 1;
BA_ "GenSigSendType" SG_ 551 DriverRearWindowPos 1;
BA_ "GenSigSendType" SG_ 551 RDDLockSwitchPress 1;
BA_ "GenSigSendType" SG_ 551 RDDUnLockSwitchPress 1;
BA_ "GenSigSendType" SG_ 1291 NMmessageDSM 1;
BA_ "GenSigStartValue" SG_ 396 MemoryPosLoadReq 63;
BA_ "GenSigStartValue" SG_ 396 MemoryPosStoreReq 63;
BA_ "GenSigSendType" SG_ 1538 EOL_DCU_Tx1 1;
BA_ "GenSigSendType" SG_ 1540 EOL_DCU_Tx2 1;
BA_ "GenSigSendType" SG_ 1542 EOL_DCU_Tx3 1;
BA_ "GenSigSendType" SG_ 1544 EOL_DCU_Tx4 1;
BA_ "GenSigSendType" SG_ 1571 EOL_DCU_Tx5 1;
BA_ "GenSigSendType" SG_ 1573 EOL_DCU_Tx6 1;
BA_ "GenSigSendType" SG_ 1600 EOL_DCU_Tx7 1;
BA_ "GenSigSendType" SG_ 1602 EOL_DCU_Tx8 1;
BA_ "GenSigSendType" SG_ 128 ESCLDataControl 1;
BA_ "GenSigSendType" SG_ 130 ESCLDataTargetV2 1;
BA_ "GenSigSendType" SG_ 1360 NMmessageFTCM 1;
BA_ "GenSigStartValue" SG_ 366 FTCM_Position 20000;
BA_ "GenSigSendType" SG_ 1363 NMmessageFTCMB 1;
BA_ "GenSigStartValue" SG_ 367 FTCMB_Position 20000;
BA_ "GenSigStartValue" SG_ 367 FTCMB_State_Flags 7;
BA_ "GenSigStartValue" SG_ 277 TerrainModeReqExt 7;
BA_ "GenSigStartValue" SG_ 701 AmbientLightValueHLDF 255;
BA_ "GenSigStartValue" SG_ 701 SeatMoveSelectFrReq 1;
VAL_ 66 ABSBrakeLightRequest 0 "no brake light activation" 1 "brake light activation" ;
VAL_ 66 ABSMILRequest 0 "MIL Lamp off" 1 "MIL Lamp on" 2 "MIL Lamp flashing" 3 "Undefined" ;
VAL_ 66 EPBLongitudinalAcc 255 "Error marker" ;
VAL_ 66 EPBMode 0 "Not applied (inactive)" 1 "Applied dynamically (active)" 2 "Apply inhibit (inactive)" 3 "Applied statically (active)" 4 "Release inhibit (active)" 5 "Key-Out apply (active)" 6 "Not calibrated (assume inactive)" 7 "Clutch calibration mode enter (unknown)" 8 "Clutch calibration mode successful (unknown)" 9 "Clutch calibration mode abort (unknown)" 10 "Partially Applied (unknown)" 11 "Driver exit apply (Active)" 12 "External Apply Request Acknowledged (Inactive)" ;
VAL_ 66 EPBStatus 0 "Electric Park Brake disengaged." 1 "Electric Park Brake engaged." ;
VAL_ 66 HillDescentMode 0 "Undefined" 1 "Off" 2 "Selected; not active braking" 3 "Selected; active braking" 4 "Selected; not enabled - speed limit exceeded" 5 "Selected; not enabled - wrong gear selected" 6 "Selected; temporary unavailable" 7 "HDC Fault" ;
VAL_ 66 KeepNetInAfterRunABS 0 "don't keep network" 1 "keep network" ;
VAL_ 66 KeepNetInPreRunABS 0 "Function does not need the network" 1 "Function does need the network" ;
VAL_ 66 PBMReqBusAwake 0 "Node not requesting bus keepawake." 1 "Node requesting bus keepawake." ;
VAL_ 66 YawRate 1023 "Error Marker" ;
VAL_ 17 ABSEngVacReq 0 "no vacuum assistance required" 1 "vacuum assistance required" ;
VAL_ 17 ABSPwrTrnTorqReq 0 "powertrain torque is not required" 1 "powertrain torque is required" ;
VAL_ 17 BrakePressureQF 0 "The accuracy of the data is undefinable" 1 "Data is temporarily undefinable, evaluation in progress" 2 "The accuracy of the data is not within specification" 3 "The data is calculated with the specified accuracy" ;
VAL_ 17 VehicleSpeedQF 0 "The accuracy of the data is undefinable" 1 "Data is temporarily undefinable, evaluation in progress" 2 "The accuracy of the data is not within specification" 3 "The data is calculated with the specified accuracy" ;
VAL_ 418 DDShortDrop 0 "Inactive" 1 "Open" 2 "Close" 3 "Stop" ;
VAL_ 418 ImmoPStartApproved 0 "Passive Start Not Approved" 1 "Passive Start Approved" ;
VAL_ 418 OMAStartMode 0 "Passive" 1 "Normal" ;
VAL_ 418 PDShortDrop 0 "Inactive" 1 "Open" 2 "Close" 3 "Stop" ;
VAL_ 418 TaskLightRelaxLEDStat_A 0 "Telltale Off" 1 "Telltale On" ;
VAL_ 418 TaskLightRelaxLEDStat_B 0 "Telltale Off" 1 "Telltale On" ;
VAL_ 418 TaskLightWorkLEDStat_A 0 "Telltale Off" 1 "Telltale On" ;
VAL_ 418 TaskLightWorkLEDStat_B 0 "Telltale Off" 1 "Telltale On" ;
VAL_ 418 TREcoButtonBCM 0 "Not Pressed" 1 "Press" 2 "Fault" 3 "Reserved" ;
VAL_ 763 CascadeIllumIntensity 255 "Fault condition Present" ;
VAL_ 763 CascadeIllumRampTime 255 "Fault" ;
VAL_ 763 CascadeIllumZone1 0 "No action" 1 "Ramp" ;
VAL_ 763 CascadeIllumZone2 0 "No action" 1 "Ramp" ;
VAL_ 763 CascadeIllumZone3 0 "No action" 1 "Ramp" ;
VAL_ 763 CascadeIllumZone4 0 "No action" 1 "Ramp" ;
VAL_ 255 CarMode 0 "Normal" 1 "Factory" 2 "Unused2" 3 "Transport" 4 "Unused4" 5 "Crash" ;
VAL_ 255 CentralLockLastCmdOrig 0 "NONE" 1 "CLSW" 2 "CLSW_FDO" 3 "AutoLock" 4 "Relock" 5 "KV" 6 "CrashUnlock" 7 "AutoUnlock" 8 "Ignition" 9 "Remote" 10 "Telematics" 11 "Mechanical Key" 12 "Diagnostic" 13 "Knob or Inner door handle" 14 "CLSW_PDO" 15 "Unused (Undefined)" ;
VAL_ 255 DIFunctionStatus 0 "OFF" 1 "Hazards" 2 "Crash" 3 "Lock" 4 "Alarm" 5 "Step in Gesture" 6 "LH DI" 7 "RH DI" 8 "Trailer Test Sequence" 9 "Inflation Assist" 10 "Driver Condition Response" 11 "Rear End Collision" 12 "Low Speed Manoeuvre LH" 13 "Low Speed Manoeuvre RH" 14 "Low Speed Manoeuvre (Hazards)" 15 "Emergency Braking" 16 "Remote Vehicle Location" 17 "RESERVED15" 18 "RESERVED14" 19 "RESERVED13" 20 "RESERVED12" 21 "RESERVED11" 22 "RESERVED10" 23 "RESERVED9" 24 "RESERVED8" 25 "RESERVED7" 26 "RESERVED6" 27 "RESERVED5" 28 "RESERVED4" 29 "RESERVED3" 30 "RESERVED2" 31 "RESERVED1" ;
VAL_ 255 DirectionIndicationSwitch 0 "Neutral" 1 "Right" 2 "Left" 3 "Open Circuit Fault" 4 "Short Circuit Fault" 5 "Missing Signal Fault" 6 "Initialisation Default State" 7 "Undefined (Unused)" ;
VAL_ 255 ExtLgtAutoTellTaleRq 0 "OFF" 1 "Auto" 2 "Reserved1" 3 "Reserved2" ;
VAL_ 255 HeadlampSequenceReq 0 "IDLE" 1 "WAKEUP" 2 "SHUTDOWN" 3 "STOP" 4 "RESERVED1" 5 "RESERVED2" 6 "RESERVED3" 7 "RESERVED4" ;
VAL_ 255 MainBeamIndication 0 "Main beam lamps OFF" 1 "Main beam lamps ON" ;
VAL_ 255 MHSwitchStatusBCM 0 "MH Button not pressed" 1 "MH Button pressed" 2 "Reserved" 3 "Switch fault (stuck on)" ;
VAL_ 255 PowerMode 0 "KeyOut" 1 "KeyRecentlyOut" 2 "KeyApproved_0" 3 "PostAccessory_0" 4 "Accessory_1" 5 "PostIgnition_1" 6 "IgnitionOn_2" 7 "Running_2" 9 "Crank_3" ;
VAL_ 255 PowerModeQF 0 "PowerModeUndefined" 1 "PowerModeEvaluationInProgress" 2 "Not defined" 3 "PowerModeOK" ;
VAL_ 255 RemoteEngStartDrivPres 0 "Driver Not Present" 1 "Driver Present" ;
VAL_ 255 RemoteFunctionStatus 0 "Default" 1 "Engine Start Allowed" 2 "Engine Blocked" 15 "Invalid" ;
VAL_ 255 RemoteStartStatusMS 0 "Normal Mode (Driver present)" 1 "Remote Mode (Driver NOT present)" ;
VAL_ 255 ReversedGear 0 "Reversed Gear is not used." 1 "Reversed Gear is used" ;
VAL_ 255 RunningStandby 0 "Engine is NOT in Eco Stop" 1 "Engine is in Eco Stop" ;
VAL_ 255 StartModeReq 0 "None" 1 "Smart" 2 "Normal" 3 "Fault" 4 "Limited" 5 "Remote" 6 "Reserved6" 7 "Reserved7" ;
VAL_ 255 StartSwitchPressed 0 "Not Pressed" 1 "Pressed" ;
VAL_ 255 TransitState 0 "Not in Transport (Normal)" 1 "In Transport" ;
VAL_ 673 FrontFoglightSwitchPos 0 "Button not Pressed" 1 "Button pressed" ;
VAL_ 673 TransitSwitchActive 0 "Inactive (Not Fitted)" 1 "Active (Fitted)" ;
VAL_ 673 WasherRearCmd 0 "Off" 1 "On" ;
VAL_ 673 WiperFrontCmd_EuCD 0 "Off" 1 "Intermittent" 2 "Continous Low" 3 "Continous High" 4 "Single Stroke" ;
VAL_ 673 WiperRearCmd 0 "Off" 1 "Intermittent" 2 "Continous Low" ;
VAL_ 675 AFSWarningLamp 0 "Off" 1 "Lamp Flashing" 2 "Lamp on continuously" 3 "Reserved" ;
VAL_ 675 EngineStartSeqMsgReq 0 "All warnings Off" 1 "Brake Pedal Not Pressed, warning on" 2 "Brake Pedal pressed, warning on" 3 "Reserved" 4 "Clutch Pedal Not pressed, warning on" 5 "Clutch Pedal Pressed, warning on" 6 "Vehicle moving, engine stopped warning on" 7 "Vehicle moving, engine start warning on" ;
VAL_ 675 EngineStartWarningReq 0 "Off" 1 "On" ;
VAL_ 675 EngineStopReqWarning 0 "False" 1 "True" ;
VAL_ 675 EngineStopWarningMsg 0 "Warning Off" 1 "Engine Stop Warning On" 2 "Engine Start Warning On" 3 "Reserved" ;
VAL_ 675 GestureBlindStatus 0 "Gesture Blind Disabled" 1 "Gesture Blind Enabled" ;
VAL_ 675 HeadLampStatus 0 "OFF" 1 "Headlamps ON (user selected, NOT DRL or Exit Delay driven)" ;
VAL_ 675 IgnitionOnWarning 0 "False" 1 "True" ;
VAL_ 675 PKeyDockedWarning 0 "FALSE" 1 "TRUE" ;
VAL_ 675 RearFoglightIndication 0 "Turn Tell Tale Off" 1 "Turn Tell Tale On" 2 "Missing Signal" 3 "Initialisation/Default" ;
VAL_ 675 SelectParkWarning 0 "Warning Inactive" 1 "Warning Active" ;
VAL_ 675 SensorOverrideStatus 0 "Sensor Override Inactive (Sensors Enabled)" 1 "Sensor Override Active (Sensors Disabled)" ;
VAL_ 675 SmartKeyDeactivatedReq 0 "NoAlert" 1 "KeyDeactivated" ;
VAL_ 675 StartAndBrakeWarning 0 "Off" 1 "On" ;
VAL_ 675 StartAndClutchWarning 0 "Warning Off" 1 "Warning On" ;
VAL_ 675 StartStop1Warning 0 "Warning Inactive" 1 "Warning Active" ;
VAL_ 675 StartStop2Warning 0 "Warning Inactive" 1 "Warning Active" ;
VAL_ 675 TgateOrGlassStatus 0 "Tailgate" 1 "Glass" ;
VAL_ 675 TripButtonStatus 0 "Not Pressed" 1 "Pressed" 2 "Not Pressed" 3 "Pressed" 4 "Not Pressed" 5 "Pressed" 6 "Not Pressed" 7 "Pressed" 8 "Not Pressed" 9 "Pressed" 10 "Not Pressed" 11 "Pressed" 12 "Not Pressed" 13 "Pressed" 14 "Not Pressed" 15 "Pressed" ;
VAL_ 675 ValetModeChimeAndMsgReq 0 "No Chime and Message" 1 "Chime and Message" ;
VAL_ 675 WasherFluidLevelWarning 0 "Washer Fluid Level Warning OFF." 1 "Washer Fluid Level Warning ON." ;
VAL_ 676 CurrAutoFoldSett 0 "Disabled" 1 "Enabled" ;
VAL_ 676 IndicationIllumCmd 0 "Night Illumination" 1 "Day Illumination" ;
VAL_ 676 MemoryRecallCancelCol 0 "Not Cancelled" 1 "Cancelled" ;
VAL_ 677 AmbLightDynModeStatus 0 "Vehicle Dynamic Mode not active" 1 "Vehicle Dynamic Mode active" ;
VAL_ 677 AmbLightProfileStat 0 "No Profile" 1 "Profile 1" 2 "Profile 2" 3 "Profile 3" 4 "Profile 4" 5 "Not Used" 6 "Default" 7 "Default 2" ;
VAL_ 677 AmbLightUIDynAutoStat 0 "Auto Dynamic Lighting OFF" 1 "Auto Dynamic Lighting ON" ;
VAL_ 678 ComfortRlyOffImminent 0 "Comfort Relay ON" 1 "Comfort Relay OFF or about to be turned OFF" ;
VAL_ 678 DipBeamStatus 0 "Dipped Beam Off" 1 "Dipped Beam On" ;
VAL_ 678 DipMirrSetngApp 0 "Settings not applied" 1 "Settings applied" ;
VAL_ 678 ExtLightSetngAppl 0 "Settings not applied" 1 "Settings applied" ;
VAL_ 678 GotoEntryExitPos 0 "Off" 1 "Exit Movement" 2 "Entry Movement" 3 "Undefined (Unused)" ;
VAL_ 678 HFSStatus 0 "Off, no failure" 1 "On, no failure" 2 "Fault condition present" 3 "Undefined (Unused)" ;
VAL_ 678 HRWStatus 0 "Off, no failure" 1 "On, no failure" 2 "Fault condition present" 3 "Undefined (Unused)" ;
VAL_ 678 IgnoreLatchOnUnlock 0 "Do not scan for keys if door reporting unlocked." 1 "Always scan for keys on a door handle pull and send unlock req" ;
VAL_ 678 IntLightSetngAppl 0 "Settings not applied" 1 "Settings applied" ;
VAL_ 678 POTailgateLatchStatus 0 "Unlatched" 1 "Closed / Latched" ;
VAL_ 678 POTLatchStatLwrLHS 0 "Unlatched" 1 "Closed / Latched" ;
VAL_ 678 POTLatchStatLwrRHS 0 "Unlatched" 1 "Closed / Latched" ;
VAL_ 678 PrivateLockStatus 0 "Private Lock Deactivated" 1 "Private Lock Activated" ;
VAL_ 678 PwrTGOpenCloseReq 0 "Not used" 1 "Exterior Tailgate Open/Close Request" 2 "RF Keyfob Tailgate Open/Close Request" 3 "Interior Tailgate Open/Close Request" 4 "Hands Free (Kick Sensor)Open/Close Request" 5 "Hands Free (ePEPS Gesture)Open/Close Request" 6 "For future use6" 7 "For future use7" 8 "For future use8" 9 "For future use9" 10 "For future use10" 11 "For future use11" 12 "For future use12" 13 "For future use13" 14 "For future use14" 15 "For future use15" ;
VAL_ 678 PwrTGOpenCloseReqLwr 0 "Not used" 1 "Exterior Tailgate Open/Close Request" 2 "RF Keyfob Tailgate Open/Close Request" 3 "Interior Tailgate Open/Close Request" 4 "Hands Free (Kick Sensor)Open/Close Request" 5 "Hands Free (ePEPS Gesture)Open/Close Request" 6 "Lower Shutface switch" 7 "For future use7" 8 "For future use8" 9 "For future use9" 10 "For future use10" 11 "For future use11" 12 "For future use12" 13 "For future use13" 14 "For future use14" 15 "For future use15" ;
VAL_ 678 PwrTGUpperAndLwrReq 0 "Not used" 1 "Exterior Tailgate Open/Close Request" 2 "RF Keyfob Tailgate Open/Close Request" 3 "Interior Tailgate Open/Close Request" 4 "Hands Free (Kick Sensor)Open/Close Request" 5 "Hands Free (ePEPS Gesture)Open/Close Request" 6 "For future use6" 7 "For future use7" 8 "For future use8" 9 "For future use9" 10 "For future use10" 11 "For future use11" 12 "For future use12" 13 "For future use13" 14 "For future use14" 15 "For future use15" ;
VAL_ 678 TrailerFogLights 0 "Disable" 1 "Enable" ;
VAL_ 678 TrailerReverseLights 0 "Disable" 1 "Enable" ;
VAL_ 678 TrailerTailLightsL 0 "Disable" 1 "Enable" ;
VAL_ 678 TrailerTailLightsR 0 "Disable" 1 "Enable" ;
VAL_ 678 UserStartReq 0 "UserStartReq = Inactive " 1 "UserStartReq = Active" ;
VAL_ 938 RESAlarmStatus 0 "active or unknown" 1 "alarm not active" ;
VAL_ 938 RESBrakePedalStatus 0 "pressed or unknown" 1 "pedal not pressed" ;
VAL_ 938 RESEngineRunningStatus 0 "engine running or state unknown" 1 "engine not running" ;
VAL_ 938 RESHazardSwitchStatus 0 "pressed or unknown" 1 "switch not pressed" ;
VAL_ 938 RESSequenceStatus 0 "in progress or unknown" 15 "operation succeded" ;
VAL_ 938 RESTransmissionStatus 0 "transmission not in park or state unknown" 1 "transmission in park" ;
VAL_ 938 RESVehicleLockStatus 0 "unlocked or unknown" 1 "vehicle locked" ;
VAL_ 938 RESVehStationaryStatus 0 "vehicle not stationary or state unknown" 1 "vehicle stationary" ;
VAL_ 938 RESWindowStatus 0 "at least one open or unknown" 1 "all closed" ;
VAL_ 423 ExteriorLightFunctionStatus 0 "OFF" 1 "Position Light" 2 "Dipped Beam" 3 "Auto Light Dipped Beam" 4 "Auto Light DRL " 5 "Unused" 6 "Unused" 7 "Unused" ;
VAL_ 423 ExteriorLightSwitchPos2 0 "Neutral" 1 "Position Light" 2 "OFF" 3 "Dipped Beam" 4 "Auto Light" ;
VAL_ 423 MainBeamSwitch 0 "Neutral:The switch is not used." 1 "Flash: The switch is used in position one" 2 "Not applicable" 3 "Toggle: The switch is used in position two" ;
VAL_ 420 DiagHeadLightFault 0 "No Fault" 1 "Fault" ;
VAL_ 420 DirectionIndSwitchPos 0 "Neutral: The DirectionIndicatorSwitch is not in used" 1 "Left: Left indicator is in used." 2 "Not applicable" 3 "Right: Right indicator is in used." ;
VAL_ 420 FLDirectionIndicatorBulbFail 0 "Front Left Bulb OK" 1 "Front Left Bulb Failed" 2 "Missing Signal" 3 "Initialisation/Default" ;
VAL_ 420 FRDirectionIndicatorBulbFail 0 "Front Right Bulb OK" 1 "Front Right Bulb Failed" 2 "Missing Signal" 3 "Initialisation/Default" ;
VAL_ 420 LeftStopLampBulbFailure 0 "Left Brake Lamp Ok" 1 "Left Brake Lamp Failed" 2 "Missing Signal" 3 "Initialisation Default" ;
VAL_ 420 LowBeamFailureLH 0 "Lamp OK" 1 "Lamp Failed" ;
VAL_ 420 LowBeamFailureRH 0 "Lamp OK" 1 "Lamp Failed" ;
VAL_ 420 LSMAlsDippedBeamReqB 0 "Off" 1 "Dipped Beam ON" ;
VAL_ 420 MainBeamStatus 0 "Turn Tell Tale Off" 1 "Turn Tell Tale On" 2 "Missing Signal" 3 "Initialisation/Default" ;
VAL_ 420 NaturalLight 0 "Light" 1 "Dark" ;
VAL_ 420 RightStopLampBulbFailure 0 "Left Brake Lamp Ok" 1 "Left Brake Lamp Failed" 2 "Missing Signal" 3 "Initialisation Default" ;
VAL_ 420 RLDirectionIndicatorBulbFail 0 "Rear Left Bulb OK" 1 "Rear Left Bulb Failed" 2 "Missing Signal" 3 "Initialisation Default" ;
VAL_ 420 RLPositionLampBulbFailure 0 "Left Taill Lamp OK" 1 "Left Taill Lamp Failed" 2 "Missing Signal" 3 "Initialisation Default" ;
VAL_ 420 RRDirectionIndicatorBulbFail 0 "Rear Right Bulb OK" 1 "Rear Right Bulb Failed" 2 "Missing Signal" 3 "Initialisation Default" ;
VAL_ 420 RRPositionLampBulbFailure 0 "Right Taill Lamp OK" 1 "Right Taill Lamp Failed" 2 "Missing Signal" 3 "Initialisation Default" ;
VAL_ 420 SCLWarningReq 0 "Warning Off" 1 "SCL Warning (Level 1)" 2 "SCL Warning (Level 2)" 3 "Reserved" ;
VAL_ 420 SidelightStatus 0 "Turn Tell Tale Off" 1 "Turn Tell Tale On" 2 "Missing Signal" 3 "Initialisation/Default" ;
VAL_ 420 SupMainBeamRoutineReq 0 "OFF" 1 "ON at 100% intensity" 2 "ON at a configurable intensity" 3 "Reserved" ;
VAL_ 420 WipeSpeedRainSensor 0 "No wiping, 0 sweeps per minute" 1 "43 sweeps per minute or Slow Wipe" 2 "45 sweeps per minute" 3 "48 sweeps per minute" 4 "51 sweeps per minute" 5 "54 sweeps per minute" 6 "57 sweeps per minute" 7 "60 sweeps per minute or Fast Wipe" ;
VAL_ 421 BeltReminderSensor 0 "Front passenger not seated" 1 "Front passenger seated" ;
VAL_ 421 BeltReminderSensorRL 0 "Front passenger not seated" 1 "Front passenger seated" ;
VAL_ 421 BeltReminderSensorRM 0 "Front passenger not seated" 1 "Front passenger seated" ;
VAL_ 421 BeltReminderSensorRR 0 "Front passenger not seated" 1 "Front passenger seated" ;
VAL_ 421 BeltRmderSensorRow1M 0 "UNBUCKLED" 1 "BUCKLED" ;
VAL_ 421 BeltRmderSensorRow3LMS 0 "passenger not seated" 1 "passenger seated" ;
VAL_ 421 BeltRmderSensorRow3M 0 "UNBUCKLED" 1 "BUCKLED" ;
VAL_ 421 BeltRmderSensorRow3RMS 0 "passenger not seated" 1 "passenger seated" ;
VAL_ 421 BrakeLampOnStatus 0 "One or more brake lamps successfully turned off" 1 "One or more brake lamps successfully turned on" 3 "None of the three brake lamps can be illuminated." ;
VAL_ 421 CentralLockStatus 0 "Unlocked" 1 "Part Locked" 2 "Central Locked" 3 "Double Locked" 4 "TP_NO_DL (TheftProtectNODoubleLock)" ;
VAL_ 421 DriverSteerColMovReq 0 "No Driver Steering Column request" 1 "Driver Steering Column Request" ;
VAL_ 421 DRLStatus 0 "Both DRLs are OFF" 1 "Right DRL ON" 2 "Left DRL ON" 3 "Both DRLs ON" ;
VAL_ 421 RainSenseStatus 0 "intermittent mode" 1 "auto mode" ;
VAL_ 421 RainSensorActive 0 "RLS Inactive" 1 "RLS Active, WMM (FSJB) waits for wiping commands from RLS. " ;
VAL_ 421 RemoteRaiseLower 0 "No request" 1 "Raise request" 2 "Lower request" 3 "Return to Normal height  " ;
VAL_ 421 SteerColState 0 "DriverPos" 1 "DriverToAutoPos" 2 "AutoPos" 3 "AutoToDriverPos" ;
VAL_ 422 BacklightIntensity 255 "Fault condition Present" ;
VAL_ 422 BacklightScreenIntensity 255 "Fault condition Present" ;
VAL_ 422 BacklightStatus 0 "Backlight is Off" 1 "Backlight is On" ;
VAL_ 422 FrontFogLightIndication 0 "Turn Tell Tale Off" 1 "Turn Tell Tale On" 2 "Missing Signal" 3 "Initialisation" ;
VAL_ 422 GearLeverPosition 0 "P (Park)" 1 "R (Reverse)" 2 "N (Neutral)" 3 "D (Drive)" 4 "4th" 5 "3rd" 6 "L (Low)" 7 "Not defined" ;
VAL_ 422 HeadlampExitDelayStatus 0 "0 Seconds (Off)" 1 "30 Seconds" 2 "60 Seconds" 3 "120 Seconds" 4 "240 Seconds" 5 "Blank (Initial Signal)" ;
VAL_ 422 NightStatus 0 "Day" 1 "Night" ;
VAL_ 422 TrailerConnection 0 "No trailer connected" 1 "Trailer connected" ;
VAL_ 422 WasherFrontCmd_EUCD 0 "Off" 1 "On" ;
VAL_ 422 WiperStatus 0 "Wipers Off" 1 "Intermittent Wipe" 2 "Normal (Slow) Continuous Wipe" 3 "Fast Continuous Wipe" ;
VAL_ 935 AmbientLightValueRLS 254 "Light sensor not available" 255 "Light sensor faulty i.e open circuit or short circuit etc" ;
VAL_ 935 AutoBlindEnableStatus 0 "Disabled" 1 "Enabled" ;
VAL_ 935 BatteryStateText 0 "No text displayed" 1 "'Good Battery'" 2 "'Battery Test in Progress'" 3 "'Charge Battery'" 4 "'Replace Battery'" ;
VAL_ 935 BCM_EPBWarningLamp 0 "Lamp OFF" 1 "Lamp ON" ;
VAL_ 935 BrakeFluidLevelWarning 0 "Warning lamp switched ON" 1 "Warning lamp switched OFF" ;
VAL_ 935 BrakePadWearLampReq 0 "Brake pads OK" 1 "Brake pads worn" ;
VAL_ 935 CarModeText 0 "No text" 1 "FactoryText" 2 "FactoryPausedText" 3 "TransportText" 4 "TransportPausedText" 5 "CrashText" 6 "Unused" 7 "NormalText" ;
VAL_ 935 CoolantLevel 0 "High coolant level" 1 "Low coolant level" ;
VAL_ 935 HomeSafeLightInd 0 "Inactive" 1 "Active" ;
VAL_ 935 ParkClimateReq 0 "Off" 1 "On" ;
VAL_ 935 PosLightInd 0 "Off" 1 "On" ;
VAL_ 935 SunroofOpen 0 "FullyClosed " 1 "NotFullyClosed" ;
VAL_ 935 TrailerLightTestActive 0 "OFF" 1 "ON" ;
VAL_ 935 TRStatus 0 "Not fitted" 1 "Waiting for dropout" 2 "Energised by BCM" 3 "Unused" ;
VAL_ 935 ValetStatus 0 "Valet Mode Inactive" 1 "Valet Mode Active" ;
VAL_ 935 WasherFluidLevelLow 0 "Washer Fluid Level Warning OFF." 1 "Washer Fluid Level Warning ON." ;
VAL_ 935 WashingCycleActive_s 0 "No washing" 1 "Front wash is active, signal active even during post wipe cycles" ;
VAL_ 424 AutoSwitchDRLStatusReq 0 "NONE" 1 "RESERVED1" 2 "DRL_OFF" 3 "RESERVED2" 4 "DRL_Temp_OFF" 5 "DRL_ON" 6 "RESERVED4" 7 "RESERVED5" ;
VAL_ 424 ImmobiliserWarning 0 "No Warning Message exists" 1 "Warning Message exists" ;
VAL_ 424 RemoteGlobalCloseStatus 0 "Remote global close deactivated (Off)" 1 "Remote global close activated (On)" ;
VAL_ 424 RemoteGlobalOpenStatus 0 "Remote global open deactivated (Off)" 1 "Remote global open activated (On)" ;
VAL_ 424 StgColLockGndEnableCmd 0 "Off/Lock" 1 "Off/Unlock" 2 "On/Lock" 3 "On/Unlock" ;
VAL_ 424 StgColLockWarningReq 0 "Warning Off" 1 "Warning On" ;
VAL_ 425 AlarmSensorFailureInd 0 "No Message" 1 "Message" ;
VAL_ 425 ColumnAdjustSwitchStatus 0 "Column Adjust Auto Selected" 1 "Pedal Adjust Selected" 2 "Column Adjust Selected" 3 "Initial / Unknown Selection" ;
VAL_ 425 DIAnimationEnableSta 0 "Disabled" 1 "Enabled" ;
VAL_ 425 DriveAwayLockingStatus 0 "Drive away locking deactivated " 1 "Drive away locking speed 5 mph activated" 2 "Drive away locking speed 10 mph activated" 3 "Drive away locking speed 20 mph activated" ;
VAL_ 425 FactoryState 0 "Factory Mode Request Not Active" 1 "Factory Mode Request Active" ;
VAL_ 425 LastAlarmCause 0 "No Trigger (Event Store Empty)" 1 "Driver Door Ajar" 2 "Passenger Door Ajar" 3 "Right Rear Door Ajar" 4 "Left Rear Door Ajar" 5 "Tailgate/Boot" 6 "Bonnet/Hood" 7 "Convertible Roof" 8 "Module 1 Disconnect" 9 "Module 2 Disconnect" 10 "Start Attempt" 11 "Volumetric Sensor" 12 "Tilt Sensor" 13 "Driver Door Unlock" 14 "Passenger Door Unlock" 15 "Rear Left Door Unlocked" 16 "Rear Right Door Unlocked" 17 "Slave Volumetric Sensor" 18 "Panic" 19 "Tailgate Glass/Secondary" 20 "Tailgate Lower" 21 "Impact Event" 22 "Charge Plug Disconnect" ;
VAL_ 425 LockChirpsStatus 0 "LockChirps deactivated" 1 "LockChirps activated" ;
VAL_ 425 OilPressureSwitchRaw 0 "Switch open circuit (oil pressure ok)" 1 "Switch closed to gnd (no oil pressure)" ;
VAL_ 425 RemovePlugWarning 0 "NONE" 1 "ALERT#1" 2 "ALERT#2" 3 "ALERT#3" 4 "ALERT#4" 5 "ALERT#5" 6 "ALERT#6" 7 "ALERT#7" ;
VAL_ 425 SinglePointEntryStatus 0 "Single Point Entry Off" 1 "Single Point Entry On" ;
VAL_ 425 SmartKeyWarningReq 0 "Warning Off" 1 "Unable to find smart key" 2 "Transponder Not Detected" 3 "Transponder Error" ;
VAL_ 425 StealthModeStatus 0 "Stealth mode inactive" 1 "Stealth mode active" ;
VAL_ 425 TimerActivationStatus 0 "Off" 1 "On" ;
VAL_ 425 WiperWinterParkStatus 0 "Disabled" 1 "Enabled" ;
VAL_ 225 CentralLockLastCmdOrig2 0 "NONE" 1 "CLSW" 2 "CLSW_FDO" 3 "AutoLock" 4 "Relock" 5 "KV" 6 "CrashUnlock" 7 "AutoUnlock" 8 "Ignition" 9 "Remote" 10 "Telematics" 11 "Mechanical Key" 12 "Diagnostic" 13 "Knob or Inner door handle" 14 "CLSW_PDO" 15 "Unused (Undefined)" ;
VAL_ 225 CentralLockStatus2 0 "Unlocked" 1 "Part Locked" 2 "Central Locked" 3 "Double Locked" 4 "TP_NO_DL (TheftProtectNODoubleLock)" ;
VAL_ 225 DriverDoorLockCmd 0 "Undefined" 1 "Single Lock (ext handles inhibit)" 2 "Unlock (Un-Single Lock & Un-Double Lock)-'Provisionally Unlocked" 3 "Double Lock (int handles inhibit)" ;
VAL_ 225 FrontPassDoorLockCmd 0 "Undefined" 1 "Single Lock (ext handles inhibit)" 2 "Unlock (Un-Single Lock & Un-Double Lock) " 3 "Double Lock (int handles inhibit)" ;
VAL_ 225 RearDriverDoorLockCmd 0 "Undefined" 1 "Single Lock (ext handles inhibit)" 2 "Unlock (Un-Single Lock & Un-Double Lock)-'Provisionally Unlocked" 3 "Double Lock (int handles inhibit)" ;
VAL_ 225 RearPassDoorLockCmd 0 "Undefined" 1 "Single Lock (ext handles inhibit)" 2 "Unlock (Un-Single Lock & Un-Double Lock) " 3 "Double Lock (int handles inhibit)" ;
VAL_ 227 ePEPSLockResult 0 "Ignore" 1 "ePEPS Lock Request Failed" 2 "ePEPS Lock Request Successful" ;
VAL_ 227 GlobalWindowReq 0 "Global stop request" 1 "Global closing request via remote control" 2 "Global open request" 3 "Global closing request via CL Switch" ;
VAL_ 227 LocationOfKeysRequest 0 "Not Used" 1 "Request for key location report" ;
VAL_ 227 PKExteriorScanReq 0 "Not used" 1 "Rear" 2 "LHSide" 3 "RH Side" ;
VAL_ 227 PKInteriorScanReq 0 "Not used" 1 "Activate" ;
VAL_ 227 POTUpperAndLowerReq 0 "Nothing" 1 "Stop" 2 "One touch Open/Close from" 3 "One touch open only" 4 "One touch open/start deadmans close " 5 "Continue deadmans close" 6 "One touch close only" 7 "Unused" ;
VAL_ 227 PowerTailgateReq 0 "Nothing" 1 "Stop" 2 "One touch Open/Close from" 3 "One touch open only" 4 "One touch open/start deadmans close " 5 "Continue deadmans close" 6 "One touch close only" 7 "Unused" ;
VAL_ 227 PowerTailgateReqLwr 0 "Nothing" 1 "Stop" 2 "One touch Open/Close from" 3 "One touch open only" 4 "One touch open/start deadmans close " 5 "Continue deadmans close" 6 "One touch close only" 7 "Unused" ;
VAL_ 227 PuddleLightActivation 0 "Off: The PuddleLight is not activated." 1 "On: The PuddleLight is activated." ;
VAL_ 227 RFARequestAck 0 "Default" 1 "RKE Lock (Single or double)" 2 "RKE Unlock" 3 "RKE Tailgate/boot" 4 "RKE Approach Light toggle" 5 "RKE Panic Alarm" 6 "Security Change Req" 7 "RKE Change Lock Mode (SPE/MPE)" 8 "Raise Suspension" 9 "Lower suspension" ;
VAL_ 227 RKELockResult 0 "Ignore" 1 "RKE Lock Request Failed" 2 "RKE Lock Request Successful" ;
VAL_ 230 AlarmModeMS 0 "Set" 1 "Unset" 2 "Active" 3 "Ignore (Initial Value)" ;
VAL_ 230 DirectionIndication 0 "Neutral: The indication is not in use." 1 "Left: Left indication is illuminated on the display" 2 "Right: Right indication is illuminated on the display" 3 "Hazard: Left and Right indication are illuminated on the display" ;
VAL_ 230 DirectionIndicationINST 0 "Neutral: The indication is not in use." 1 "Left: Left indication is illuminated on the display" 2 "Right: Right indication is illuminated on the display" 3 "Hazard: Left and Right indication are illuminated on the display" ;
VAL_ 230 ImmoFailureInd 0 "No error" 1 "Key error" 2 "Passive key error" 3 "Immo error" ;
VAL_ 230 InteriorLightMode 0 "Automatic mode" 1 "Manual mode" ;
VAL_ 230 KeyWarningInd 0 "None" 1 "Normal" 2 "Passive" 3 "Gear to P position" ;
VAL_ 230 LDWSwitchReq 0 "Not Pressed" 1 "Pressed" ;
VAL_ 230 LowBeamIndication 0 "Low beam lamps OFF" 1 "Low beam lamps ON" ;
VAL_ 230 TrailerDILeft 0 "Disable" 1 "Enable" ;
VAL_ 230 TrailerDirectionInd 0 "Direction indication trailer telltale OFF" 1 "Direction indication trailer telltale ON" ;
VAL_ 230 TrailerDIRight 0 "Disable" 1 "Enable" ;
VAL_ 230 TrailerStopLamp 0 "Disable" 1 "Enable" ;
VAL_ 230 WakeShutDownEnableSta 0 "DISABLE" 1 "ENABLE" ;
VAL_ 270 CVDMessage 0 "No message requested" 1 "Fault message requested" ;
VAL_ 270 SuspensionHeightFL 511 "Error Marker" ;
VAL_ 270 SuspensionHeightFR 511 "Error Marker" ;
VAL_ 270 SuspensionHeightRL 511 "Error Marker" ;
VAL_ 270 SuspensionHeightRR 511 "Error Marker" ;
VAL_ 207 AutonomyLevel 0 "Unavailable (Default)" 1 "Level 0" 2 "Level 1" 3 "Level 2" 4 "Level 3" 5 "Level 4" 6 "Level 5" 7 "Reserved" ;
VAL_ 207 DADCHazLightReq 0 "No Request" 1 "RPC" 2 "DCR" 3 "Reserved" ;
VAL_ 207 DADCHvacAutoMode 0 "Not Required" 1 "Auto Mode Required" ;
VAL_ 207 DADCPCVehState 0 "No Request" 1 "Rear Pre Crash" 2 "Front Pre Crash" 3 "Pre Crash Return" 4 "Reserved4" 5 "Reserved5" 6 "Reserved6" 7 "Reserved7" ;
VAL_ 207 DADCSteerMovReq 0 "DriverSteeringPosition" 1 "AutomatedSteeringPosition" ;
VAL_ 207 DADCWiperModeReq 0 "Driver Selected" 1 "Automode" ;
VAL_ 207 HapticSeatReq 0 "Off" 1 "Haptic feedback 1" 2 "Haptic feedback 2" 3 "Haptic feedback 3" 4 "Haptic feedback 4" 5 "Haptic feedback 5" 6 "Haptic feedback 6" 7 "Haptic feedback 7" ;
VAL_ 207 HeadLampModeReq 0 "Driver Selected" 1 "Automode" ;
VAL_ 207 LDSOnStatus 0 "Off" 1 "On" ;
VAL_ 498 AccessMode 0 "Not Pressed" 1 "Pressed" ;
VAL_ 498 ChildLockCmd 0 "Deactivate " 1 "Activate " ;
VAL_ 498 DDClawSwitchStatus 0 "INACTIVE (OPEN/unlatched)" 1 "ACTIVE (CLOSED/latched)" ;
VAL_ 498 DDMReqBusAwake 0 "No Request" 1 "Request Active" ;
VAL_ 498 DDMSetngAppl 0 "Settings not applied" 1 "Settings applied" ;
VAL_ 498 DDPawlSwitchStatus 0 "INACTIVE (OPEN/unlatched)" 1 "ACTIVE (CLOSED/latched)" ;
VAL_ 498 DriverDoorSCAStatus 0 "SCA in home position" 1 "SCA closing" 2 "SCA returning" 3 "SCA position unknown" ;
VAL_ 498 DrvMirrorStatus 0 "Driver Mirror in Unknown state (Default value)" 1 "Driver Mirror Folded" 2 "Driver Mirror Un-Folded" 3 "Driver Mirror Fold in Progress" 4 "Driver Mirror Un-Fold in Progress" 5 "Fault in Folding Driver Mirror" 6 "Fault in Un-Folding Driver Mirror" 7 "Reserved or Not used" ;
VAL_ 498 DZMDrivLeftHmiOp 0 "Message Inactive" 1 "HMI Fault" 2 "HMI not illuminated" 3 "HMI status LED illuminated" 4 "HMI alert LED illuminated" ;
VAL_ 498 DZMDrivRightHmiOp 0 "Message Inactive" 1 "HMI Fault" 2 "HMI not illuminated" 3 "HMI status LED illuminated" 4 "HMI alert LED illuminated" ;
VAL_ 498 MemRecallCancelMirror 0 "Not Cancelled" 1 "Cancelled" ;
VAL_ 498 MirrorFoldStatus 0 "UnFolded" 1 "Folding" 2 "Unfolding" 3 "Folded" 4 "Driver Mirror Fold Error" 5 "Passenger Mirror Fold Error" 6 "Driver and Passenger Mirror Fold Error" 7 "Reserved" ;
VAL_ 498 PCLMessageReq 0 "No Display" 1 "Display Inactive Message" 2 "Display Active Message" 3 "Display Fail Message" 4 "Reserved4" 5 "Reserved5" 6 "Reserved6" 7 "Reserved7" ;
VAL_ 498 SeatMem1ButtonStatD 0 "Inactive/off" 1 "Active/on" ;
VAL_ 498 SeatMem2ButtonStatD 0 "Inactive/off" 1 "Active/on" ;
VAL_ 498 SeatMem3ButtonStatD 0 "Inactive/off" 1 "Active/on" ;
VAL_ 498 SeatMemLEDStatD 0 "Inactive/off" 1 "Active/on" ;
VAL_ 498 SeatMemSetBtnStatD 0 "Inactive/off" 1 "Active/on" ;
VAL_ 242 DDHandleStatus 0 "Initial Value" 1 "Not moving - position unknown" 2 "Not moving - door handle deployed" 3 "Not moving - door handle retracted" 4 "Moving - door handle deploying" 5 "Moving - door handle retracting" 6 "Door handle fault" 7 "Not Used" ;
VAL_ 242 DDLockSwitchPress 0 "Switch not active" 1 "Switch Active" ;
VAL_ 242 DDUnLockSwitchPress 0 "Switch not active" 1 "Switch Active" ;
VAL_ 242 DipMirrorPosPassenger 0 "Idle" 1 "Dip Mirror Pos" ;
VAL_ 242 DriverWindowPosition 0 "Undefined window position" 1 "Fully closed position" 2 "Between fully closed and 10 % open" 3 "Between 10 % open and 60 % open" 4 "Between 60 % open and fully open" 5 "Fully open position" ;
VAL_ 242 PassMirrorCmd 0 "Idle" 1 "Passenger Mirror Up" 2 "Passenger Mirror Down" 3 "Passenger Mirror Left" 4 "Passenger Mirror Right" 5 "Passenger Mirror Fold" 6 "Passenger Mirror Unfold" 7 "Unused (Undefined)" ;
VAL_ 242 PassWindowCmd 0 "Idle" 1 "Manual Up" 2 "Auto Up" 3 "Manual Down" 4 "Auto Down" ;
VAL_ 242 RearDriverWindowCmd 0 "Idle" 1 "Manual Up" 2 "Auto Up" 3 "Manual Down" 4 "Auto Down" ;
VAL_ 242 RearPassWindowCmd 0 "Idle" 1 "Manual Up" 2 "Auto Up" 3 "Manual Down" 4 "Auto Down" ;
VAL_ 242 RearWindowDisableCmd 0 "rear window enabled" 1 "rear window disabled" ;
VAL_ 476 RockerSwitch1Req_a 0 "Off" 1 "Up" 2 "Auto Up" 3 "Down" 4 "Auto Down" ;
VAL_ 476 RockerSwitch2Req_a 0 "Off" 1 "Up" 2 "Auto Up" 3 "Down" 4 "Auto Down" ;
VAL_ 476 SunRoofFrBlindBtnReq_A 0 "Button Released" 1 "Button Pressed" ;
VAL_ 476 TaskLightRelaxBtnReq_A 0 "Button Released" 1 "Button Pressed" ;
VAL_ 476 TaskLightWorkBtnReq_A 0 "Button Released" 1 "Button Pressed" ;
VAL_ 452 AudioMuteDR 0 "Button Released" 1 "Button Pressed" ;
VAL_ 452 DRDMReqBusAwake 0 "No Request" 1 "Request Active" ;
VAL_ 452 RearDDClawSwitchStatus 0 "INACTIVE (OPEN/unlatched)" 1 "ACTIVE (CLOSED/latched)" ;
VAL_ 452 RearDDPawlSwitchStatus 0 "INACTIVE (OPEN/unlatched)" 1 "ACTIVE (CLOSED/latched)" ;
VAL_ 452 RearDrivDoorSCAStatus 0 "SCA in home position" 1 "SCA closing" 2 "SCA returning" 3 "SCA position unknown" ;
VAL_ 452 RearDriverREDHMIStatus 0 "RED HMI Available" 1 "RED HMI Fault" ;
VAL_ 452 SeatMem1ButtonStatDR 0 "Inactive/off" 1 "Active/on" ;
VAL_ 452 SeatMem2ButtonStatDR 0 "Inactive/off" 1 "Active/on" ;
VAL_ 452 SeatMem3BUttonStatDR 0 "Inactive/off" 1 "Active/on" ;
VAL_ 452 SeatMemLEDStatDR 0 "Inactive/off" 1 "Active/on" ;
VAL_ 452 SeatMemSetBtnStatDR 0 "Inactive/off" 1 "Active/on" ;
VAL_ 551 DRDChildLockStatus 0 "Unlocked" 1 "Locked" 2 "Error" 3 "Ignore" ;
VAL_ 551 DRHandleStatus 0 "Initial Value" 1 "Not moving - position unknown" 2 "Not moving - door handle deployed" 3 "Not moving - door handle retracted" 4 "Moving - door handle deploying" 5 "Moving - door handle retracting" 6 "Door handle fault" 7 "Not Used" ;
VAL_ 551 DriverRearWindowPos 0 "Undefined window position" 1 "Fully closed position" 2 "Between fully closed and 10 % open" 3 "Between 10 % open and 60 % open" 4 "Between 60 % open and fully open" 5 "Fully open position" ;
VAL_ 551 RDDLockSwitchPress 0 "Switch not active" 1 "Switch Active" ;
VAL_ 551 RDDUnLockSwitchPress 0 "Switch not active" 1 "Switch Active" ;
VAL_ 400 DriverCancelSeat 0 "Not cancel" 1 "Cancel Movement" ;
VAL_ 400 DriverSeatMovementStat 0 "Default" 1 "Driver Seat Moving Rearwards" 2 "In Safe Position 1" 3 "In Safe Position 2" 4 "In Safe Position 3" 15 "Seat in Undefined Position (Driver Seat is in Other Position)" ;
VAL_ 400 DrvSeatOccupantStatus 0 "Driver Seat Unoccupied" 1 "Driver Seat Occupied" ;
VAL_ 400 FoldAllSeatsReqDSM 0 "Fold All Request Disabled" 1 "Fold All Request Enabled" ;
VAL_ 400 MemRecallCancelSeat 0 "Not Cancelled" 1 "Cancelled" ;
VAL_ 400 R2ISCM60SeatCancelDSM 0 "Not cancelled" 1 "Movement cancelled" ;
VAL_ 400 R2ISCM60SeatInSP1DSM 0 "Seat not in Safe position " 1 "Seat in Safe position" ;
VAL_ 400 R3RightSeatISCMCancDSM 0 "Not cancelled" 1 "Movement cancelled" ;
VAL_ 400 R3RightSeatISCMReqDSM 0 "IDLE" 1 "Row 3 Right Seat Folding in Zone 1" 2 "Row 3 Right Seat Folding in Zone 2" 3 "Row 3 Right Seat Folding in Zone 3" 4 "Row 3 Right Seat Unfolding in Zone 3" 5 "Row 3 Right Seat Unfolding in Zone 2" 6 "Row 3 Right Seat Unfolding in Zone 1" ;
VAL_ 400 RLSeatMsgAvailFrInt 0 "Not Available" 1 "Available" ;
VAL_ 400 RLSeatMsgModStatFrInt 0 "StandBy status" 1 "Program 1" 2 "Program 2" 3 "Program 3" 4 "Massage off" ;
VAL_ 400 RLSeatMsgModStatInt 0 "StandBy status" 1 "Program 1" 2 "Program 2" 3 "Program 3" 4 "Massage off" ;
VAL_ 400 RLSeatMsgStatFrInt 0 "Off" 1 "On" ;
VAL_ 400 RockerSwitch1ReqDSM_a 0 "Off" 1 "Up" 2 "Auto Up" 3 "Down" 4 "Auto Down" ;
VAL_ 400 RockerSwitch1ReqDSM_b 0 "Off" 1 "Up" 2 "Auto Up" 3 "Down" 4 "Auto Down" ;
VAL_ 400 RockerSwitch2ReqDSM_a 0 "Off" 1 "Up" 2 "Auto Up" 3 "Down" 4 "Auto Down" ;
VAL_ 400 RockerSwitch2ReqDSM_b 0 "Off" 1 "Up" 2 "Auto Up" 3 "Down" 4 "Auto Down" ;
VAL_ 400 UnFoldAllSeatsReqDSM 0 "UnFold All Request Disabled" 1 "UnFold All Request Enabled" ;
VAL_ 994 DrvrStSetngAppl 0 "Settings Not Applied" 1 "Settings Applied" ;
VAL_ 996 DSMReqBusAwake 0 "No Request" 1 "Request Active" ;
VAL_ 396 DriverSeatMassageStat 0 "Off" 1 "On" ;
VAL_ 396 DrvSeatInhib2ndRow 0 "Available to receive a seat movement request" 1 "Seat movement is Inhibited" ;
VAL_ 396 DrvSeatInhib3rdRow 0 "Available to receive a seat movement request" 1 "Seat movement is Inhibited" ;
VAL_ 396 DrvSeatPosition2ndRow 0 "Unknown / Initialising" 1 "Folded" 2 "Unfolded" 3 "Mid Travel (Stationary)" 4 "Moving" ;
VAL_ 396 DrvSeatPosition3rdRow 0 "Unknown / Initialising" 1 "Folded" 2 "Unfolded" 3 "Mid Travel (Stationary)" 4 "Moving" ;
VAL_ 396 HapticSeatStatus 0 "Not available" 1 "Available" 2 "Actuating" 3 "Fault" ;
VAL_ 394 DriverSeatMovement 0 "No Driver Seat Movement" 1 "Driver Seat Movement" ;
VAL_ 394 DriverSeatMsgAvail 0 "Available" 1 "NOT available" ;
VAL_ 394 DrvSeatMasgIntStat 0 "StandBy Status" 1 "Intensity 1" 2 "Intensity 2" 3 "Intensity 3" 4 "Intensity 4" 5 "Intensity 5" 6 "Off" 7 "Unused" ;
VAL_ 394 DrvSeatMasgLocStat 0 "Off" 1 "Rolling" 2 "Up" 3 "Down" 4 "Shoulder" 5 "Lumbar" 6 "Undefined6" 7 "Undefined7" ;
VAL_ 394 DrvSeatMasgProgStat 0 "Off" 1 "Wave" 2 "Pulse" 3 "Pulse Duo" 4 "Combination" 5 "Hot" 6 "Undefined6" 7 "Undefined7" ;
VAL_ 394 DrvSeatMassageModeStat 0 "StandBy status(No button press)" 1 "Program 1" 2 "Program 2" 3 "Program 3" 4 "Massage OFF" 5 "Program 4" 6 "Program 5" 7 "Unused" ;
VAL_ 394 DrvSeatMovement2ndRow 0 "Seat stopped mid travel" 1 "Seat Fully folded" 2 "Seat Fully Unfolded" 3 "Seat moving" ;
VAL_ 394 DrvSeatMovement3rdRow 0 "Seat stopped mid travel" 1 "Seat Fully folded" 2 "Seat Fully Unfolded" 3 "Seat moving" ;
VAL_ 394 DrvSeatMovmnt2ndRow 0 "Default" 1 "Seat Fully folded" 2 "Seat Fully Unfolded" 3 "Seat mid travel (stationary)" 4 "Seat moving" ;
VAL_ 394 DrvSeatMovmnt3rdRow 0 "Default" 1 "Seat Fully folded" 2 "Seat Fully Unfolded" 3 "Seat mid travel (stationary)" 4 "Seat moving" ;
VAL_ 394 EasyEntryEnDisStatRear 0 "Default Value" 1 "Rear seat easy entry enable" 2 "Rear seat easy entry disabled" 3 "Unused" ;
VAL_ 394 ISCMFrontSeatMovntStat 0 "HLDF Status Front Seat Movement Disabled" 1 "HLDF Status Front Seat Movement Enabled" ;
VAL_ 394 RDSeatMovement 0 "No Driver Seat Movement" 1 "Driver Seat Movement" ;
VAL_ 394 Row1DriverMovementINH 0 "Not Inhibited" 1 "Movement Inhibited" ;
VAL_ 394 Row2DriverMovementINH 0 "Not Inhibited" 1 "Movement Inhibited" ;
VAL_ 394 Row3DriverMovementINH 0 "Not Inhibited" 1 "Movement Inhibited" ;
VAL_ 394 SeatMoveSelectFrStat 0 "Unused" 1 "Driver Seat" 2 "Passenger Seat" 3 "Rear Left Seat" 4 "Rear Right Seat" 5 "Rear Seat Showroom return" 6 "Rear Middle Seat (Power Arm Rest)" 7 "All Seats Show Room Return (Incl Front Seat)" ;
VAL_ 366 FTCM_Command 0 "Stop" 1 "Direct Position" 2 "Direct Drive Open" 3 "Direct Drive Close" 4 "Set Normalisation" 5 "Discard Normalisation" 6 "Reset Error Flags" 7 "Reserved" ;
VAL_ 366 FTCM_CtrlSignalState 0 "Inactive" 1 "Active" 2 "Error" ;
VAL_ 366 FTCM_Latch_CmdDiag 0 "Stop" 1 "Open" 2 "Close" ;
VAL_ 366 FTCM_Latch_Command 0 "Stop" 1 "Open" 2 "Close" ;
VAL_ 366 FTCM_OperationModeActive 0 "Inactive" 1 "Active" ;
VAL_ 366 FTCM_Target 0 "Close Target" 1 "ClosePosition" 2 "OpenPosition" 3 "OpenTarget" 4 "Reserved4" 5 "Reserved5" 6 "Reserved6" 7 "Reserved7" ;
VAL_ 366 FTCMCmdExt 0 "Normal" 1 "NoPwmNoAp" 2 "Teach" 3 "NoAdapt" 4 "ForceIncrease1" 5 "ForceIncrease2" 6 "ForceIncrease3" 7 "Reserved" ;
VAL_ 366 FTCMHoldModeActive 0 "Inactive" 1 "Active" ;
VAL_ 366 RoofPositionStatus 0 "Closed" 1 "Open" 2 "Closing" 3 "Opening" 4 "Stalled" ;
VAL_ 366 RoofPumpOperating 0 "Off" 1 "On" ;
VAL_ 366 RoofWarningMessage 0 "NoMessage" 1 "NotLatched" 2 "SpeedHigh" 3 "TooCold" 4 "Latched" 5 "TailgateOpen" 6 "Unassigned6" 7 "Unassigned7" ;
VAL_ 366 WindowOperationRoofRequest 0 "No Request" 1 "Close (Up)" 2 "Open (Down)" 3 "Undefined (Unused)" ;
VAL_ 367 FTCMB_ClosedRange_Active 0 "Inactive" 1 "Active" ;
VAL_ 367 FTCMB_CtrlSignal_State 0 "Inactive" 1 "Active" 2 "Error" ;
VAL_ 367 FTCMB_Error_Flags 1 "TOTALRUNTIMEEXCEED" 2 "TOTALRUNTIMEWARNING" 4 "ONEWAYRUNTIMEEXCEED" 8 "HALLSENSORERROR" 16 "POSITIONERROR" 32 "PINCHED" 64 "DIRECTION" 128 "STALL" 256 "RELAY_ERROR" ;
VAL_ 367 FTCMB_Finished 0 "StopByRequest" 1 "StopByStall" 2 "StopByPinch" 3 "StopByFault" 4 "StopByPositioning" 5 "RunoutComplete" 6 "NormalisingReady" 7 "DenormalisingReady" ;
VAL_ 367 FTCMB_Latch_Error_Flags 1 "TOTAL_RUNTIME_EXCEED" 2 "RELAY_ERROR" 4 "STALLED" ;
VAL_ 367 FTCMB_Latch_State 0 "Stopped" 1 "Opened" 2 "Closed" 3 "Moving" 4 "Error" ;
VAL_ 367 FTCMB_OpenRange_Active 0 "Inactive" 1 "Active" ;
VAL_ 367 FTCMB_SD_DL_C_State 0 "Inactive" 1 "Active" 2 "Error" ;
VAL_ 367 FTCMB_SD_DL_O_State 0 "Inactive" 1 "Active" 2 "Error" ;
VAL_ 367 FTCMB_SL_DL_E_State 0 "Inactive" 1 "Active" 2 "Error" ;
VAL_ 367 FTCMB_SlaveState 0 "Not OK" 1 "OK" 2 "Reserved2" 3 "Reserved3" ;
VAL_ 367 FTCMB_SP_FT_C_State 0 "Inactive" 1 "Active" 2 "Error" ;
VAL_ 367 FTCMB_State 0 "PositionCloseTarget" 1 "PositionClosePosition" 2 "PositionOpenPosition" 3 "PositionOpenTarget" 4 "PositionIntermediate" 5 "Moving" 6 "Error" 7 "NoNormalised" 8 "ShutdownComplete" 9 "Reserved9" 10 "Reserved10" 11 "Reserved11" 12 "Reserved12" 13 "Reserved13" 14 "Reserved14" 15 "Reserved15" ;
VAL_ 367 FTCMB_State_Flags 1 "MOVING" 2 "OPENING" 4 "POSITION_SAVED" 8 "PROFILE_VALID" 16 "NORMALISED" 32 "REVERSING_ACTIVE" ;
VAL_ 277 AutoTRStatus 0 "Off" 1 "On" ;
VAL_ 277 CanclAutoTrProgReq 0 "Program change permitted" 1 "Cancel program change" ;
VAL_ 277 ElPowerStatus 0 "KeepActive" 1 "WarningLowBatteryVolt" 2 "ShutDown" 3 "NotUsed" ;
VAL_ 277 PSDBActvDiagState 0 "PSDB diagnostics is not finished/not run" 1 "PSDB Active diagnostics is finshed." ;
VAL_ 277 RtnPrevProg 0 "No timeout occurred" 1 "Return to previous program" ;
VAL_ 277 TerrainModeReqExt 0 "Standard Mode " 1 "TR: Grass/Gravel/Snow / JDC: Winter Mode " 2 "Undefined2" 3 "TR: Sand" 4 "TR: Mud " 5 "TR: Rock Crawl" 6 "Dynamic Mode " 7 "Fail Safe Default " 8 "JDC: Comfort Mode" 9 "JDC/TR: Economy Mode" 10 "MEDIUM_FRICTION" 11 "ECO Plus" 12 "WADE" 13 "CONFIGURABLE" 14 "Undefined14" 15 "Undefined15" ;
VAL_ 277 TerrainModeReqStatus 0 "No user initiated change" 1 "Change initiated by user" 2 "User initiated change complete" 3 "Undefined" ;
VAL_ 277 TerrProgActv 0 "Standard Mode" 1 "TR: Grass/Gravel/Snow / JDC: Winter Mode" 2 "Undefined2" 3 "TR: Sand" 4 "TR: Mud" 5 "TR: Rock Crawl" 6 "Undefined6" 7 "Fail Safe Default(Auto TR cannot determine current terrain) " 8 "Undefined8" 9 "Undefined9" 10 "Undefined10" 11 "Undefined11" 12 "Undefined12" 13 "Undefined13" 14 "Undefined14" 15 "Undefined15" ;
VAL_ 299 AdaptDriBeamEnableSta 0 "DISABLE" 1 "ENABLE" ;
VAL_ 299 AdaptDriBeamMsgReq 0 "NONE" 1 "CAMERA" 2 "AUTO" 3 "RESERVED" ;
VAL_ 299 ADBOperationalStatus 0 "ADB is not Active" 1 "ADB is Active" 2 "ADB Operational" 3 "Error" ;
VAL_ 299 AdptDriBeamTellTaleReq 0 "Off" 1 "On" 2 "Reserved2" 3 "Reserved3" ;
VAL_ 299 AFSSystemFailure 0 " OK" 1 "FAULT" 2 "RESERVED1" 3 "RESERVED2" ;
VAL_ 299 AHBOperationalStatus 0 "AHB is not Active" 1 "AHB is Active" 2 "AHB Operational" 3 "Error" ;
VAL_ 299 AutoHighBeamEnableSta 0 "AHBC system disable by user" 1 "AHBC system enable by user" ;
VAL_ 299 AutoHighBeamMsgReq 0 "No message" 1 "Camera blocked" 2 "Auto" 3 "Reserved" ;
VAL_ 299 AutoHighBeamTTReq 0 "Off" 1 "On" 2 "Flash" 3 "Reserved" ;
VAL_ 299 HCMHighBeamTellTaleReg 0 "OFF" 1 "ON" ;
VAL_ 299 SupMainBeamEnableSta 0 "Disabled" 1 "Enabled" ;
VAL_ 426 LHHighBeamError 0 "No current test result" 1 "Test result : Failed" 2 "Test result : Passed" 3 "Unused" ;
VAL_ 426 LHHighBeamStatus 0 "Off" 1 "ON" 2 "ON via ADB" 3 "SNA (Service Not Available)" ;
VAL_ 426 LHLowBeamError 0 "No current test result" 1 "Test result : Failed" 2 "Test result : Passed" 3 "Unused" ;
VAL_ 426 LHLowBeamStatus 0 "OFF" 1 "ON" 2 "Unused" 3 "SNA (Service Not Available)" ;
VAL_ 426 RHHighBeamError 0 "No current test result" 1 "Test result : Failed" 2 "Test result : Passed" 3 "Unused" ;
VAL_ 426 RHHighBeamStatus 0 "Off" 1 "ON" 2 "ON via ADB" 3 "SNA (Service Not Available)" ;
VAL_ 426 RHLowBeamError 0 "No current test result" 1 "Test result : Failed" 2 "Test result : Passed" 3 "Unused" ;
VAL_ 426 RHLowBeamStatus 0 "OFF" 1 "ON" 2 "Unused" 3 "SNA (Service Not Available)" ;
VAL_ 701 AmbientLightValueHLDF 255 "Light sensor faulty i.e open circuit or short circuit etc" ;
VAL_ 701 DriveAwayLockingSw 0 "Drive away locking deactivated " 1 "Drive away locking speed 5 mph activated" 2 "Drive away locking speed 10 mph activated" 3 "Drive away locking speed 20 mph activated" ;
VAL_ 701 EasyEntryEnDisReqRear 0 "Default Value" 1 "Rear seat easy entry enable" 2 "Rear seat easy entry disabled" 3 "Unused" ;
VAL_ 701 HeadlampExitDelayReq 0 "0 Seconds (Off)" 1 "30 Seconds" 2 "60 Seconds" 3 "120 Seconds" 4 "240 Seconds" ;
VAL_ 701 ISCMFrontSeatMovement 0 "HLDF Front Seat Movement Disabled" 1 "HLDF Front Seat Movement Enabled" ;
VAL_ 701 LockChirpsReq 0 "LockChirps deactivated" 1 "LockChirps activated" ;
VAL_ 701 RainSenseReq 0 "Disabled" 1 "Enabled" ;
VAL_ 701 SeatMoveSelectFrReq 0 "Unused" 1 "Driver Seat" 2 "Passenger Seat" 3 "Rear Left Seat" 4 "Rear Right Seat" 5 "Rear Seat Showroom return" 6 "Rear Middle Seat (Power Arm Rest)" 7 "All Seats Show Room Return (Incl Front Seat)" ;
VAL_ 701 SensorOverrideSwitch 0 "Sensor Override Inactive" 1 "Sensor Override Active" ;
VAL_ 701 SkiHatchReq 0 "Default" 1 "Open Request" ;
VAL_ 701 TSPassSeatMemLoadReq 0 "Default" 1 "Memory 1 Load" 2 "Memory 2 Load" 3 "Memory 3 Load" ;
VAL_ 701 TSPassSeatMemStorReq 0 "Default" 1 "Memory 1 Store" 2 "Memory 2 Store" 3 "Memory 3 Store" ;
VAL_ 701 TSPassSeatMoveReq 0 "No Movement Request" 1 "Fold Request" 2 "Unfold Request" 3 "Stop Movement Request" 4 "Reserved" 5 "Full Passenger Seat Away" 6 "Reserved" 7 "Return to Upright Position" ;
VAL_ 701 TSRLSeatMemLoadReq 0 "Default" 1 "Memory 1 Load" 2 "Memory 2 Load" 3 "Memory 3 Load" ;
VAL_ 701 TSRLSeatMemStorReq 0 "Default" 1 "Memory 1 Store" 2 "Memory 2 Store" 3 "Memory 3 Store" ;
VAL_ 701 TSRRSeatMemLoadReq 0 "Default" 1 "Memory 1 Load" 2 "Memory 2 Load" 3 "Memory 3 Load" ;
VAL_ 701 TSRRSeatMemStorReq 0 "Default" 1 "Memory 1 Store" 2 "Memory 2 Store" 3 "Memory 3 Store" ;
VAL_ 702 TS2ndRowCntrMoveReq 0 "No Movement Request" 1 "Fold Request" 2 "Unfold Request" 3 "Stop Movement Request" 4 "Reserved" 5 "Deploy (Down) Request" 6 "Stow (Up) Request" ;
VAL_ 702 TS2ndRowLeftMoveReq 0 "Default" 1 "Seat Fully Folded" 2 "Seat Fully Unfolded" 3 "Seat Mid Travel (Stationary)" 4 "Seat Moving" 5 "One Touch Reclined" 6 "Fully Reclined" 7 "Returned to Home" ;
VAL_ 702 TS2ndRowRightMoveReq 0 "Default" 1 "Seat Fully Folded" 2 "Seat Fully Unfolded" 3 "Seat Mid Travel (Stationary)" 4 "Seat Moving" 5 "One Touch Reclined" 6 "Fully Reclined" 7 "Returned to Home" ;
VAL_ 702 TS3rdRowLeftMoveReq 0 "No Movement Request" 1 "Fold Request" 2 "Unfold Request" 3 "Stop Movement Request" ;
VAL_ 702 TS3rdRowRightMoveReq 0 "No Movement Request" 1 "Fold Request" 2 "Unfold Request" 3 "Stop Movement Request" ;
VAL_ 702 TSHRestMove2ndRLReq 0 "No Movement Request" 1 "Fold Request" 2 "Unfold Request" 3 "Stop Movement Request" ;
VAL_ 702 TSHRestMove2ndRMReq 0 "No Movement Request" 1 "Fold Request" 2 "Unfold Request" 3 "Stop Movement Request" ;
VAL_ 702 TSHRestMove2ndRRReq 0 "No Movement Request" 1 "Fold Request" 2 "Unfold Request" 3 "Stop Movement Request" ;
VAL_ 702 TSHRestMove3rdRLReq 0 "No Movement Request" 1 "Fold Request" 2 "Unfold Request" 3 "Stop Movement Request" ;
VAL_ 702 TSHRestMove3rdRRReq 0 "No Movement Request" 1 "Fold Request" 2 "Unfold Request" 3 "Stop Movement Request" ;
VAL_ 693 DriverSeatMassageReq 0 "Off" 1 "On" ;
VAL_ 693 DrvSeatMasgIntReq 0 "StandBy Status" 1 "Intensity 1" 2 "Intensity 2" 3 "Intensity 3" 4 "Intensity 4" 5 "Intensity 5" 6 "Off" 7 "Unused" ;
VAL_ 693 DrvSeatMasgLocReq 0 "Off" 1 "Rolling" 2 "Up" 3 "Down" 4 "Shoulder" 5 "Lumbar" 6 "Undefined6" 7 "Undefined7" ;
VAL_ 693 DrvSeatMasgProgReq 0 "Off" 1 "Wave" 2 "Pulse" 3 "Pulse Duo" 4 "Combination" 5 "Hot" 6 "Undefined6" 7 "Undefined7" ;
VAL_ 693 DrvSeatMassageModeReq 0 "StandBy status(No button press)" 1 "Program 1" 2 "Program 2" 3 "Program 3" 4 "Massage OFF" 5 "Program 4" 6 "Program 5" 7 "Unused" ;
VAL_ 693 PassSeatMasgIntReq 0 "StandBy Status" 1 "Intensity 1" 2 "Intensity 2" 3 "Intensity 3" 4 "Intensity 4" 5 "Intensity 5" 6 "Off" 7 "Unused" ;
VAL_ 693 PassSeatMasgLocReq 0 "Off" 1 "Rolling" 2 "Up" 3 "Down" 4 "Shoulder" 5 "Lumbar" 6 "Undefined6" 7 "Undefined7" ;
VAL_ 693 PassSeatMasgProgReq 0 "Off" 1 "Wave" 2 "Pulse" 3 "Pulse Duo" 4 "Combination" 5 "Hot" 6 "Undefined6" 7 "Undefined7" ;
VAL_ 693 PassSeatMassageModeReq 0 "StandBy status(No button press)" 1 "Program 1" 2 "Program 2" 3 "Program 3" 4 "Massage OFF" 5 "Program 4" 6 "Program 5" 7 "Unused" ;
VAL_ 693 PassSeatMassageReq 0 "Off" 1 "On" ;
VAL_ 693 RLSeatMasgIntReqFr 0 "StandBy Status" 1 "Intensity 1" 2 "Intensity 2" 3 "Intensity 3" 4 "Intensity 4" 5 "Intensity 5" 6 "Off" 7 "Unused" ;
VAL_ 693 RLSeatMasgLocReqFr 0 "Off" 1 "Rolling" 2 "Up" 3 "Down" 4 "Shoulder" 5 "Lumbar" 6 "Undefined6" 7 "Undefined7" ;
VAL_ 693 RLSeatMasgModeReqFr 0 "StandBy status(No button press)" 1 "Program 1" 2 "Program 2" 3 "Program 3" 4 "Massage OFF" ;
VAL_ 693 RLSeatMasgProgReqFr 0 "Off" 1 "Wave" 2 "Pulse" 3 "Pulse Duo" 4 "Combination" 5 "Hot" 6 "Undefined6" 7 "Undefined7" ;
VAL_ 693 RLSeatMasgReqFr 0 "Off" 1 "On" ;
VAL_ 693 RRSeatMasgIntReqFr 0 "StandBy Status" 1 "Intensity 1" 2 "Intensity 2" 3 "Intensity 3" 4 "Intensity 4" 5 "Intensity 5" 6 "Off" 7 "Unused" ;
VAL_ 693 RRSeatMasgLocReqFr 0 "Off" 1 "Rolling" 2 "Up" 3 "Down" 4 "Shoulder" 5 "Lumbar" 6 "Undefined6" 7 "Undefined7" ;
VAL_ 693 RRSeatMasgModeReqFr 0 "StandBy status(No button press)" 1 "Program 1" 2 "Program 2" 3 "Program 3" 4 "Massage OFF" ;
VAL_ 693 RRSeatMasgProgReqFr 0 "Off" 1 "Wave" 2 "Pulse" 3 "Pulse Duo" 4 "Combination" 5 "Hot" 6 "Undefined6" 7 "Undefined7" ;
VAL_ 693 RRSeatMasgReqFr 0 "Off" 1 "On" ;
SIG_GROUP_ 1281 BCM_NM501LS 1 : NMmessageBCMLS;
SIG_GROUP_ 763 CascadeIllumGrp 1 : CascadeIllumZone1 CascadeIllumZone2 CascadeIllumZone3 CascadeIllumZone4;
SIG_GROUP_ 255 CarModeGp_BO 1 : CarMode TransitState;
SIG_GROUP_ 255 PowerModeGp 1 : PowerMode PowerModeAliveCounter PowerModeChecksum PowerModeQF RemoteEngStartDrivPres RemoteFunctionStatus RemoteStartStatusMS;
SIG_GROUP_ 675 PASSIVE_WARNINGS 1 : StartAndBrakeWarning StartAndClutchWarning StartStop1Warning StartStop2Warning;
SIG_GROUP_ 677 AmbLightColourGrp 1 : AmbLightColourBlue AmbLightColourGreen AmbLightColourRed AmbLightColourZoneReq;
SIG_GROUP_ 677 AmbLightDynMode 1 : AmbLightDynModeStatus AmbLightUIDynAutoStat;
SIG_GROUP_ 677 AmbLightIntensityGrp 1 : AmbLightIntensityReqMS AmbLightIntZoneReqMS AmbLightProfileStat AmbLightRampRateReqMS;
SIG_GROUP_ 938 RemoteStartResultGp 1 : RESAlarmStatus RESBrakePedalStatus RESEngineRunningStatus RESHazardSwitchStatus RESSequenceStatus RESTransmissionStatus RESVehicleLockStatus RESVehStationaryStatus RESWindowStatus;
SIG_GROUP_ 420 BulbFailGp_PTCAN 1 : FLDirectionIndicatorBulbFail FRDirectionIndicatorBulbFail LeftStopLampBulbFailure RightStopLampBulbFailure RLDirectionIndicatorBulbFail RLPositionLampBulbFailure RRDirectionIndicatorBulbFail RRPositionLampBulbFailure;
SIG_GROUP_ 225 BCM_ENCRYPT_LOCKING_2 1 : CentralLockLastCmdOrig2 CentralLockStatus2 CLock_RC2 DriverDoorLockCmd FrontPassDoorLockCmd RearDriverDoorLockCmd RearPassDoorLockCmd;
SIG_GROUP_ 230 DirectionIndicationGp 1 : DirectionIndication DirectionIndicationINST TrailerDirectionInd;
SIG_GROUP_ 230 TrailerDIGp_BO 1 : TrailerDILeft TrailerDIRight TrailerStopLamp;
SIG_GROUP_ 1614 DevelopID_RGTM_Tx1 1 : DevID_RGTM_Tx1;
SIG_GROUP_ 1642 DevelopID_RGTMB_Tx1 1 : DevID_RGTMB_Tx1;
SIG_GROUP_ 1538 EOL_DCU_xTx1 1 : EOL_DCU_Tx1;
SIG_GROUP_ 1540 EOL_DCU_xTx2 1 : EOL_DCU_Tx2;
SIG_GROUP_ 1542 EOL_DCU_xTx3 1 : EOL_DCU_Tx3;
SIG_GROUP_ 1544 EOL_DCU_xTx4 1 : EOL_DCU_Tx4;
SIG_GROUP_ 1571 EOL_DCU_xTx5 1 : EOL_DCU_Tx5;
SIG_GROUP_ 1573 EOL_DCU_xTx6 1 : EOL_DCU_Tx6;
SIG_GROUP_ 1600 EOL_DCU_xTx7 1 : EOL_DCU_Tx7;
SIG_GROUP_ 1602 EOL_DCU_xTx8 1 : EOL_DCU_Tx8;
SIG_GROUP_ 1360 FTCM_NM550BO 1 : NMmessageFTCM;
SIG_GROUP_ 1363 FTCMB_NM553HS 1 : NMmessageFTCMB;
SIG_GROUP_ 277 TR1 1 : AutoTRStatus CanclAutoTrProgReq RtnPrevProg TerrProgActv;
